VERSION ""

NS_ :

BS_:

BU_: GW MHU IPC CCU
VAL_TABLE_ MHU_BTPairing 3 "BT Phone and Media" 2 "BT Phone" 1 "Apple CarPlay" 0 "Not active No connetced" ;
VAL_TABLE_ MHU_MaintenanceEvent 0 "No Maintenance Event" 1 " Maintenance Reminder " 2 "Reserved" 3 "Invalid" ;
VAL_TABLE_ MHU_Arrow 1 "DEPART(Start driving Used before accurate location or orientation is known)" 2 "NAME_CHANGE(Indicate a street name change without turn)" 3 "KEEP LEFT( Keep Left. Usually for bifurcations or other smooth maneuvers(compare to Slight Left Turn)" 4 "KEEP RIGHT( Keep right. Usually for bifurcations or other smooth maneuvers(compare to Slight rightTurn))" 5 "SLIGHT TURN _RIGHT(Make a 10-45 degree RIGHT turn)" 6 "SLIGHT TURN _LEFT(Make a 10-45 degree LEFTturn)" 7 "TURN _RIGHT(Make a 45-135 degree RIGHT turn)" 8 "TURN _LEFT(Make a 45-135 degree LEFT turn)" 9 "TURN _RIGHT_END(At the end of the road，turn right)" 10 "TURN _LEFT_END(At the end of the road，turn left)" 11 "SHARP_TURN_RIGHT(Make a 135-175 degree RIGHT turn)" 12 "SHARP_TURN_LEFT(Make a 135-175 degree LEFT turn)" 13 "U TURN_RIGHT(Make a 180 dearee RIGHT tum onto the same road)" 14 "U TURN_LEFT(Make a 180 dearee LEFT tum onto the same road)" 15 "ON RAMP_RIGHT(Take an RIGHT on-ramp onto a major road)" 16 "ON RAMP_LEFT(Take an LEFT on-ramp onto a major road)" 17 "OFF RAMP_RIGHT(Take an RIGHT off-ramp onto a major road)" 18 "OFF RAMP_LEFT(Take an LEFT off-ramp onto a major road)" 19 "FORK_RIGHT(Take a RIGHT fork while on a ramp)" 20 "FORK__LEFT(Take a LEFT fork while on a ramp)" 21 "MERGE(Merge with another road)" 22 "STRAIGHT(Indicates a potentially confusing intersection, in which the user is to proceed straight)" 23 "CONTINUE(Continue tp follow the road the vehicle is currently on)" 24 "FERRY_BOAT(Board a boat ferry)" 25 "ENTER FERRY" 26 "EXIT FERRY" 27 "CHANGE FERRY(Board a boat ferry)" 28 "FERRY_TRAIN(Board a train ferry(Google Maps display no icon))" 29 "CHANGE HIGH WAY _1( Change Highway. Highway to highway change with plied or unknown side Of the road)" 30 "CHANGE HIGH WAY _2( Change Highway. Highway to highway change with plied or unknown side Of the road)" 31 "CHANGE HIGH WAY _3( Change Highway Right. Highway to highway change from the right side of the road)" ;
VAL_TABLE_ MHU_SET_Second 63 "Invalid" ;
VAL_TABLE_ MHU_SET_Min 63 "Invalid" ;
VAL_TABLE_ MHU_SET_Hour 31 "Invalid" ;
VAL_TABLE_ MHU_SET_Day 0 "Invalid" ;
VAL_TABLE_ MHU_SET_Month 15 "Invalid" ;
VAL_TABLE_ MHU_SET_Year 255 "Invalid" ;
VAL_TABLE_ MHU_St_DimmingIPC 15 "Invalid" 14 "Level 15" 13 "Level 14" 12 "Level 13" 11 "Level 12" 10 "Level 11" 9 "Level 10" 8 "Level 9" 7 "Level 8" 6 "Level 7" 5 "Level 6" 4 "Level 5" 3 "Level 4" 2 "Level 3" 1 "Level 2" 0 "Level 1" ;
VAL_TABLE_ MHU_FavoriteFlag 1 "Active" 0 "Not active" ;
VAL_TABLE_ MHU_AMRadioFrequanceValue 16383 "Invalid" ;
VAL_TABLE_ MHU_FMRadioFrequanceValue 1023 "Invalid" ;
VAL_TABLE_ MHU_SourceStationMode_Reserved 15 "Resevered" 14 "Resevered" 13 "Resevered" 12 "Resevered" 11 "Resevered" 10 "Resevered" 9 "Resevered" 8 "AndroidAuto" 7 "Carplay" 6 "USB Picture" 5 "USB Vedio" 4 "USB Music" 3 "BT Music" 2 "FM" 1 "AM" 0 "None" ;
VAL_TABLE_ MHU_Route_Reserved 1 "ON" 0 "OFF" ;
VAL_TABLE_ MHU_MediaType 15 "Invaild" 8 "FM" 7 "AM" 6 "MUSIC" 5 "VIDEO" 4 "IMAGE" 3 "BT" 2 "AndroidAuto" 1 "CarPlay" 0 "None" ;
VAL_TABLE_ MHU_MediaStatus_Reserved 3 "Invaild" 2 "pause" 1 "playing" 0 "unready" ;
VAL_TABLE_ MHU_PhoneStatus 15 "Invalid" 8 "Hold current call" 7 "Missed call from" 6 "MUTE" 5 "ACTIVE" 4 "INCOMING" 3 "ALERTING" 2 "DIALING" 1 "IDLE" 0 "DISCONNECTED" ;
VAL_TABLE_ MHU_NaviType 3 "Invalid" 2 "AndroidAuto" 1 "CarPlay" 0 "Local" ;
VAL_TABLE_ MHU_NaviStatus 1 "Navigating" 0 "not Navigating" ;
VAL_TABLE_ MHU_Destination_Reachsts 3 "DESTINATION_RIGHT(Indicated arrival at destination,Destination is on right)" 2 "DESTINATION__LEFT(Indicated arrival at destination,Destination is on rleft)" 1 "DESTINATION_not reached(Arrive End Of Navigation Navigation has completed, but the rest of the journey will need to use another)" 0 "Inactive" ;
VAL_TABLE_ MHU_Compass 8 "SW" 7 "SE" 6 "S" 5 "W" 4 "NW" 3 "N" 2 "NE" 1 "E" 0 "inaction" ;
VAL_TABLE_ MHU_Roundabout 0 "Inactive" 1 "ROUNDABOUT_ENTER_RIGHT(Enter a large roundabout_RIGHT)" 2 "ROUNDABOUT_ENTER__LEFT(Enter a large roundabout_LEFT)" 3 "ROUNDABOUT_EXIT_RIGHT(Exit a large roundabout_RIGHT)" 4 "ROUNDABOUT_EXIT__LEFT(Exit a large roundabout__LEFT)" 5 "ROUNDABOUT_RIGHT1(Turn Angle（In Degreen）:1-67)" 6 "ROUNDABOUT_RIGHT2(Turn Angle（In Degreen）:68-112)" 7 "ROUNDABOUT_RIGHT3(Turn Angle（In Degreen）:113-157)" 8 "ROUNDABOUT_RIGHT4(Turn Angle（In Degreen）:158-202)" 9 "ROUNDABOUT_RIGHT5(Turn Angle（In Degreen）:203-247)" 10 "ROUNDABOUT_RIGHT6(Turn Angle（In Degreen）:248-292)" 11 "ROUNDABOUT_RIGHT7(Turn Angle（In Degreen）:293-337)" 12 "ROUNDABOUT_RIGHT8(Turn Angle（In Degreen）:338-360)" 13 "ROUNDABOUT_RIGHT9" 14 "ROUNDABOUT_RIGHT10" 15 "ROUNDABOUT_RIGHT11" 16 "ROUNDABOUT_RIGHT12" 17 "ROUNDABOUT_RIGHT13" 18 "ROUNDABOUT_RIGHT14" 19 "ROUNDABOUT_RIGHT15" 20 "ROUNDABOUT_RIGHT16" 21 "ROUNDABOUT_RIGHT17" 22 "ROUNDABOUT_RIGHT18" 23 "ROUNDABOUT_RIGHT19" 24 "ROUNDABOUT_LEFT1(Turn Angle（In Degreen）:1-67)" 25 "ROUNDABOUT_LEFT2(Turn Angle（In Degreen）:68-112)" 26 "ROUNDABOUT_LEFT3(Turn Angle（In Degreen）:113-157)" 27 "ROUNDABOUT_LEFT4(Turn Angle（In Degreen）:158-202)" 28 "ROUNDABOUT_LEFT5(Turn Angle（In Degreen）:203-247)" 29 "ROUNDABOUT_LEFT6(Turn Angle（In Degreen）:248-292)" 30 "ROUNDABOUT_LEFT7(Turn Angle（In Degreen）:293-337)" 31 "ROUNDABOUT_LEFT8(Turn Angle（In Degreen）:338-360)" 32 "ROUNDABOUT_LEFT9" 33 "ROUNDABOUT_LEFT10" 34 "ROUNDABOUT_LEFT11" 35 "ROUNDABOUT_LEFT12" 36 "ROUNDABOUT_LEFT13" 37 "ROUNDABOUT_LEFT14" 38 "ROUNDABOUT_LEFT15" 39 "ROUNDABOUT_LEFT16" 40 "ROUNDABOUT_LEFT17" 41 "ROUNDABOUT_LEFT18" 42 "ROUNDABOUT_LEFT19" ;
VAL_TABLE_ MHU_USBConnect 1 "USB connect" 0 "No USB connect" ;
VAL_TABLE_ MHU_MEDIA_MUTE 1 "Active" 0 "Not active" ;
VAL_TABLE_ MHU_PollutionReq 1 "Active" 0 "Inactive" ;
VAL_TABLE_ MHU_BSD_On 3 "Signal invalid" 2 "inactive" 1 "ON" 0 "OFF" ;
VAL_TABLE_ MHU_BSD_sens_Reserved 7 "invalid" 6 "Reserved" 5 "Reserved" 4 "Reserved" 3 "Inactive" 2 "Late" 1 "Normal" 0 "Early" ;
VAL_TABLE_ MHU_BSD_AudWarning 3 "Signal invalid" 2 "inactive" 1 "ON" 0 "OFF" ;
VAL_TABLE_ MHU_RCTA_On 3 "Signal invalid" 2 "inactive" 1 "ON" 0 "OFF" ;
VAL_TABLE_ MHU_RCTA_sens_Reserved 7 "invalid" 6 "Reserved" 5 "Reserved" 4 "Reserved" 3 "Inactive" 2 "Late" 1 "Normal" 0 "Early" ;
VAL_TABLE_ MHU_PA_On 3 "Signal invalid" 2 "inactive" 1 "ON" 0 "OFF" ;
VAL_TABLE_ MHU_DOW_Mode 3 "Signal invalid" 2 "inactive" 1 "ON" 0 "OFF" ;
VAL_TABLE_ MHU_DOW_sens_Reserved 7 "invalid" 6 "Reserved" 5 "Reserved" 4 "Reserved" 3 "Inactive" 2 "Late" 1 "Normal" 0 "Early" ;
VAL_TABLE_ MHU_DOW_AudWarning 3 "Signal invalid" 2 "inactive" 1 "ON" 0 "OFF" ;
VAL_TABLE_ MHU_SET_DoorSpeedLock 15 "Invalid" 14 "Reserved" 13 "Reserved" 12 "Reserved" 11 "Reserved" 10 "Reserved" 9 "Reserved" 8 "Reserved" 7 "Reserved" 6 "Inactive" 5 "25KMH" 4 "20KMH" 3 "15KMH" 2 "10KMH" 1 "5KMH" 0 "OFF" ;
VAL_TABLE_ MHU_SET_RemoteDoorUnlock_reserve 3 "Signal invalid" 2 "Reserved" 1 "All doors" 0 "Driver door" ;
VAL_TABLE_ MHU_SET_RemoteLockFeedback 7 "Signal Invalid" 6 "Reserved" 5 "Reserved" 4 "inactive" 3 "Horn" 2 "Light" 1 "Light/Horn" 0 "OFF" ;
VAL_TABLE_ MHU_SET_AutoUnlockDoor 7 "Invalid" 6 "Reserved" 5 "Reserved" 4 "Reserved" 3 "Reserved" 2 "Inactive" 1 "ON" 0 "OFF" ;
VAL_TABLE_ MHU_SET_MirrorAuto_reserved 3 "Signal invalid" 2 "Reserved" 1 "ON" 0 "OFF" ;
VAL_TABLE_ MHU_Anti_theftAlarmSet 7 "Invalid" 6 "Reserved" 5 "Reserved" 4 "inactive" 3 "Light/Horn" 2 "Horn" 1 "Light" 0 "OFF" ;
VAL_TABLE_ MHU_TriggerReadKey 3 "Signal Invalid" 2 "Reserved" 1 "Request" 0 "No Request" ;
VAL_TABLE_ MHU_Heatrearglass_Set 0 "OFF" 1 "ON" 2 "No action" 3 "Invalid" ;
VAL_TABLE_ MHU_SET_DayTimeRunningLight_rese 3 "Signal invalid" 2 "Reserved" 1 "ON" 0 "OFF" ;
VAL_TABLE_ MHU_SET_FollowMeHomeTime 7 "Invalid" 6 "Inactive" 5 "Reserved" 4 "120s" 3 "90s" 2 "60s" 1 "30s" 0 "OFF" ;
VAL_TABLE_ Rolling_Counter_0x403 15 "Invalid" ;
VAL_TABLE_ MHU_SET_TCS_OnOff 0 "OFF (keep sending for 2 seconds)" 1 "ON (keep sending for 2 seconds)" 2 "No action" 3 "Invalid" ;
VAL_TABLE_ MHU_SET_DrivingModeSwitch 3 "sport mode (should be hold during 1 second)" 2 "normal mode (should be hold during 1 second)" 1 "eco mode (should be hold during 1 second)" 0 "no change request" ;
VAL_TABLE_ MHU_SET_RegenLevel 3 "No action" 2 "High" 1 "Low" 0 "none" ;
VAL_TABLE_ MHU_VCU_CreepDisable_stt 0 "No request" 1 "Creep Disable request" 2 "Reserved" 3 "Invalid" ;
VAL_TABLE_ MHU_HVACTurnON 0 "No request" 1 "ON" 2 "Reserved" 3 "Invalid" ;
VAL_TABLE_ MHU_ChargeScheduleSet 0 "Disabled" 1 "Enabled" 2 "No Action" 3 "Reserved" ;
VAL_TABLE_ MHU_ChargingRequest 0 "Reserved" 1 "Request scheduled start charging" 2 "Request stop" 3 "No effect" ;
VAL_TABLE_ MHU_ValetMode_Activation 0 "Inactive" 1 "Active" 254 "Reserved" 255 "Invalid" ;
VAL_TABLE_ MHU_CCU_AC_Button 3 "Invalid" 1 "Press" 0 "Release" ;
VAL_TABLE_ MHU_REC_Button 3 "Invalid" 1 "Press" 0 "Release" ;
VAL_TABLE_ MHU_SetBlowMode 7 "Invalid" 6 "Reserve" 5 "Reserve" 4 "Foot and window" 3 "Foot" 2 "foot and face" 1 "face" 0 "Inactive" ;
VAL_TABLE_ MHU_BlowerLevelSetting 9 "level 8" 8 "level 7" 7 "level 6" 6 "level 5" 5 "level 4" 4 "level 3" 3 "level 2" 2 "level 1" 1 "OFF" 0 "Inactive" ;
VAL_TABLE_ MHU_SetDriverTemp 63 "Invalid" 16 "level 8" 15 "level 7" 14 "level 6" 13 "level 5" 12 "level 4" 11 "level 3" 10 "level 2" 9 "level 1" 8 "level 8" 7 "level 7" 6 "level 6" 5 "level 5" 4 "level 4" 3 "level 3" 2 "level 2" 1 "level 1" 0 "Inactive" ;
VAL_TABLE_ MHU_ACM_Reserved 3 "Invalid" 1 "Active" 0 "Inactive" ;
VAL_TABLE_ MHU_FrontDefrostReq_Reserved 3 "Invalid" 1 "Active" 0 "Inactive" ;
VAL_TABLE_ Rolling_Counter_0x422 15 "Invalid" ;
VAL_TABLE_ MHU_STAT_DateTimeFormat 3 "Signal invalid" 2 "Reserved" 1 "12H" 0 "24H" ;
VAL_TABLE_ MHU_DISPLAY_STATUS 0 "OFF" 1 "ON" 2 "Reserved" 3 "Invalid" ;
VAL_TABLE_ MHU_STAT_Language 31 "Signal invalid" 30 "Reserved" 29 "Reserved" 28 "Reserved" 27 "Reserved" 26 "Reserved" 25 "Reserved" 24 "Reserved" 23 "Reserved" 22 "Reserved" 21 "Reserved" 20 "Reserved" 19 "Reserved" 18 "Reserved" 17 "Reserved" 16 "Reserved" 15 "Reserved" 14 "Reserved" 13 "Reserved" 12 "Reserved" 11 "Reserved" 10 "Reserved" 9 "Reserved" 8 "Reserved" 7 "Reserved" 6 "Cambodia" 5 "Laos" 4 "Indonesian" 3 "Thai" 2 "Malay" 1 "English" 0 "Vietnamese" ;
VAL_TABLE_ TBOX_STAT_TerminalReq 7 "Signal invalid" 6 "No action" 5 "Reserved" 4 "SW Update OTA" 3 "Engine start (eMotor running)" 2 "ON (Driver Present)" 1 "ACC (Park)" 0 "OFF(Comfort Enable)" ;
VAL_TABLE_ REQ_ConsumerControlAudioVolumeCo 7 "signal invalid" 6 "Reserved" 5 "Reserved" 4 "Reserved" 3 "Reserved" 2 "Level 2" 1 "Level 1" 0 "No Reduction" ;
VAL_TABLE_ MHU_BCM_reqTrunk 3 "Signal invalid" 2 "No action" 1 "Open" 0 "Close reserved" ;
VAL_TABLE_ MHU_BCM_RemoteDoorCtrl 3 "Signal invalid" 2 "No action" 1 "Unlock" 0 "Lock" ;
VAL_TABLE_ MHU_APM_ReqWindow 2 "Open(Bottom) " 1 "Closed(Top)" 0 "No action" ;
VAL_TABLE_ MHU_SetHighBeam 1 "Request flashing" 2 "No request" 3 "Invalid" ;
VAL_TABLE_ MHU_SetHornOnOff 0 "OFF" 1 "ON" 2 "No action" 3 "Invalid" ;
VAL_TABLE_ MHU_SetLowBeam 0 "OFF" 1 "ON" 2 "No action" 3 "Invalid" ;
VAL_TABLE_ Rolling_Counter_0x432 15 "Invalid" ;
VAL_TABLE_ MHU_FOTA_State 0 "INIT" 1 "NORMAL" 2 "FOTA FLASHING" 3 "FOTA-SUSPENDED" 4 "FAIL-SAFE-ERROR" 5 "SHUTDOWN" 6 "REMOTE DIAGNOSTICS" 7 "Invalid" ;
VAL_TABLE_ XGW_FOTA_StateConfirm 0 "INIT" 1 "NORMAL" 2 "FOTA FLASHING" 3 "FOTA-SUSPENDED" 4 "FAIL-SAFE-ERROR" 5 "SHUTDOWN" 6 "REMOTE DIAGNOSTICS" 7 "Invalid" ;
VAL_TABLE_ BMS_MHU_Auth_Sts 2 "failed " 1 "pass " 0 "init" ;
VAL_TABLE_ IPC_Sec 63 "Invalid" ;
VAL_TABLE_ IPC_Min 63 "Invalid" ;
VAL_TABLE_ IPC_Hour 31 "Invalid" ;
VAL_TABLE_ IPC_Day 31 "Invalid" ;
VAL_TABLE_ IPC_Month 15 "Invalid" ;
VAL_TABLE_ IPC_Year 255 "Invalid" ;
VAL_TABLE_ IPC_SelfCheckStatus 1 "self-check finish" 0 "self-checking" ;
VAL_TABLE_ Rolling_Counter_0x20C 15 "Invalid" ;
VAL_TABLE_ IPC_ODO 1048575 "Invalid" ;
VAL_TABLE_ IPC_TripA 65535 "Invalid" ;
VAL_TABLE_ IPC_AverageSpeedTripA 4095 "Invalid" ;
VAL_TABLE_ IPC_AverageConsumptionTripA 1023 "Invalid" ;
VAL_TABLE_ IPC_ParkBrakeSts 3 "Invalid" 2 "Reserved" 1 "Applied" 0 "Released" ;
VAL_TABLE_ IPC_VehSpd 32767 "Invalid" ;
VAL_TABLE_ IPC_TripB 65535 "Invalid" ;
VAL_TABLE_ IPC_AverageSpeedTripB 4095 "Invalid" ;
VAL_TABLE_ IPC_AverageConsumptionTripB 1023 "Invalid" ;
VAL_TABLE_ IPC_TripAuto 65535 "Invalid" ;
VAL_TABLE_ IPC_AverageSpeedTripAuto 4095 "Invalid" ;
VAL_TABLE_ IPC_AverageConsumptionTripAuto 1023 "Invalid" ;
VAL_TABLE_ IPC_TireLearningReq_reserved 3 "Reserved" 2 "Reserved" 1 "Requset" 0 "No requset" ;
VAL_TABLE_ IPC_TireResetReq 3 "Reserved" 2 "Reserved" 1 "Requset to reset" 0 "No requset" ;
VAL_TABLE_ IPC_DimmingIPCLevel 15 "Invalid" 14 "Level 15" 13 "Level 14" 12 "Level 13" 11 "Level 12" 10 "Level 11" 9 "Level 10" 8 "Level 9" 7 "Level 8" 6 "Level 7" 5 "Level 6" 4 "Level 5" 3 "Level 4" 2 "Level 3" 1 "Level 2" 0 "Level 1" ;
VAL_TABLE_ CCU_TemperatureGearSts 63 "Invalid" 16 "level 8" 15 "level 7" 14 "level 6" 13 "level 5" 12 "level 4" 11 "level 3" 10 "level 2" 9 "level 1" 8 "level 8" 7 "level 7" 6 "level 6" 5 "level 5" 4 "level 4" 3 "level 3" 2 "level 2" 1 "level 1" 0 "Inactive" ;
VAL_TABLE_ CCU_BlowMode_Sts 7 "Invalid" 6 "Reserve" 4 "Foot and window" 3 "Foot" 2 "Foot and Face" 1 "Face" 0 "OFF" ;
VAL_TABLE_ CCU_Circulation_Sts 1 "Internal circulation" 0 "Outer circulation" ;
VAL_TABLE_ CCU_AC_Req 3 "Invalid" 2 "Reserved" 1 "Requset" 0 "No requset" ;
VAL_TABLE_ CCU_AC_Sts 1 "ON" 0 "OFF" ;
VAL_TABLE_ CCU_BlowerLevelSts 8 "level 8" 7 "level 7" 6 "level 6" 5 "level 5" 4 "level 4" 3 "level 3" 2 "level 2" 1 "level 1" 0 "OFF" ;
VAL_TABLE_ CCU_FrontDefrostSts 1 "On" 0 "Off" ;
VAL_TABLE_ CCU_PTC_Req 3 "Invalid" 2 "Reserved" 1 "Requset" 0 "No requset" ;
VAL_TABLE_ CCU_PTC_Temperature 1023 "Invaild" ;
VAL_TABLE_ CCU_CompSpdMEAS_Comp 8191 "Invalid" ;
VAL_TABLE_ CCU_PollutionSts 1 "ON" 0 "OFF" ;
VAL_TABLE_ CCU_ExternalTemperature 255 "Invaild" ;
VAL_TABLE_ CCU_evaporator_Temperature 31 "Invalid" ;
VAL_TABLE_ CCU_ExternalTemperatureFailSts 1 "invalid" 0 "valid" ;
VAL_TABLE_ USS_WorkSts 0 "Rear PAS Off" 1 "Rear PAS On" ;
VAL_TABLE_ USS_FrnSysSts_reserved 0 "Disable" 1 "Enable" 2 "Active" 3 "Failed" ;
VAL_TABLE_ USS_RearSysSts_reserved 0 "OFF" 1 "Enable" 2 "Active" 3 "Temporary Fault" 4 "Permanent Fault" ;
VAL_TABLE_ USS_SndCadComm 0 "Tone 0 - No warning" 1 "Front Level 1" 2 "Front Level 2" 3 "Front Level 3" 4 "Front Level 4" 5 "Front Level 5" 6 "Rear Level 1" 7 "Rear Level 2" 8 "Rear Level 3" 9 "Rear Level 4" 10 "Rear Level 5" 11 "Rear Level 6" 12 "Tone 10 - PAS & APA Check Normal Warning" 13 "Tone 11 - PAS & APA Check Fault Warning" 14 "Tone 12 - APA Warning tone/ Tone 12 -RRS Warning tone" 15 "Front and Rear Alternate alarm" ;
VAL_TABLE_ USS_LFDistance_reserved 0 "No obstacle" 1 "Zone 1" 2 "Zone 2" 3 "Zone3" ;
VAL_TABLE_ USS_RFDistance_reserved 0 "No obstacle" 1 "Zone 1" 2 "Zone 2" 3 "Zone3" ;
VAL_TABLE_ USS_LRDistance 0 "No obstacle" 1 "Zone 1" 2 "Zone 2" 3 "Zone3" 15 "Invalid" ;
VAL_TABLE_ USS_LMRDistance 0 "No obstacle" 1 "Zone 1" 2 "Zone 2" 3 "Zone 3" 4 "Zone 4" 5 "Zone 5" 15 "Invalid" ;
VAL_TABLE_ USS_RMRDistance 0 "No obstacle" 1 "Zone 1" 2 "Zone 2" 3 "Zone 3" 4 "Zone 4" 5 "Zone 5" 15 "Invalid" ;
VAL_TABLE_ USS_RRDistance 0 "No obstacle" 1 "Zone 1" 2 "Zone 2" 3 "Zone3" 15 "Invalid" ;
VAL_TABLE_ USS_PrkAssSysSta 0 "True" 1 "Fault" ;
VAL_TABLE_ USS_FLSenSta_reserved 0 " Sensor Normal" 1 " Sensor Fault" ;
VAL_TABLE_ USS_FRSenSta_reserved 0 " Sensor Normal" 1 " Sensor Fault" ;
VAL_TABLE_ USS_RLSenSta 0 " Sensor Normal" 1 " Sensor Fault" ;
VAL_TABLE_ USS_RRSenSta 0 " Sensor Normal" 1 " Sensor Fault" ;
VAL_TABLE_ USS_RLMSenSta 0 " Sensor Normal" 1 " Sensor Fault" ;
VAL_TABLE_ USS_RRMSenSta 0 " Sensor Normal" 1 " Sensor Fault" ;
VAL_TABLE_ USS_SetSta 0 " Unavailable" 1 " Off " 2 " On " 3 " Unused and Reserved" ;
VAL_TABLE_ Rolling_Counter_0x128 15 "Invalid" ;
VAL_TABLE_ ADAS_RCTA_IndLeft 0 "Indicator output off" 1 "Indicator On(warning stage - 1)" 2 "Indicator flashing(warning stage - 2)" 3 "Reserved" ;
VAL_TABLE_ ADAS_RCTA_IndRight 0 "Indicator output off" 1 "Indicator On(warning stage - 1)" 2 "Indicator flashing(warning stage - 2)" 3 "Reserved" ;
VAL_TABLE_ ADAS_RCTA_SndWarn 0 "Sound Warning disable" 1 "Left Sound Warning enable" 2 "Right Sound Warning enable" 3 "Left and Right Sound Warning enable" ;
VAL_TABLE_ ADAS_RCTA_check 0 "Available" 1 "Temporarily not available" 2 "Permanently not available" 3 "signal invalid" ;
VAL_TABLE_ ADAS_RCTA_state 0 "OFF State" 1 "Stand by state" 2 "Armed state" 3 "Warning stage" ;
VAL_TABLE_ ADAS_RCTA_sens_Feed_Reserved 0 "Early" 1 "Normal" 2 "Late" 3 "signal invalid" ;
VAL_TABLE_ ADAS_RCTA_Mode_Feed 0 "Off" 1 "On" 2 "Reserved" 3 "signal invalid" ;
VAL_TABLE_ Rolling_Counter_0x133 15 "Invalid" ;
VAL_TABLE_ ADAS_BSD_check 0 "Available" 1 "Temporarily not available" 2 "Permanently not available" 3 "signal invalid" ;
VAL_TABLE_ ADAS_BSD_state 0 "OFF State" 1 "Stand by state" 2 "Armed state" 3 "Warning" ;
VAL_TABLE_ ADAS_BSD_AudChime_Feed 0 "Off" 1 "On" 2 "Reserved" 3 "signal invalid" ;
VAL_TABLE_ ADAS_BSD_IndLeft 0 "Indicator output off" 1 "Indicator On(warning stage - 1)" 2 "Indicator flashing(warning stage - 2)" 3 "Sensor Fault" ;
VAL_TABLE_ ADAS_BSD_IndRight 0 "Indicator output off" 1 "Indicator On(warning stage - 1)" 2 "Indicator flashing(warning stage - 2)" 3 "Sensor Fault" ;
VAL_TABLE_ ADAS_BSD_SndWarn 0 "Sound Warning disable" 1 "Sound Warning enable" ;
VAL_TABLE_ ADAS_BSD_Mode_Feed 0 "Off" 1 "On" 2 "Reserved" 3 "signal invalid" ;
VAL_TABLE_ ADAS_BSD_sens_Feed 0 "Early" 1 "Normal" 2 "Late" 3 "signal invalid" ;
VAL_TABLE_ Rolling_Counter_0x352 15 "Invalid" ;
VAL_TABLE_ ADAS_DOW_Warn 0 "No Info" 1 "Left Warning" 2 "Right Warning" 3 "Left & Right Warning" ;
VAL_TABLE_ ADAS_DOW_SndWarn 0 "Sound Warning disable" 1 "Left Sound Warning enable" 2 "Right Sound Warning enable" 3 "Left and Right Sound Warning enable" ;
VAL_TABLE_ ADAS_DOW_state 0 "OFF State" 1 "Stand by state" 2 "Armed state" 3 "Warning stage" ;
VAL_TABLE_ ADAS_DOW_IndLeft 0 "Indicator output off" 1 "Indicator On(warning stage - 1)" 2 "Indicator flashing(warning stage - 2)" 3 "Sensor Fault" ;
VAL_TABLE_ ADAS_DOW_IndRight 0 "Indicator output off" 1 "Indicator On(warning stage - 1)" 2 "Indicator flashing(warning stage - 2)" 3 "Sensor Fault" ;
VAL_TABLE_ ADAS_DOW_sens_Feed_Reserved 0 "Early" 1 "Normal" 2 "Late" 3 "signal invalid" ;
VAL_TABLE_ ADAS_DOW_Mode_Feed 3 "signal invalid" 2 "Reserved" 1 "ON" 0 "OFF" ;
VAL_TABLE_ ADAS_DOW_AudChime_Feed 0 "Off" 1 "On" 2 "Reserved" 3 "signal invalid" ;
VAL_TABLE_ ADAS_DOW_check 0 "Available" 1 "Temporarily not available" 2 "Permanently not available" 3 "signal invalid" ;
VAL_TABLE_ Rolling_Counter_0x4C0 15 "Invalid" ;
VAL_TABLE_ ADAS_Warning_Flag_1 0 "No Error" 1 "Error" ;
VAL_TABLE_ ADAS_Warning_Flag_2 0 "No Error" 1 "Error" ;
VAL_TABLE_ ADAS_Warning_Flag_3 0 "No Error" 1 "Error" ;
VAL_TABLE_ ADAS_Warning_Flag_4 0 "No Error" 1 "Error" ;
VAL_TABLE_ ADAS_Warning_Flag_5 0 "No Error" 1 "Error" ;
VAL_TABLE_ ADAS_Warning_Flag_6 0 "No Error" 1 "Error" ;
VAL_TABLE_ ADAS_Warning_Flag_7 0 "No Error" 1 "Error" ;
VAL_TABLE_ ADAS_Warning_Flag_8 0 "No Error" 1 "Error" ;
VAL_TABLE_ ADAS_Warning_Flag_9 0 "No Error" 1 "Error" ;
VAL_TABLE_ ADAS_Warning_Flag_10 0 "No Error" 1 "Error" ;
VAL_TABLE_ ADAS_Warning_Flag_11 0 "No Error" 1 "Error" ;
VAL_TABLE_ ADAS_Warning_Flag_12 0 "No Error" 1 "Error" ;
VAL_TABLE_ ADAS_Warning_Flag_13 0 "No Error" 1 "Error" ;
VAL_TABLE_ ADAS_Warning_Flag_14 0 "No Error" 1 "Error" ;
VAL_TABLE_ ADAS_Warning_Flag_15 0 "No Error" 1 "Error" ;
VAL_TABLE_ ADAS_Warning_Flag_16 0 "No Error" 1 "Error" ;
VAL_TABLE_ ADAS_Warning_Flag_17 0 "No Error" 1 "Error" ;
VAL_TABLE_ ADAS_Warning_Flag_18 0 "No Error" 1 "Error" ;
VAL_TABLE_ ADAS_Warning_Flag_19 0 "No Error" 1 "Error" ;
VAL_TABLE_ ADAS_Warning_Flag_20 0 "No Error" 1 "Error" ;
VAL_TABLE_ ADAS_Warning_Flag_21 0 "No Error" 1 "Error" ;
VAL_TABLE_ ADAS_Warning_Flag_22 0 "No Error" 1 "Error" ;
VAL_TABLE_ ADAS_Warning_Flag_23 0 "No Error" 1 "Error" ;
VAL_TABLE_ ADAS_Warning_Flag_24 0 "No Error" 1 "Error" ;
VAL_TABLE_ ADAS_Warning_Flag_25 0 "No Error" 1 "Error" ;
VAL_TABLE_ ADAS_Warning_Flag_26 0 "No Error" 1 "Error" ;
VAL_TABLE_ ADAS_Warning_Flag_27 0 "No Error" 1 "Error" ;
VAL_TABLE_ ADAS_Warning_Flag_28 0 "No Error" 1 "Error" ;
VAL_TABLE_ Rolling_Counter_0x353 15 "Invalid" ;
VAL_TABLE_ ADAS_RadarRight_Cal_Status 0 "No Calib" 1 "Calib OK" ;
VAL_TABLE_ ADAS_RadarLeft_Cal_Status 0 "No Calib" 1 "Calib OK" ;
VAL_TABLE_ ADAS_RadarRight_DynaCal_Status 0 "In Calibrating" 1 "The absolute value of calibration angle is greater than 6 degrees" ;
VAL_TABLE_ ADAS_RadarLeft_DynaCal_Status 0 "In Calibrating" 1 "The absolute value of calibration angle is greater than 6 degrees" ;
VAL_TABLE_ ADAS_MasterSRR_check 0 "Available" 1 "Temporarily not available" 2 "Permanently not available" ;
VAL_TABLE_ ADAS_SlaveSRR_check 0 "Available" 1 "Temporarily not available" 2 "Permanently not available" ;
VAL_TABLE_ ADAS_CalSensorMasterProgress 255 "Invaild" ;
VAL_TABLE_ ADAS_CalSensorSlaverProgress 255 "Invalid" ;
VAL_TABLE_ Rolling_Counter_0x85 15 "Invalid" ;
VAL_TABLE_ ACM_Crash_Sts 3 "Invalid Value" 2 "Invalid Value" 1 "Crash_Detected" 0 "No_Event" ;
VAL_TABLE_ ACM_Airbag_Deployment_Status 3 "Invalid Value" 2 "Invalid Value" 1 "Airbag_Deployment" 0 "No_Airbag_Deployment" ;
VAL_TABLE_ ACM_Crash_Intensity 7 "Invalid_Value" 6 "Invalid_Value" 5 "Invalid_Value" 4 "Invalid_Value" 3 "Crash_Intensity_3" 2 "Crash_Intensity_2" 1 "Crash_Intensity_1" 0 "No_Crash" ;
VAL_TABLE_ ACM_Front_Crash 3 "Invalid Value" 2 "Invalid Value" 1 "Front_Crash_Detected" 0 "No_Event" ;
VAL_TABLE_ ACM_DriverSide_Crash 3 "Invalid Value" 2 "Invalid Value" 1 "Driverside_Crash_Detected" 0 "No_Event" ;
VAL_TABLE_ ACM_PassSide_Crash 3 "Invalid Value" 2 "Invalid Value" 1 "PassSide_Crash_Detected" 0 "No_Event" ;
VAL_TABLE_ ACM_Rear_Crash 3 "Invalid Value" 2 "Invalid Value" 1 "Rear_Crash_Detected" 0 "No_Event" ;
VAL_TABLE_ ACM_Rollover_Crash 3 "Invalid Value" 2 "Invalid Value" 1 "Rollover_Crash_Detected" 0 "No_Event" ;
VAL_TABLE_ Rolling_Counter_0x381 15 "Invalid" ;
VAL_TABLE_ ACM_Seat_Occupancy_Passenger 3 "Failure" 2 "Not_Available" 1 "Seat Occupied" 0 "Seat_Not_Occupied" ;
VAL_TABLE_ ACM_Seat_Occupancy_2nd_Row_Dri_r 3 "Failure" 2 "Not_Available" 1 "Seat Occupied" 0 "Seat_Not_Occupied" ;
VAL_TABLE_ ACM_Seat_Occupancy_2nd_Row_Pas_r 3 "Failure" 2 "Not_Available" 1 "Seat Occupied" 0 "Seat_Not_Occupied" ;
VAL_TABLE_ ACM_Seat_Occupancy_2nd_Row_Mid_r 3 "Failure" 2 "Not_Available" 1 "Seat Occupied" 0 "Seat_Not_Occupied" ;
VAL_TABLE_ ACM_Seat_Belt_Status_Passenger 3 "Failure" 2 "Not_Available" 1 "Buckled" 0 "Not_buckled" ;
VAL_TABLE_ ACM_Seat_Belt_Status_Driver 3 "Failure" 2 "Not_Available" 1 "Buckled" 0 "Not_buckled" ;
VAL_TABLE_ ACM_Seat_Belt_Status_2nd_Row_Dri 3 "Failure" 2 "Not_Available" 1 "Buckled" 0 "Not_buckled" ;
VAL_TABLE_ ACM_Seat_Belt_Status_2nd_Row_Mid 3 "Failure" 2 "Not_Available" 1 "Buckled" 0 "Not_buckled" ;
VAL_TABLE_ ACM_Seat_Belt_Status_2nd_Row_Pas 3 "Failure" 2 "Not_Available" 1 "Buckled" 0 "Not_buckled" ;
VAL_TABLE_ ACM_Seat_Belt_Status_3rd_Row_Dri 3 "Failure" 2 "Not_Available" 1 "Buckled" 0 "Not_buckled" ;
VAL_TABLE_ ACM_Seat_Belt_Status_3rd_Row_Pas 3 "Failure" 2 "Not_Available" 1 "Buckled" 0 "Not_buckled" ;
VAL_TABLE_ Rolling_Counter_0x488 15 "Invalid" ;
VAL_TABLE_ ACM_Malfunction 0 "ACM_Failure" 1 "ACM_Normal_Operation" ;
VAL_TABLE_ ACM_Pre_Drive_Check 0 "ACM_Pre_Drive_Check" 1 "ACM_Normal_Operation" ;
VAL_TABLE_ ACM_in_Plant_Mode 0 "ACM_in_Plant_Mode" 1 "ACM_in_Normal_Mode" ;
VAL_TABLE_ ACM_PAB_Suppression 0 "Not_Suppressed" 1 "Suppressed" 2 "Function Failure" 3 "Invalid_Value" ;
VAL_TABLE_ ACM_Airbag_Disabled 0 "ACM_AirBag_Disabled" 1 "ACM_Normal_Operation" ;
VAL_TABLE_ ACM_Development_Calibration 0 "ACM_Dev_Calibrated" 1 "ACM_Normal_Operation" ;
VAL_TABLE_ ACM_In_Disposal_Mode 0 "ACM_In_Disposal_Mode" 1 "ACM_Normal_Operation" ;
VAL_TABLE_ ACM_Seatbelt_Reminder_Request 0 "Seatbelt reminder NOT activated" 1 "Seatbelt reminder activated" ;
VAL_TABLE_ ACM_SBR_Chime_Req 0 "No Active Chime" 1 "Active Chime" ;
VAL_TABLE_ ACM_SBR_Blinking_Req 0 "No Blinking" 1 "Blinking 1Hz" ;
VAL_TABLE_ Rolling_Counter_0x105 15 "Invalid" ;
VAL_TABLE_ BCM_STAT_TrunkAjar 3 "Signal invalid" 2 "Reserved" 1 "Opened" 0 "Closed" ;
VAL_TABLE_ BCM_STAT_DoorAjarDriver 3 "Signal invalid" 2 "Reserved" 1 "Opened" 0 "Closed" ;
VAL_TABLE_ BCM_STAT_DoorAjarPassenger 3 "Signal invalid" 2 "Reserved" 1 "Opened" 0 "Closed" ;
VAL_TABLE_ BCM_STAT_DoorAjarRL 3 "Signal invalid" 2 "Reserved" 1 "Opened" 0 "Closed" ;
VAL_TABLE_ BCM_STAT_DoorAjarRR 3 "Signal invalid" 2 "Reserved" 1 "Opened" 0 "Closed" ;
VAL_TABLE_ BCM_STAT_BonnetAjar_reserved 3 "Signal invalid" 2 "Reserved" 1 "Opened" 0 "Closed" ;
VAL_TABLE_ Rolling_Counter_0x106 15 "Invalid" ;
VAL_TABLE_ BCM_HighBeamSts 0 "OFF" 1 "ON" 2 "Fault (Reserved)" 3 "Signal Invalid" ;
VAL_TABLE_ BCM_LowBeamSts 0 "OFF" 1 "ON" 2 "Fault (Reserved)" 3 "Signal Invalid" ;
VAL_TABLE_ BCM_PosLmpSts 0 "OFF" 1 "ON" 2 "Fault (Reserved)" 3 "Signal Invalid" ;
VAL_TABLE_ BCM_TurnIndicatorSts 0 "OFF" 1 "Left On" 2 "Right On" 3 "Left and Right On" ;
VAL_TABLE_ BCM_DayRunningLampSts_reserved 0 "OFF" 1 "ON" 2 "Fault (Reserved)" 3 "Signal Invalid" ;
VAL_TABLE_ BCM_ReverseLightSts 0 "OFF" 1 "ON" 2 "Fault (Reserved)" 3 "Signal Invalid" ;
VAL_TABLE_ BCM_StopLightSts 0 "OFF" 1 "ON" 2 "Fault (Reserved)" 3 "Signal Invalid" ;
VAL_TABLE_ BCM_Fr_Dimming_dome_lampSts 0 "OFF" 1 "ON" 2 "Fault (Reserved)" 3 "Signal Invalid" ;
VAL_TABLE_ BCM_Heated_rearglass 0 "OFF" 1 "ON" 2 "Fault (Reserved)" 3 "Signal Invalid" ;
VAL_TABLE_ BCM_BsdLightSts 0 "OFF" 1 "Left On" 2 "Right On" 3 "Left and Right On" ;
VAL_TABLE_ BCM_STAT_LightActivation 7 "Signal invalid" 6 "Reserved" 5 "Reserved" 4 "Reserved" 3 "AutoLight" 2 "LowBeam" 1 "PositionLight" 0 "OFF" ;
VAL_TABLE_ BCM_STAT_InteriorLight 3 "Signal invalid" 2 "Reserved" 1 "ON" 0 "OFF" ;
VAL_TABLE_ Rolling_Counter_0x10a 15 "Invalid" ;
VAL_TABLE_ BCM_LVTop_up 1 "start Top up" 0 "stop Top up" ;
VAL_TABLE_ Rolling_Counter_0x112 15 "Invalid" ;
VAL_TABLE_ STAT_Terminal 7 "Signal invalid" 6 "Reserved" 5 "Reserved" 4 "SW update OTA (Not used in VFe34)" 3 "Engine start (eMotor running)" 2 "ON (Driver Present)" 1 "ACC (Park)" 0 "OFF(Comfort Enable)" ;
VAL_TABLE_ STAT_CL30s_L_Reserved 3 "Signal invalid" 2 "Failure" 1 "ON" 0 "OFF" ;
VAL_TABLE_ Rolling_Counter_0x12f 15 "Invalid" ;
VAL_TABLE_ ST_KL_KEY_VLD 15 "Signal invalid" 14 "Error" 13 "Reserved" 12 "Reserved" 11 "Reserved" 10 "Reserved" 9 "Reserved" 8 "Reserved" 7 "Reserved" 6 "Reserved" 5 "Key 10sec delay" 4 "Key valid IR" 3 "Key valid AR" 2 "Key search activ" 1 "Key invalid" 0 "Init" ;
VAL_TABLE_ ST_SSP 3 "Signal invalid" 2 "Reserve" 1 "SSB pressed" 0 "SSB not pressed" ;
VAL_TABLE_ BCM_IMMO_Sts 2 "failed " 1 "pass " 0 "init" ;
VAL_TABLE_ BCM_ACCRelayOutputSts 0 "Inactive" 1 "Active" 2 "Reserved" 3 "Signal Invalid" ;
VAL_TABLE_ BCM_IGN1RelayOutputSts 0 "Inactive" 1 "Active" 2 "Reserved" 3 "Signal Invalid" ;
VAL_TABLE_ BCM_ACCRelayFalutSts 0 "No Fault" 1 "Fault" 2 "Reserved" 3 "Signal Invalid" ;
VAL_TABLE_ BCM_IGN1RelayFalutSts 0 "No Fault" 1 "Fault" 2 "Reserved" 3 "Signal Invalid" ;
VAL_TABLE_ BCM_KEY_MatchSts 0 "No Match" 1 "Match Success" 2 "Match Failed" 3 "Matching" ;
VAL_TABLE_ PEPS_Lock_IGNNotOff_Alert 1 "Active" 0 "Inactive" ;
VAL_TABLE_ PEPS_CID_NotInside_Alert 1 "Active" 0 "Inactive" ;
VAL_TABLE_ PEPS_CID_Left_Alert 1 "Active" 0 "Inactive" ;
VAL_TABLE_ PEPS_RMKey_BatteryLow_Alert 1 "Active" 0 "Inactive" ;
VAL_TABLE_ PEPS_PressBrakePedal_Alert 1 "Active" 0 "Inactive" ;
VAL_TABLE_ PEPS_Shift_Position_Alert 1 "Active" 0 "Inactive" ;
VAL_TABLE_ PEPS_Lock_KeyInside_Alert 1 "Active" 0 "Inactive" ;
VAL_TABLE_ PEPS_EmergencyStop_Reserved 3 "Invalid" 2 "Reserved" 1 "EmergencyStopMode" 0 "Normal" ;
VAL_TABLE_ PEPS_CID_NotIndenfied_Alert 1 "Active" 0 "InActive" ;
VAL_TABLE_ BCM_Positionlight_reminder 0 "Inactive" 1 "Active" 2 "Reserved" 3 "Signal Invalid" ;
VAL_TABLE_ RemoteAccessKey 15 "Invalid" 8 "Panic alarm press" 7 "Panic alarm long press" 6 "Long press unlock" 5 "Long press lock" 4 "Tailgate unlock" 3 "Tailgate unlock long press" 2 "Unlock" 1 "Lock" 0 "No command" ;
VAL_TABLE_ PassiveAccessTrunk 3 "Signal invalid" 2 "Reserved" 1 "Pressed" 0 "Not pressed" ;
VAL_TABLE_ BCM_CurrentValid_FOB 0 "No Valid FOB" 1 "FOB_1" 2 "FOB_2" 3 "FOB_3" 4 "FOB_4" 5 "Reserved" 6 "Reserved" 7 "Reserved" ;
VAL_TABLE_ BCM_STAT_RemoteLockFeedback 7 "Signal invalid" 6 "Reserved" 5 "Reserved" 4 "Inactive" 3 "Horn Only" 2 "Lights Only" 1 "Lights and Horn" 0 "OFF" ;
VAL_TABLE_ BCM_STAT_RemoteDoorUnlock_reserv 3 "Signal invalid" 2 "All doors" 1 "Driver door" 0 "Reserved" ;
VAL_TABLE_ BCM_STAT_AutoDoorUnlock 3 "Signal invalid" 2 "Reserved" 1 "ON" 0 "OFF" ;
VAL_TABLE_ BCM_STAT_DoorSpeedLock 7 "Signal invalid" 5 "25KMH" 4 "20KMH" 3 "15KMH" 2 "10KMH" 1 "5KMH" 0 "OFF" ;
VAL_TABLE_ BCM_STAT_DayTimeRunningLight_res 3 "Signal invalid" 2 "Reserved" 1 "ON" 0 "OFF" ;
VAL_TABLE_ BCM_STAT_AntiTheftMode 7 "Signal invalid" 3 "Light and Horn" 2 "Horn Only" 1 "Light Only" 0 "OFF" ;
VAL_TABLE_ BCM_FOBID_userprofile_link 5 "Searching" 4 "No key found" 3 "key illegal" 2 "Fob2" 1 "Fob1" 0 "No trigger from MHU" ;
VAL_TABLE_ BCM_feedback_FollowMeHomeTime 4 "120s" 3 "90s" 2 "60s" 1 "30s" 0 "OFF" ;
VAL_TABLE_ Rolling_Counter_0x107 15 "Invalid" ;
VAL_TABLE_ STAT_ATWS 7 "Signal invalid" 6 "Reserved" 5 "Reserved" 4 "Security Failure" 3 "Partly secured" 2 "Alarm" 1 "Unsecured" 0 "Secured" ;
VAL_TABLE_ STAT_DoorLockDriver 3 "Signal invalid" 2 "Reserved" 1 "Locked" 0 "Unlocked" ;
VAL_TABLE_ Rolling_Counter_0x10C 15 "Invalid" ;
VAL_TABLE_ BCM_TboxAuthStatus 0 "Have not learn. Not allow action" 1 "PASSED" 2 "FALIED: Authentication fail" 3 "Invalid" ;
VAL_TABLE_ Rolling_Counter_0x110 15 "Invalid" ;
VAL_TABLE_ BCM_APM_FLWIN_Postion 7 "Reserved" 6 "closing" 5 "opening" 4 "Open-80%（Bottom to 80%）" 3 "80%-Close(80% to Top) " 2 "Open(Bottom) " 1 "Closed(Top)" 0 "NotActive" ;
VAL_TABLE_ BCM_APM_FRWIN_Postion 7 "Reserved" 6 "closing " 5 "opening" 4 "Open-80%（Bottom to 80%）" 3 "80%-Close(80% to Top) " 2 "Open(Bottom) " 1 "Closed(Top)" 0 "NotActive" ;
VAL_TABLE_ BCM_APM_RLWIN_Postion 7 "Reserved" 6 "closing " 5 "opening" 4 "Open-80%（Bottom to 80%）" 3 "80%-Close(80% to Top) " 2 "Open(Bottom) " 1 "Closed(Top)" 0 "NotActive" ;
VAL_TABLE_ BCM_APM_RRWIN_Postion 7 "Reserved" 6 "closing " 5 "opening" 4 "Open-80%（Bottom to 80%）" 3 "80%-Close(80% to Top) " 2 "Open(Bottom) " 1 "Closed(Top)" 0 "NotActive" ;
VAL_TABLE_ APM_Status 1 "Error" 0 "No Error" ;
VAL_TABLE_ ChildProtectionStatus 3 "Invaild" 2 "Reserved" 1 "ON" 0 "OFF" ;
VAL_TABLE_ APM_Window_DriveSW_FL_Status 5 "Reserved" 4 "Auto up" 3 "Manual up " 2 "OFF " 1 "Manual down" 0 "Auto down" ;
VAL_TABLE_ APM_Window_DriveSW_FR_Status 7 "Reserved" 6 "Reserved" 5 "Reserved" 4 "Manual up (Reserved Auto up)" 3 "Manual up " 2 "OFF " 1 "Manual down" 0 "Auto down" ;
VAL_TABLE_ APM_Window_DriveSW_RL_Status 7 "Reserved" 6 "Reserved" 5 "Reserved" 4 "Manual up (Reserved Auto up)" 3 "Manual up " 2 "OFF " 1 "Manual down" 0 "Auto down" ;
VAL_TABLE_ APM_Window_DriveSW_RR_Status 7 "Reserved" 6 "Reserved" 5 "Reserved" 4 "Manual up (Reserved Auto up)" 3 "Manual up " 2 "OFF " 1 "Manual down" 0 "Auto down" ;
VAL_TABLE_ APM_Window_PassengerSW_Status 7 "Reserved" 6 "Reserved" 5 "Reserved" 4 "Manual up (Reserved Auto up)" 3 "Manual up " 2 "OFF " 1 "Manual down" 0 "Auto down" ;
VAL_TABLE_ APM_Window_PassengerSW_RL_Status 7 "Reserved" 6 "Reserved" 5 "Reserved" 4 "Manual up (Reserved Auto up)" 3 "Manual up " 2 "OFF " 1 "Manual down" 0 "Auto down" ;
VAL_TABLE_ APM_Window_PassengerSW_RR_Status 7 "Reserved" 6 "Reserved" 5 "Reserved" 4 "Manual up (Reserved Auto up)" 3 "Manual up " 2 "OFF " 1 "Manual down" 0 "Auto down" ;
VAL_TABLE_ Rolling_Counter_0x20D 15 "Invalid" ;
VAL_TABLE_ BCM_ODO 1048575 "Invalid" ;
VAL_TABLE_ Rolling_Counter_0x342 15 "Invalid" ;
VAL_TABLE_ ABS_LRWhlSpdRaw 32767 "Invalid" ;
VAL_TABLE_ ABS_LRWhlSpdRawValid 1 "Valid" 0 "Invalid" ;
VAL_TABLE_ ABS_RRWhlSpdRaw 32767 "Invalid" ;
VAL_TABLE_ ABS_RRWhlSpdRawValid 1 "Valid" 0 "Invalid" ;
VAL_TABLE_ ABS_VehSpd 32767 "Invalid" ;
VAL_TABLE_ ABS_VehSpdValid 1 "Valid" 0 "Invalid" ;
VAL_TABLE_ RollingCounter_0x132 15 "Invalid" ;
VAL_TABLE_ ESC_HSA_Control_Status 1 "active" 0 "inactive" ;
VAL_TABLE_ ESC_HSA_Status_Fault 1 " HSA Defective" 0 "HSA Normale" ;
VAL_TABLE_ ESC_TcsDisableSts 3 "signal invalid" 2 "reservred" 1 "disabled" 0 "enabled" ;
VAL_TABLE_ ESC_TcsCtrlActv 1 "active" 0 "inactive" ;
VAL_TABLE_ ESC_TcsFlgFlt 1 "failure" 0 "no failure" ;
VAL_TABLE_ ESC_EscDisableSts 1 "disabled" 0 "enabled" ;
VAL_TABLE_ ESC_EscCtrlActv 1 "active" 0 "inactive" ;
VAL_TABLE_ ESC_EscFlgFlt 1 "failure" 0 "no failure" ;
VAL_TABLE_ ESC_HBAFlgFlt 1 "failure" 0 "no failure" ;
VAL_TABLE_ ESC_HbaCtrlActv 1 "active" 0 "inactive" ;
VAL_TABLE_ ESC_SlopeGradeAngle 255 "Invalid" ;
VAL_TABLE_ ESC_MasterCylinderPressure 4095 "Invalid" ;
VAL_TABLE_ RollingCounter_0x142 15 "Invalid" ;
VAL_TABLE_ AbsDiagSessionLampReq_Reserved 1 "lamp on" 0 "lamp off" ;
VAL_TABLE_ ABS_AbsCtrlActv 1 "active" 0 "inactive" ;
VAL_TABLE_ ABS_EbdFlgFlt 1 "failure" 0 "no failure" ;
VAL_TABLE_ ABS_AbsFlgFlt 1 "failure" 0 "no failure" ;
VAL_TABLE_ ABS_ESS_Active 1 "active" 0 "inactive" ;
VAL_TABLE_ ABS_LowBrakeFluid 1 "failure" 0 "no failure" ;
VAL_TABLE_ RollingCounter_0x3E2 15 "Invalid" ;
VAL_TABLE_ ESC_LateralACC 255 "Invalid" ;
VAL_TABLE_ ESC_LateralACC_Valid 1 "Valid" 0 "Invalid" ;
VAL_TABLE_ ESC_LongitudeACC 1023 "Invalid" ;
VAL_TABLE_ ESC_LongitudeACC_Valid 1 "Valid" 0 "Invalid" ;
VAL_TABLE_ ESC_VehDynYawRate 16383 "Invalid" ;
VAL_TABLE_ ESC_VehDynYawRate_Valid 1 "Valid" 0 "Invalid" ;
VAL_TABLE_ ESC_FLTirePressAlarm 1 "Pressure warning" 0 "No warning" ;
VAL_TABLE_ ESC_FRTirePressAlarm 1 "Pressure warning" 0 "No warning" ;
VAL_TABLE_ ESC_RLTirePressAlarm 1 "Pressure warning" 0 "No warning" ;
VAL_TABLE_ ESC_RRTirePressAlarm 1 "Pressure warning" 0 "No warning" ;
VAL_TABLE_ ESC_iTPMS_Err 1 "Error" 0 "No error" ;
VAL_TABLE_ ESC_iTPMS_WarnLampAct 1 "Active" 0 "Inactive" ;
VAL_TABLE_ ESC_iTPMSResetProhibit 3 "prohibit 3 (System error)" 2 "prohibit 2 (Vehicle speed >0 km/h)" 1 "prohibit 1 (Tire statue is changing)" 0 "Not prohibit" ;
VAL_TABLE_ ESC_iTPMSResetSts 4 "Reset fail" 3 "Reset finish" 2 "Reset ongoing" 1 "Reset start" 0 "Idle" ;
VAL_TABLE_ SAS_SteerWheelAngle 65535 "Invalid" ;
VAL_TABLE_ SAS_SteeringAngleValid 1 "Valid" 0 "Invalid" ;
VAL_TABLE_ SAS_SASStsSnsr 1 "sensor value valid" 0 "sensor value Invalid" ;
VAL_TABLE_ SAS_SteerWhlRotSpd 16383 "Invalid" ;
VAL_TABLE_ SAS_SteerWhlRotSpdStatus 1 "Valid" 0 "Invalid" ;
VAL_TABLE_ SAS_SASFailure 1 "No Failure" 0 "Failure" ;
VAL_TABLE_ EPS_EpsFailed 1 "failed" 0 "not failed" ;
VAL_TABLE_ Rolling_Counter_0x2A1 15 "Invalid" ;
VAL_TABLE_ ODS_Status 3 "Reserved" 2 "ODS disconnected" 1 "Seat Occupied" 0 "Seat Not Occupied" ;
VAL_TABLE_ EVCC_MHU_CharSchSetFeedBack 3 "invalid " 2 "No Schedule" 1 "Schedule Success" 0 "No action" ;
VAL_TABLE_ EVCC_ChargeGunSts 1 "Plug In" 0 "no Plug in" ;
VAL_TABLE_ EVCC_ChargeMode 2 "DC Mode " 1 "AC Mode " 0 "Default" ;
VAL_TABLE_ EVCC_CP_Sts 12 "F~" 11 "E~" 10 "D~" 9 "C~" 8 "B~" 7 "A~" 6 "F" 5 "E" 4 "D" 3 "C" 2 "B" 1 "A" 0 "No CP" ;
VAL_TABLE_ EVCC_PP_Value 7 "CC GND" 6 "1500" 5 "680" 4 "220" 3 "100" 2 "Connection" 1 "Half Connection " 0 "No Connection" ;
VAL_TABLE_ EVCC_Lock_Sts 4 "Error" 3 "Unlocking" 2 "Locked" 1 "Locking " 0 "Unlock" ;
VAL_TABLE_ EAC_CompElecCurrV 0 "Valid" 1 "Invalid" ;
VAL_TABLE_ EAC_CompStat 0 "Normal Operation" 1 "Degraded Operation" 2 "Inoperative" 15 "Invalid" ;
VAL_TABLE_ EAC_CompElecPwrV 0 "Valid" 1 "Invalid" ;
VAL_TABLE_ EAC_CompSpdIncrReq 0 "False" 1 "True" ;
VAL_TABLE_ EAC_CompSpdV 0 "Valid" 1 "Invalid" ;
VAL_TABLE_ EAC_CompElecPwr 255 "Invaild" ;
VAL_TABLE_ EAC_CompSpd 16383 "Invaild" ;
VAL_TABLE_ EAC_CompElecCurr 255 "Invaild" ;
VAL_TABLE_ EAC_CompFltStat 0 "No Fault" 1 "Under Voltage" 2 "Over Voltage" 3 "Over Temperature" 4 "Input Control" 5 "Current Fault" 6 "Internal Fault" 8 "Motor slip protection" 9 "HVDC input voltage drop protection" 10 "Inside the controller 15V control power supply output undervoltage protection" 11 "Overcurrent frequency limitation and frequency reduction" 15 "Invalid" ;
VAL_TABLE_ VCU_PTC_RelaySts 1 "close" 0 "open" ;
VAL_TABLE_ VCU_EACEnbReq 1 "Enable" 0 "Disable" ;
VAL_TABLE_ VCU_EACAllowedPower 1023 "Invalid" ;
VAL_TABLE_ VCU_EAC_CompSpdReq 16383 "Invaild" ;
VAL_TABLE_ VCU_DriveCoolWaterPumpSts 5 "Reserved" 4 "Other error" 3 "Overtemperature" 2 "Locked-rotor" 1 "Idle" 0 "Normal" ;
VAL_TABLE_ VCU_DriveCoolWaterDuty 127 "Invalid" ;
VAL_TABLE_ VCU_BatteryWaterPumpSts_reserved 5 "Reserved" 4 "Other error" 3 "Overtemperature" 2 "Locked-rotor" 1 "Idle" 0 "Normal" ;
VAL_TABLE_ VCU_BatteryWaterPumpDuty_reserve 127 "Invalid" ;
VAL_TABLE_ VCU_DriveMode 7 "Invalid" 6 "Reserved" 5 "Reserved" 4 "Reserved" 3 "Reserved" 2 "Sport mode" 1 "ECO mode" 0 "Normal mode" ;
VAL_TABLE_ VCU_ActualGear 7 "Fault" 6 "Reserved" 5 "Reserved" 4 "Reserved" 3 "D" 2 "N" 1 "R" 0 "P reserved" ;
VAL_TABLE_ VCU_ACTGearValid 1 "nvalid" 0 "Valid" ;
VAL_TABLE_ VCU_AccPedal1OutRange 1 "Error" 0 "Normal" ;
VAL_TABLE_ VCU_AccPedal2OutRange 1 "Error" 0 "Normal" ;
VAL_TABLE_ VCU_BrkPedal1OutRange 1 "Error" 0 "Normal" ;
VAL_TABLE_ VCU_BrkPedal2OutRange 1 "Error" 0 "Normal" ;
VAL_TABLE_ VCU_BrkPedalPct 255 "Invalid" ;
VAL_TABLE_ VCU_AccPedalPosition 255 "Invalid" ;
VAL_TABLE_ VCU_AccPedalPositionValid 1 "Invalid" 0 "Valid" ;
VAL_TABLE_ VCU_SocDisplay_EST 127 "Invalid" ;
VAL_TABLE_ VCU_PowerLimit 1 "Limit" 0 "No Limit" ;
VAL_TABLE_ VCU_CruiseCtrlSts 3 "takeover mode" 2 "Pre cruise(lamp flash)" 1 "Cruise on(lamp on)" 0 "Cruise off(lamp off)" ;
VAL_TABLE_ VCU_LowSOC_ERR 1 "Error" 0 "No Error" ;
VAL_TABLE_ VCU_RegenLevel_Feed 3 "invalid" 2 "High" 1 "Low" 0 "none" ;
VAL_TABLE_ VCU_RBCSts 1 "active" 0 "incative" ;
VAL_TABLE_ VCU_RDCSts 1 "active" 0 "incative" ;
VAL_TABLE_ VCU_Veh_ERR 1 "Error" 0 "Normal" ;
VAL_TABLE_ VCU_DrvSys_ERR 1 "Error" 0 "Normal" ;
VAL_TABLE_ VCU_PackSys_ERR 1 "Error" 0 "Normal" ;
VAL_TABLE_ VCU_TBOX_Veh_STS_Reserved 3 "Other" 2 "Off" 1 "Start" 0 "Invalid" ;
VAL_TABLE_ VCU_VehChg_STS 3 "Charge fault" 2 "Charging complete" 1 "Charging in progress" 0 "Charging not in progress" ;
VAL_TABLE_ VCU_BatterVoltage_Reserved 255 "Invalid" ;
VAL_TABLE_ VCU_BatteryVoltErr_Reserved 1 "warning" 0 "no warning" ;
VAL_TABLE_ VCU_MotorCoolingCircuitErr_Reser 1 "Error" 0 "Normal" ;
VAL_TABLE_ VCU_PackCoolingCircuitErr_Reserv 1 "Error" 0 "Normal" ;
VAL_TABLE_ VCU_VehicleHVStatus 3 "Reserved" 2 "ReadyToDrive" 1 "HV On" 0 "Not ready" ;
VAL_TABLE_ VCU_InstantPowerConsump 1023 "Invalid" ;
VAL_TABLE_ VCU_AveragePowerConsump 1023 "Invalid" ;
VAL_TABLE_ VCU_BrakePedalSts 3 "Invalid" 2 "Reserved" 1 "pressed" 0 "Not pressed" ;
VAL_TABLE_ VCU_IMMO_Sts 2 "failed " 1 "pass " 0 "init" ;
VAL_TABLE_ VCU_DCDCAllowedPower 511 "Invalid" ;
VAL_TABLE_ VCU_Shift_ERR 1 "Error" 0 "Normal" ;
VAL_TABLE_ VCU_VehicleDischargePower 127 "Invalid" ;
VAL_TABLE_ VCU_VehicleChargePower 127 "Invalid" ;
VAL_TABLE_ Rolling_Counter_0x3E0 15 "Invalid" ;
VAL_TABLE_ VCU_MHU_Ack_ChgSche_stt 0 "Disabled" 1 "Enabled" 2 "Reserved" 3 "Invalid" ;
VAL_TABLE_ VCU_MHU_GuestMode_sts 0 "OFF" 1 "ON" 2 "Reserved" 3 "Reserved" ;
VAL_TABLE_ VCU_ValetMode_sts 0 "Inactive" 1 "Active" 255 "Invalid" ;
VAL_TABLE_ VCU_CreepDisable_stt 0 "Enable" 1 "Disable" ;
VAL_TABLE_ Rolling_Counter_0x2E9 15 "Invalid" ;
VAL_TABLE_ VCU_SetCruiseSpd 255 "Invalid" ;
VAL_TABLE_ Rolling_Counter_0x216 15 "Invalid" ;
VAL_TABLE_ BMS_RemainChargeTime 16383 "Invalid" ;
VAL_TABLE_ BMS_ChgVoltage_REQ 16383 "Invalid" ;
VAL_TABLE_ BMS_ChgCurrent_REQ 65535 "Invalid" ;
VAL_TABLE_ Rolling_Counter_0x215 15 "Invalid" ;
VAL_TABLE_ BMS_SOE 255 "Invalid" ;
VAL_TABLE_ BMS_HWCrash_Sts 1 "Crash " 0 "No Crash" ;
VAL_TABLE_ BMS_HVIL_STS 2 "short to ground" 1 "Open & short to battery" 0 "Closed" ;
VAL_TABLE_ BMS_IGN_Sts 1 "ON " 0 "OFF" ;
VAL_TABLE_ BMS_Sys_STS 8 "Invalid" 7 "Failure, unable to operate" 6 "BCU Sleep mode" 5 "Successful Power Down" 4 "Power Down process" 3 "Successful Power Down of HV" 2 "Successful High Voltage Power Up" 1 "Self-check passes, can be high-voltage" 0 "Initialization of power on, self-checking" ;
VAL_TABLE_ BMS_HVOnOff_STS 3 "Fail to HV on " 2 "HV On " 1 "Precharge " 0 "HV Off" ;
VAL_TABLE_ BMS_Balance_STS 1 "active " 0 "Inactive" ;
VAL_TABLE_ BMS_SocActual_EST 1023 "Invalid" ;
VAL_TABLE_ BMS_BatBalance_ERR 1 "normal " 0 "Error" ;
VAL_TABLE_ BMS_ISU_Status 3 "Level3(<100 Ohms/V)" 2 "Level2(<200 Ohms/V)" 1 "Level1 <500 Ohms/V ~ >200 Ohms/V" 0 "Normal (> 500 Ohms/V)" ;
VAL_TABLE_ BMS_ERR_LEV 7 "Battery locked -Reserved" 6 "Fault, needs Shutdown and Wakeup" 5 "Emergency off condition" 4 "Delayed power down with FTTI" 3 "Power down without FTTI" 2 "Limp Home" 1 " Warning (any warning in system)" 0 "No error" ;
VAL_TABLE_ BMS_SOH 255 "Invalid" ;
VAL_TABLE_ BMS_HV_Sts 4 "AC Charge" 3 "Super Fast Charge" 2 "HV ON" 1 "Precharge" 0 "HV Off" ;
VAL_TABLE_ BMS_DischargeCurrent_Limited 1 "Limited" 0 "Not Limited " ;
VAL_TABLE_ BMS_Warning_Flag_Reserved_07 1 "Warning" 0 "No warning" ;
VAL_TABLE_ BMS_Warning_Flag_Reserved_11 1 "Warning" 0 "No warning" ;
VAL_TABLE_ BMS_Warning_Flag_Reserved_10 1 "Warning" 0 "No warning" ;
VAL_TABLE_ BMS_Warning_Flag_Reserved_09 1 "Warning" 0 "No warning" ;
VAL_TABLE_ BMS_Warning_Flag_Reserved_13 1 "Warning" 0 "No warning" ;
VAL_TABLE_ BMS_Warning_Flag_Reserved_12 1 "Warning" 0 "No warning" ;
VAL_TABLE_ BMS_Warning_Flag_Reserved_06 1 "Warning" 0 "No warning" ;
VAL_TABLE_ BMS_Warning_Flag_Reserved_05 1 "Warning" 0 "No warning" ;
VAL_TABLE_ BMS_Warning_Flag_Reserved_04 1 "Warning" 0 "No warning" ;
VAL_TABLE_ BMS_MalfunctionSts 1 "Malfunction indicator lamp ON" 0 "Malfunction indicator lamp OFF" ;
VAL_TABLE_ BMS_LowBattery 2 "Extremely low level" 1 "Low level" 0 "No warning" ;
VAL_TABLE_ BMS_BatteryReplacement 1 "Warning" 0 "No warning" ;
VAL_TABLE_ BMS_PackTempSts 2 "Under Temperature Warning" 1 "Over Temperature Warning" 0 "No warning" ;
VAL_TABLE_ BMS_ThermalRunaway 1 "Warning" 0 "No warning" ;
VAL_TABLE_ Rolling_Counter_0x493 15 "Invalid" ;
VAL_TABLE_ Rolling_Counter_0x174 15 "Invalid" ;
VAL_TABLE_ BMS_PackCur_MEAS 65535 "Invalid" ;
VAL_TABLE_ Rolling_Counter_0x176 15 "Invalid" ;
VAL_TABLE_ BMS_HVLinkVol_MEAS 65535 "Invalid" ;
VAL_TABLE_ BMS_HVPackVol_MEAS 65535 "Invalid" ;
VAL_TABLE_ Rolling_Counter_0x20B 15 "Invalid" ;
VAL_TABLE_ DCDC_Sys_STS 6 "(Off)" 5 "(Fault,Cannot work)" 3 "(Successful High Voltage Power Up)" 1 "(Self-Check passes, can be high-voltage)" 0 "(Initialization of power on, self-checking)" ;
VAL_TABLE_ DCDC_Voltage_Input 1023 "Invalid" ;
VAL_TABLE_ DCDC_Current_Input 255 "Invalid" ;
VAL_TABLE_ DCDC_Voltage_Output 1023 "Invalid" ;
VAL_TABLE_ DCDC_Current_Output 255 "Invalid" ;
VAL_TABLE_ DCDC_Output_STS 2 "fault" 1 "normal" 0 "stop" ;
VAL_TABLE_ DCDC_Temp 255 "Invalid" ;
VAL_TABLE_ Rolling_Counter_0x1F8 15 "Invalid" ;
VAL_TABLE_ EDS_output_trq_FR 65535 "Invalid" ;
VAL_TABLE_ EDS_output_trqValid_FR 1 "valid" 0 "invalid" ;
VAL_TABLE_ EDS_Spd_FR 65535 "Invalid" ;
VAL_TABLE_ EDS_SpdValid_FR 1 "valid" 0 "invalid" ;
VAL_TABLE_ EDS_MotorDriveSts_FR 3 "Invaild" 2 "regen control" 1 "Drive control" 0 "Zero control" ;
VAL_TABLE_ EDS_Work_STS_FR 15 "invaild" 14 "power off" 13 "Failure" 12 "after run" 11 "shut down" 5 "HVReady" 4 "normal" 3 "precharge" 2 "standby" 1 "init" 0 "default" ;
VAL_TABLE_ EDS_powoff_req_FR 1 "(Request high voltage power down)" 0 "(No request)" ;
VAL_TABLE_ MFS_OK_Control 0 "Button not Pressed" 1 "Short Press" 2 "Long Press" 3 "Signal invalid" ;
VAL_TABLE_ MFS_SourseControl 0 "Button not Pressed" 1 "Short Press" 2 "Long Press" 3 "Signal invalid" ;
VAL_TABLE_ MFS_VoiceRecognitionOn_Off 0 "Button not Pressed" 1 "Short Press" 2 "Long Press" 3 "Signal invalid" ;
VAL_TABLE_ MFS_TelephoneCall_EndCall 0 "Button not Pressed" 1 "Short Press" 2 "Long Press" 3 "Signal invalid" ;
VAL_TABLE_ MFS_DownControl 0 "Button not Pressed" 1 "Short Press" 2 "Long Press" 3 "Signal invalid" ;
VAL_TABLE_ MFS_UpControl 0 "Button not Pressed" 1 "Short Press" 2 "Long Press" 3 "Signal invalid" ;
VAL_TABLE_ MFS_RightControl 0 "Button not Pressed" 1 "Short Press" 2 "Long Press" 3 "Signal invalid" ;
VAL_TABLE_ MFS_LeftControl 0 "Button not Pressed" 1 "Short Press" 2 "Long Press" 3 "Signal invalid" ;
VAL_TABLE_ MFS_CruiseOn_Off 0 "Button not Pressed" 1 "Short Press" 2 "Long Press" 3 "Signal invalid" ;
VAL_TABLE_ MFS_Failure 0 "No Error" 1 "Error" ;
VAL_TABLE_ MFS_ISAControl 0 "Button not Pressed" 1 "Button Pressed" ;
VAL_TABLE_ MFS_LKAControl 0 "Button not Pressed" 1 "Button Pressed" ;
VAL_TABLE_ MFS_CruiseGapDecrease 0 "Button not Pressed" 1 "Short Press" 2 "Long Press" 3 "Signal invalid" ;
VAL_TABLE_ MFS_CruiseSpeedDecrease 0 "Button not Pressed" 1 "Short Press" 2 "Long Press" 3 "Signal invalid" ;
VAL_TABLE_ MFS_CruiseSpeedIncrease 0 "Button not Pressed" 1 "Short Press" 2 "Long Press" 3 "Signal invalid" ;
VAL_TABLE_ MFS_CruiseCancel 0 " Button not Pressed " 1 "No Action" 2 "Cruise Cancel " 3 "Reserved" ;
VAL_TABLE_ MFS_CruiseGapIncrease 0 "Button not Pressed" 1 "Short Press" 2 "Long Press" 3 "Signal invalid" ;
VAL_TABLE_ MFS_Mode_Control 3 "Signal invalid" 2 "Long Press" 1 "Short Press" 0 "Unpress" ;
VAL_TABLE_ MFS_MUTE_SPEAKER 3 "Signal invalid" 2 "Long Press" 1 "Short Press" 0 "Unpress" ;
VAL_TABLE_ MFS_SONG_U 3 "Signal invalid" 2 "Long Press" 1 "Short Press" 0 "Unpress" ;
VAL_TABLE_ MFS_SONG_D 3 "Signal invalid" 2 "Long Press" 1 "Short Press" 0 "Unpress" ;
VAL_TABLE_ MFS_VOL_U 3 "Signal invalid" 2 "Long Press" 1 "Short Press" 0 "Unpress" ;
VAL_TABLE_ MFS_VOL_D 3 "Signal invalid" 2 "Long Press" 1 "Short Press" 0 "Unpress" ;

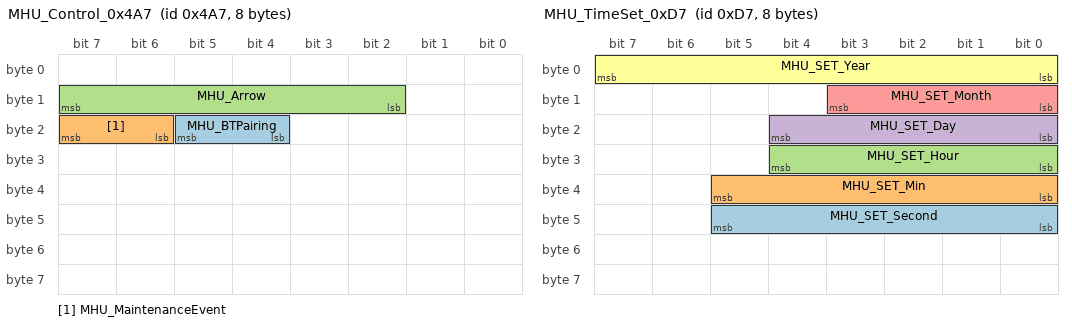
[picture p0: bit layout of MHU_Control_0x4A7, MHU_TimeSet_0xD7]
BO_ 1191 MHU_Control_0x4A7: 8 MHU
 SG_ MHU_BTPairing : 21|2@0+ (1,0) [0|3] ""  IPC
 SG_ MHU_MaintenanceEvent : 23|2@0+ (1,0) [0|3] ""  IPC
 SG_ MHU_Arrow : 15|6@0+ (1,0) [0|31] ""  IPC

BO_ 215 MHU_TimeSet_0xD7: 8 MHU
 SG_ MHU_SET_Second : 45|6@0+ (1,0) [0|59] "second"  IPC
 SG_ MHU_SET_Min : 37|6@0+ (1,0) [0|59] "min"  IPC
 SG_ MHU_SET_Hour : 28|5@0+ (1,0) [0|23] "hour"  IPC
 SG_ MHU_SET_Day : 20|5@0+ (1,0) [1|31] ""  IPC
 SG_ MHU_SET_Month : 11|4@0+ (1,0) [1|12] ""  IPC
 SG_ MHU_SET_Year : 7|8@0+ (1,2000) [2000|2255] ""  IPC

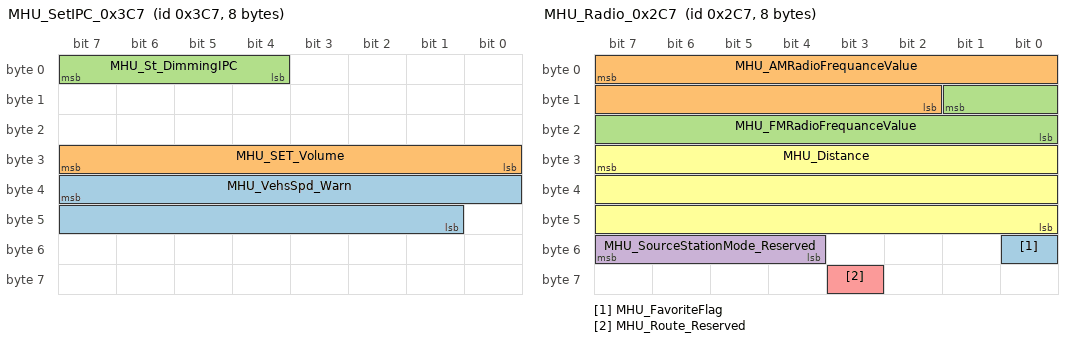
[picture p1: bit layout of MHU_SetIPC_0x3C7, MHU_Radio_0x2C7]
BO_ 967 MHU_SetIPC_0x3C7: 8 MHU
 SG_ MHU_VehsSpd_Warn : 39|15@0+ (0.01,0) [0|120] ""  GW,IPC
 SG_ MHU_SET_Volume : 31|8@0+ (1,0) [0|32] ""  GW,IPC
 SG_ MHU_St_DimmingIPC : 7|4@0+ (1,0) [0|15] ""  GW,IPC

BO_ 711 MHU_Radio_0x2C7: 8 MHU
 SG_ MHU_FavoriteFlag : 48|1@0+ (1,0) [0|1] ""  IPC
 SG_ MHU_AMRadioFrequanceValue : 7|14@0+ (0.1,520) [520|1620] "KHz"  IPC
 SG_ MHU_FMRadioFrequanceValue : 9|10@0+ (0.1,87.5) [87.5|108] "MHz"  IPC
 SG_ MHU_SourceStationMode_Reserved : 55|4@0+ (1,0) [0|7] "" Vector__XXX
 SG_ MHU_Route_Reserved : 59|1@0+ (1,0) [0|1] "" Vector__XXX
 SG_ MHU_Distance : 31|24@0+ (0.001,0) [0|10000] "km"  IPC

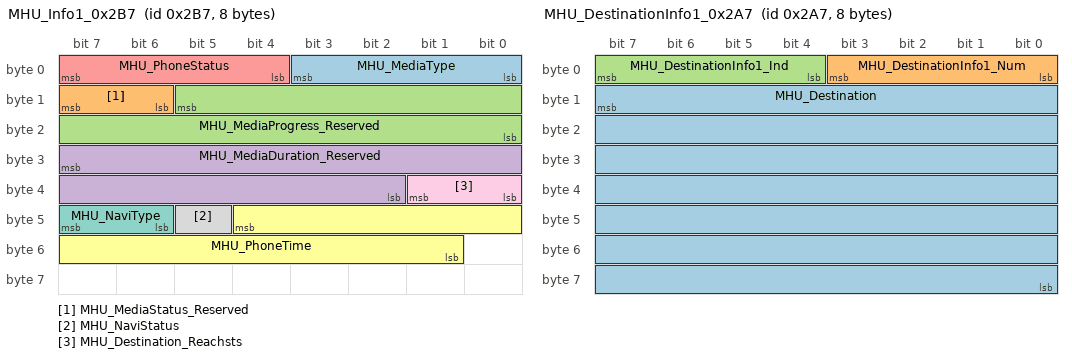
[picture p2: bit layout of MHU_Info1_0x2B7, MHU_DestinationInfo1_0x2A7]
BO_ 695 MHU_Info1_0x2B7: 8 MHU
 SG_ MHU_MediaType : 3|4@0+ (1,0) [0|15] ""  IPC
 SG_ MHU_MediaStatus_Reserved : 15|2@0+ (1,0) [0|3] "" Vector__XXX
 SG_ MHU_MediaProgress_Reserved : 13|14@0+ (1,0) [0|16383] "s" Vector__XXX
 SG_ MHU_MediaDuration_Reserved : 31|14@0+ (1,0) [0|16383] "s" Vector__XXX
 SG_ MHU_PhoneStatus : 7|4@0+ (1,0) [0|15] ""  IPC
 SG_ MHU_PhoneTime : 44|12@0+ (1,0) [0|4095] "s"  IPC
 SG_ MHU_NaviType : 47|2@0+ (1,0) [0|3] "" Vector__XXX
 SG_ MHU_NaviStatus : 45|1@0+ (1,0) [0|1] ""  IPC
 SG_ MHU_Destination_Reachsts : 33|2@0+ (1,0) [0|3] ""  IPC

BO_ 679 MHU_DestinationInfo1_0x2A7: 8 MHU
 SG_ MHU_Destination : 15|56@0+ (1,0) [0|7.20576E+016] ""  IPC
 SG_ MHU_DestinationInfo1_Num : 3|4@0+ (1,0) [0|15] ""  IPC
 SG_ MHU_DestinationInfo1_Ind : 7|4@0+ (1,0) [0|15] ""  IPC

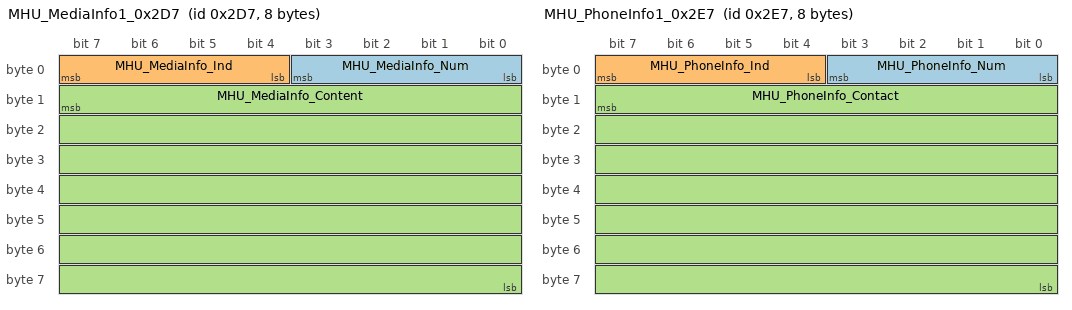
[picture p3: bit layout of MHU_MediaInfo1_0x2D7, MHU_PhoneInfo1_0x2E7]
BO_ 727 MHU_MediaInfo1_0x2D7: 8 MHU
 SG_ MHU_MediaInfo_Num : 3|4@0+ (1,0) [0|15] ""  IPC
 SG_ MHU_MediaInfo_Ind : 7|4@0+ (1,0) [0|15] ""  IPC
 SG_ MHU_MediaInfo_Content : 15|56@0+ (1,0) [0|7.20576E+016] ""  IPC

BO_ 743 MHU_PhoneInfo1_0x2E7: 8 MHU
 SG_ MHU_PhoneInfo_Num : 3|4@0+ (1,0) [0|15] ""  IPC
 SG_ MHU_PhoneInfo_Ind : 7|4@0+ (1,0) [0|15] ""  IPC
 SG_ MHU_PhoneInfo_Contact : 15|56@0+ (1,0) [0|7.20575940379279E+016] ""  IPC

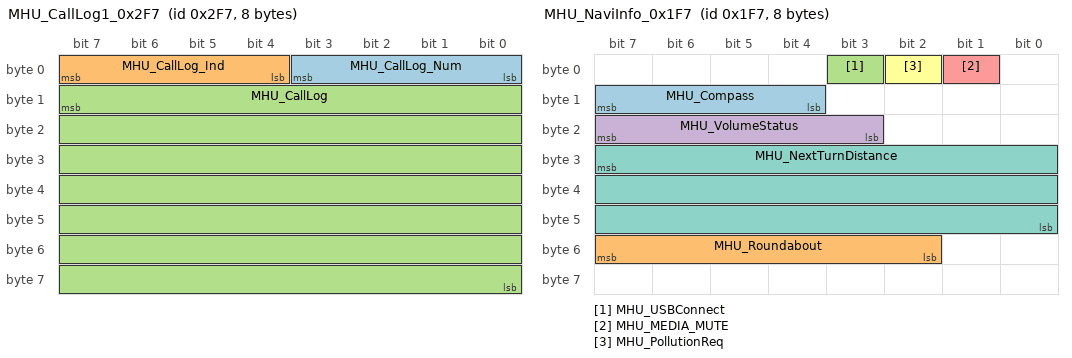
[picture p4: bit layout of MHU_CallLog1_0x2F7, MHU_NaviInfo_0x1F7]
BO_ 759 MHU_CallLog1_0x2F7: 8 MHU
 SG_ MHU_CallLog_Num : 3|4@0+ (1,0) [0|15] ""  IPC
 SG_ MHU_CallLog_Ind : 7|4@0+ (1,0) [0|15] ""  IPC
 SG_ MHU_CallLog : 15|56@0+ (1,0) [0|7.20575940379279E+016] ""  IPC

BO_ 999 MHU_PhoneType_0x3E7: 8 MHU
 SG_ MHU_PhoneType : 15|56@0+ (1,0) [0|7.20575940379279E+016] ""  IPC

BO_ 983 MHU_PhoneName_0x3D7: 8 MHU
 SG_ MHU_PhoneName : 15|56@0+ (1,0) [0|7.20575940379279E+016] ""  IPC

BO_ 503 MHU_NaviInfo_0x1F7: 8 MHU
 SG_ MHU_Compass : 15|4@0+ (1,0) [0|15] ""  IPC
 SG_ MHU_Roundabout : 55|6@0+ (1,0) [0|63] ""  IPC
 SG_ MHU_USBConnect : 3|1@0+ (1,0) [0|1] ""  IPC
 SG_ MHU_VolumeStatus : 23|5@0+ (1,0) [0|30] ""  IPC
 SG_ MHU_MEDIA_MUTE : 1|1@0+ (1,0) [0|1] ""  IPC
 SG_ MHU_PollutionReq : 2|1@0+ (1,0) [0|1] "" Vector__XXX
 SG_ MHU_NextTurnDistance : 31|24@0+ (0.001,0) [0|10000] "km"  IPC

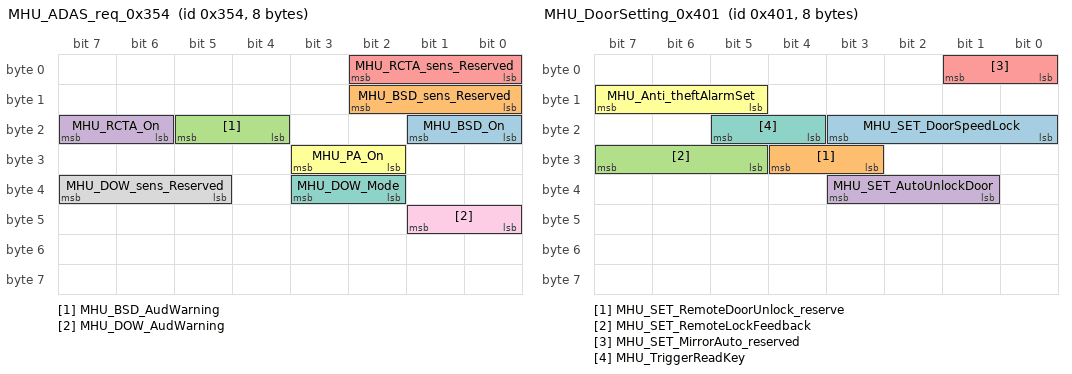
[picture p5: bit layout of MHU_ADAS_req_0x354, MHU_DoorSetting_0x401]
BO_ 852 MHU_ADAS_req_0x354: 8 MHU
 SG_ MHU_BSD_On : 17|2@0+ (1,0) [0|3] ""  GW
 SG_ MHU_BSD_sens_Reserved : 10|3@0+ (1,0) [0|3] ""  GW
 SG_ MHU_BSD_AudWarning : 21|2@0+ (1,0) [0|3] ""  GW
 SG_ MHU_RCTA_On : 23|2@0+ (1,0) [0|3] ""  GW
 SG_ MHU_RCTA_sens_Reserved : 2|3@0+ (1,0) [0|3] ""  GW
 SG_ MHU_PA_On : 27|2@0+ (1,0) [0|3] ""  GW
 SG_ MHU_DOW_Mode : 35|2@0+ (1,0) [0|3] ""  GW
 SG_ MHU_DOW_sens_Reserved : 39|3@0+ (1,0) [0|3] ""  GW
 SG_ MHU_DOW_AudWarning : 41|2@0+ (1,0) [0|3] ""  GW

BO_ 1025 MHU_DoorSetting_0x401: 8 MHU
 SG_ MHU_SET_DoorSpeedLock : 19|4@0+ (1,0) [0|15] ""  GW
 SG_ MHU_SET_RemoteDoorUnlock_reserve : 28|2@0+ (1,0) [0|3] ""  GW
 SG_ MHU_SET_RemoteLockFeedback : 31|3@0+ (1,0) [0|7] ""  GW
 SG_ MHU_SET_AutoUnlockDoor : 35|3@0+ (1,0) [0|7] ""  GW
 SG_ MHU_SET_MirrorAuto_reserved : 1|2@0+ (1,0) [0|3] ""  GW
 SG_ MHU_Anti_theftAlarmSet : 15|3@0+ (1,0) [0|7] ""  GW
 SG_ MHU_TriggerReadKey : 21|2@0+ (1,0) [0|3] ""  GW

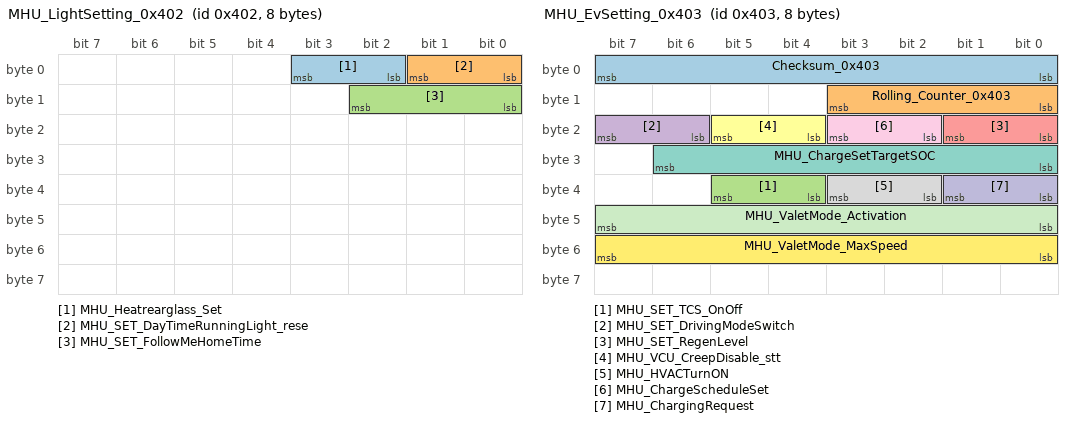
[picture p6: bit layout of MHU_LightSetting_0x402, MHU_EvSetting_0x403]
BO_ 1026 MHU_LightSetting_0x402: 8 MHU
 SG_ MHU_Heatrearglass_Set : 3|2@0+ (1,0) [0|3] ""  GW
 SG_ MHU_SET_DayTimeRunningLight_rese : 1|2@0+ (1,0) [0|3] ""  GW
 SG_ MHU_SET_FollowMeHomeTime : 10|3@0+ (1,0) [0|7] ""  GW

BO_ 1027 MHU_EvSetting_0x403: 8 MHU
 SG_ Checksum_0x403 : 7|8@0+ (1,0) [0|255] ""  GW
 SG_ Rolling_Counter_0x403 : 11|4@0+ (1,0) [0|15] ""  GW
 SG_ MHU_SET_TCS_OnOff : 37|2@0+ (1,0) [0|3] ""  GW
 SG_ MHU_SET_DrivingModeSwitch : 23|2@0+ (1,0) [0|3] ""  GW
 SG_ MHU_SET_RegenLevel : 17|2@0+ (1,0) [0|3] ""  GW
 SG_ MHU_VCU_CreepDisable_stt : 21|2@0+ (1,0) [0|3] ""  GW
 SG_ MHU_ChargeSetTargetSOC : 30|7@0+ (1,0) [10|100] "Percentage"  GW
 SG_ MHU_HVACTurnON : 35|2@0+ (1,0) [0|3] ""  GW,CCU
 SG_ MHU_ChargeScheduleSet : 19|2@0+ (1,0) [0|3] ""  GW
 SG_ MHU_ChargingRequest : 33|2@0+ (1,0) [0|3] ""  GW
 SG_ MHU_ValetMode_Activation : 47|8@0+ (1,0) [0|254] ""  GW
 SG_ MHU_ValetMode_MaxSpeed : 55|8@0+ (1,0) [0|254] "kph"  GW

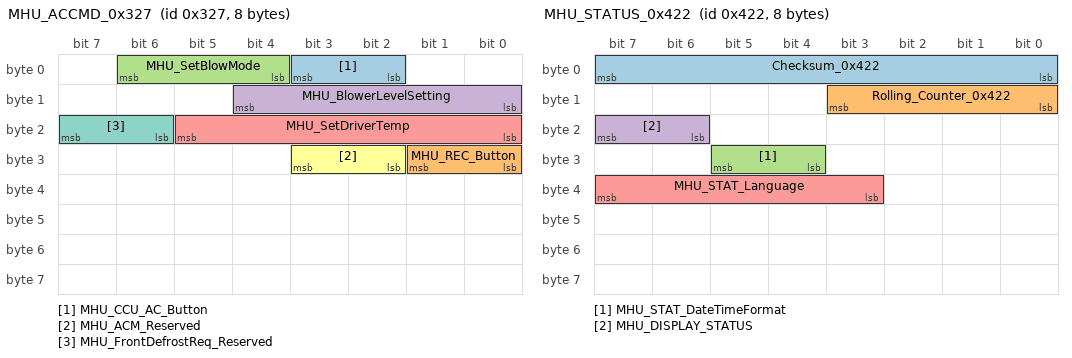
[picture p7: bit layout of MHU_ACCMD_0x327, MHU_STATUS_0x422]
BO_ 807 MHU_ACCMD_0x327: 8 MHU
 SG_ MHU_CCU_AC_Button : 3|2@0+ (1,0) [0|3] ""  CCU
 SG_ MHU_REC_Button : 25|2@0+ (1,0) [0|3] ""  CCU
 SG_ MHU_SetBlowMode : 6|3@0+ (1,0) [0|7] ""  CCU
 SG_ MHU_BlowerLevelSetting : 12|5@0+ (1,0) [0|9] ""  CCU
 SG_ MHU_SetDriverTemp : 21|6@0+ (1,0) [0|63] ""  CCU
 SG_ MHU_ACM_Reserved : 27|2@0+ (1,0) [0|3] ""  CCU
 SG_ MHU_FrontDefrostReq_Reserved : 23|2@0+ (1,0) [0|3] ""  CCU

BO_ 1058 MHU_STATUS_0x422: 8 MHU
 SG_ Checksum_0x422 : 7|8@0+ (1,0) [0|255] ""  IPC
 SG_ Rolling_Counter_0x422 : 11|4@0+ (1,0) [0|15] ""  IPC
 SG_ MHU_STAT_DateTimeFormat : 29|2@0+ (1,0) [0|3] ""  IPC
 SG_ MHU_DISPLAY_STATUS : 23|2@0+ (1,0) [0|3] ""  IPC,CCU
 SG_ MHU_STAT_Language : 39|5@0+ (1,0) [0|31] ""  IPC

BO_ 267 MHU_BCM_RemoteClampCtrl_0x10B: 8 MHU
 SG_ TBOX_STAT_TerminalReq : 2|3@0+ (1,0) [0|7] "Bit"  GW
 SG_ TBOX_AuthCode_0x10B : 55|16@0+ (1,0) [0|65535] ""  GW

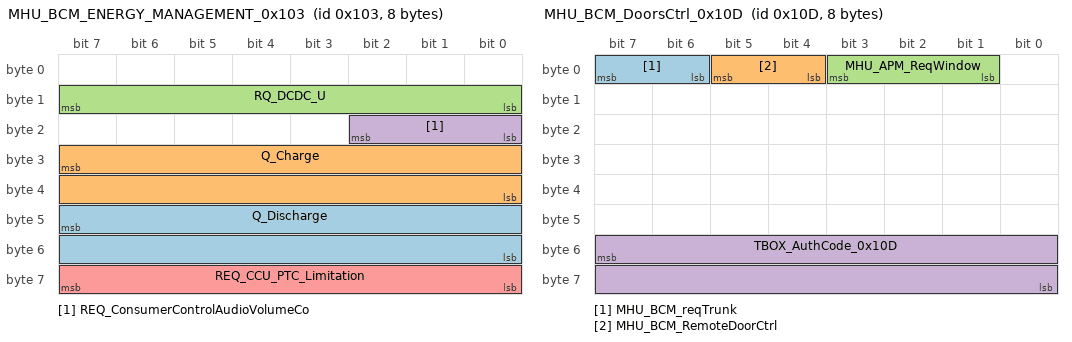
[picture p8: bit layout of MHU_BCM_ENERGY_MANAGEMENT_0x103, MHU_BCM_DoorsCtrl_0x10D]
BO_ 259 MHU_BCM_ENERGY_MANAGEMENT_0x103: 8 GW
 SG_ Q_Discharge : 47|16@0+ (0.125,0) [0|8191.75] "Ah"  MHU,CCU
 SG_ Q_Charge : 31|16@0+ (0.125,0) [0|8191.75] "Ah"  MHU,CCU
 SG_ RQ_DCDC_U : 15|8@0+ (0.1,0) [0|25.2] "Vol"  MHU,CCU
 SG_ REQ_ConsumerControlAudioVolumeCo : 18|3@0+ (1,0) [0|7] ""  MHU,CCU
 SG_ REQ_CCU_PTC_Limitation : 63|8@0+ (1,0) [0|100] "percent"  MHU,CCU

BO_ 269 MHU_BCM_DoorsCtrl_0x10D: 8 MHU
 SG_ MHU_BCM_reqTrunk : 7|2@0+ (1,0) [0|3] "Bit"  GW
 SG_ MHU_BCM_RemoteDoorCtrl : 5|2@0+ (1,0) [0|3] "Bit"  GW
 SG_ MHU_APM_ReqWindow : 3|3@0+ (1,0) [0|6] ""  GW
 SG_ TBOX_AuthCode_0x10D : 55|16@0+ (1,0) [0|65535] ""  GW

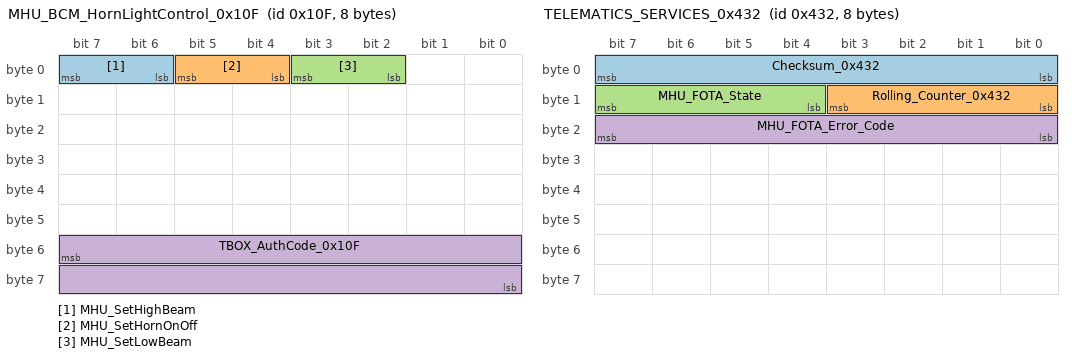
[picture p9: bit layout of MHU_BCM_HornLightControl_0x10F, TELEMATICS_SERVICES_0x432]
BO_ 271 MHU_BCM_HornLightControl_0x10F: 8 MHU
 SG_ MHU_SetHighBeam : 7|2@0+ (1,0) [0|2] ""  GW
 SG_ MHU_SetHornOnOff : 5|2@0+ (1,0) [0|2] ""  GW
 SG_ MHU_SetLowBeam : 3|2@0+ (1,0) [0|2] ""  GW
 SG_ TBOX_AuthCode_0x10F : 55|16@0+ (1,0) [0|65535] ""  GW

BO_ 1074 TELEMATICS_SERVICES_0x432: 8 MHU
 SG_ Checksum_0x432 : 7|8@0+ (1,0) [0|255] ""  GW,IPC,CCU
 SG_ Rolling_Counter_0x432 : 11|4@0+ (1,0) [0|14] ""  GW,IPC,CCU
 SG_ MHU_FOTA_State : 15|4@0+ (1,0) [0|14] ""  GW,IPC,CCU
 SG_ MHU_FOTA_Error_Code : 23|8@0+ (1,0) [0|255] ""  GW,IPC,CCU

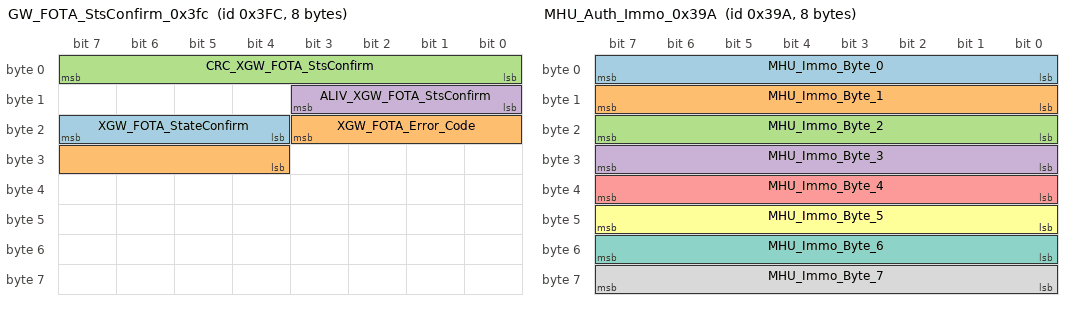
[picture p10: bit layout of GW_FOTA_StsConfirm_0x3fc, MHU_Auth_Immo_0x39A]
BO_ 1020 GW_FOTA_StsConfirm_0x3fc: 8 GW
 SG_ XGW_FOTA_StateConfirm : 23|4@0+ (1,0) [0|14] ""  MHU,IPC,CCU
 SG_ XGW_FOTA_Error_Code : 19|8@0+ (1,0) [0|255] ""  MHU
 SG_ CRC_XGW_FOTA_StsConfirm : 7|8@0+ (1,0) [0|255] ""  MHU
 SG_ ALIV_XGW_FOTA_StsConfirm : 11|4@0+ (1,0) [0|14] ""  MHU

BO_ 922 MHU_Auth_Immo_0x39A: 8 MHU
 SG_ MHU_Immo_Byte_0 : 7|8@0+ (1,0) [0|255] ""  GW
 SG_ MHU_Immo_Byte_1 : 15|8@0+ (1,0) [0|255] ""  GW
 SG_ MHU_Immo_Byte_2 : 23|8@0+ (1,0) [0|255] ""  GW
 SG_ MHU_Immo_Byte_3 : 31|8@0+ (1,0) [0|255] ""  GW
 SG_ MHU_Immo_Byte_4 : 39|8@0+ (1,0) [0|255] ""  GW
 SG_ MHU_Immo_Byte_5 : 47|8@0+ (1,0) [0|255] ""  GW
 SG_ MHU_Immo_Byte_6 : 55|8@0+ (1,0) [0|255] ""  GW
 SG_ MHU_Immo_Byte_7 : 63|8@0+ (1,0) [0|255] ""  GW

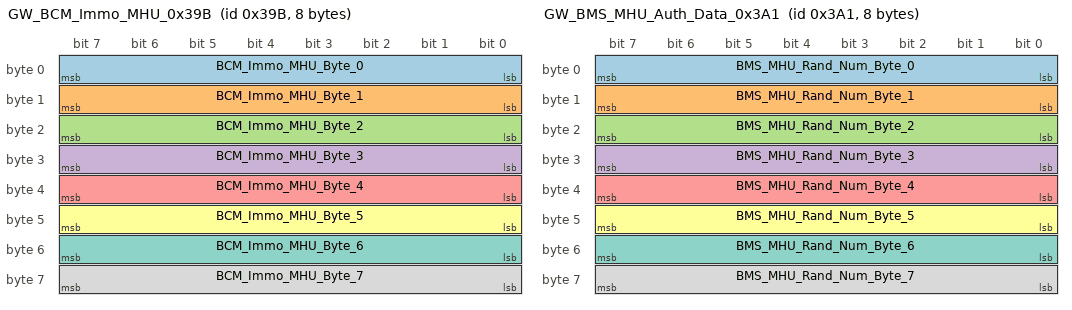
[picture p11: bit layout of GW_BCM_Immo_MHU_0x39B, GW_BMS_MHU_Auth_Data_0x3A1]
BO_ 923 GW_BCM_Immo_MHU_0x39B: 8 GW
 SG_ BCM_Immo_MHU_Byte_0 : 7|8@0+ (1,0) [0|255] ""  MHU
 SG_ BCM_Immo_MHU_Byte_1 : 15|8@0+ (1,0) [0|255] ""  MHU
 SG_ BCM_Immo_MHU_Byte_2 : 23|8@0+ (1,0) [0|255] ""  MHU
 SG_ BCM_Immo_MHU_Byte_3 : 31|8@0+ (1,0) [0|255] ""  MHU
 SG_ BCM_Immo_MHU_Byte_4 : 39|8@0+ (1,0) [0|255] ""  MHU
 SG_ BCM_Immo_MHU_Byte_5 : 47|8@0+ (1,0) [0|255] ""  MHU
 SG_ BCM_Immo_MHU_Byte_6 : 55|8@0+ (1,0) [0|255] ""  MHU
 SG_ BCM_Immo_MHU_Byte_7 : 63|8@0+ (1,0) [0|255] ""  MHU

BO_ 929 GW_BMS_MHU_Auth_Data_0x3A1: 8 GW
 SG_ BMS_MHU_Rand_Num_Byte_0 : 7|8@0+ (1,0) [0|255] ""  MHU
 SG_ BMS_MHU_Rand_Num_Byte_1 : 15|8@0+ (1,0) [0|255] ""  MHU
 SG_ BMS_MHU_Rand_Num_Byte_2 : 23|8@0+ (1,0) [0|255] ""  MHU
 SG_ BMS_MHU_Rand_Num_Byte_3 : 31|8@0+ (1,0) [0|255] ""  MHU
 SG_ BMS_MHU_Rand_Num_Byte_4 : 39|8@0+ (1,0) [0|255] ""  MHU
 SG_ BMS_MHU_Rand_Num_Byte_5 : 47|8@0+ (1,0) [0|255] ""  MHU
 SG_ BMS_MHU_Rand_Num_Byte_6 : 55|8@0+ (1,0) [0|255] ""  MHU
 SG_ BMS_MHU_Rand_Num_Byte_7 : 63|8@0+ (1,0) [0|255] ""  MHU

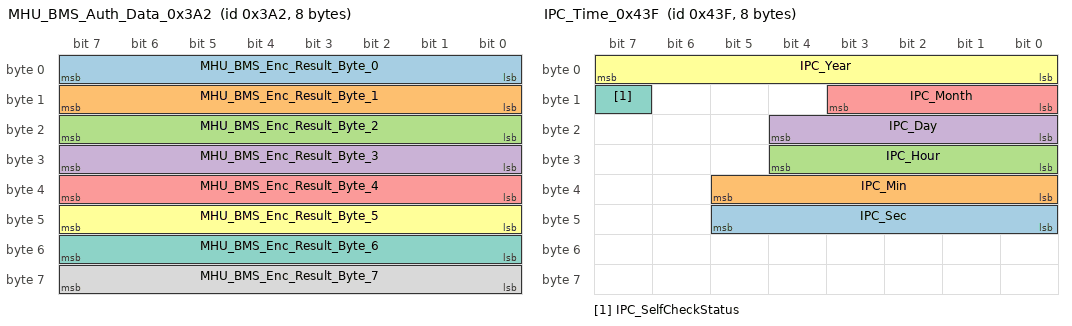
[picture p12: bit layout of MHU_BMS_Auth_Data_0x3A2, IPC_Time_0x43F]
BO_ 930 MHU_BMS_Auth_Data_0x3A2: 8 MHU
 SG_ MHU_BMS_Enc_Result_Byte_0 : 7|8@0+ (1,0) [0|255] ""  GW
 SG_ MHU_BMS_Enc_Result_Byte_1 : 15|8@0+ (1,0) [0|255] ""  GW
 SG_ MHU_BMS_Enc_Result_Byte_2 : 23|8@0+ (1,0) [0|255] ""  GW
 SG_ MHU_BMS_Enc_Result_Byte_3 : 31|8@0+ (1,0) [0|255] ""  GW
 SG_ MHU_BMS_Enc_Result_Byte_4 : 39|8@0+ (1,0) [0|255] ""  GW
 SG_ MHU_BMS_Enc_Result_Byte_5 : 47|8@0+ (1,0) [0|255] ""  GW
 SG_ MHU_BMS_Enc_Result_Byte_6 : 55|8@0+ (1,0) [0|255] ""  GW
 SG_ MHU_BMS_Enc_Result_Byte_7 : 63|8@0+ (1,0) [0|255] ""  GW

BO_ 931 GW_BMS_Sts2_0x3A3: 8 GW
 SG_ BMS_MHU_Auth_Sts : 7|2@0+ (1,0) [0|3] ""  MHU

BO_ 1087 IPC_Time_0x43F: 8 IPC
 SG_ IPC_Sec : 45|6@0+ (1,0) [0|59] "second"  GW,MHU,CCU
 SG_ IPC_Min : 37|6@0+ (1,0) [0|59] "min"  GW,MHU,CCU
 SG_ IPC_Hour : 28|5@0+ (1,0) [0|23] "hour"  GW,MHU,CCU
 SG_ IPC_Day : 20|5@0+ (1,0) [1|31] ""  GW,MHU,CCU
 SG_ IPC_Month : 11|4@0+ (1,0) [1|12] ""  GW,MHU,CCU
 SG_ IPC_Year : 7|8@0+ (1,2000) [2000|2255] ""  GW,MHU,CCU
 SG_ IPC_SelfCheckStatus : 15|1@0+ (1,0) [0|1] ""  GW,MHU,CCU

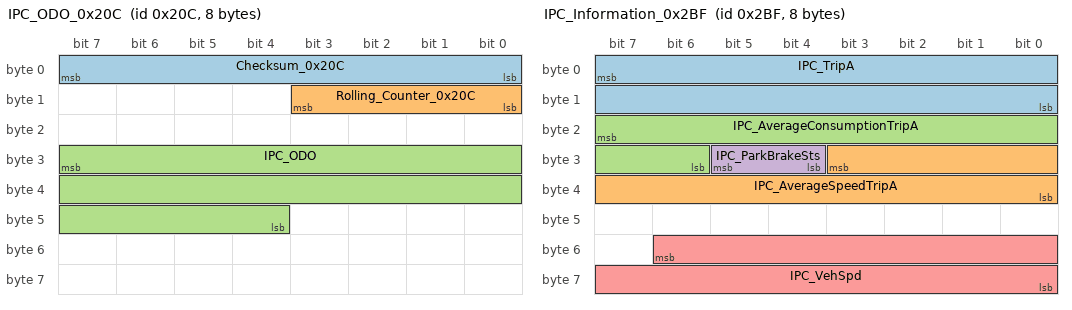
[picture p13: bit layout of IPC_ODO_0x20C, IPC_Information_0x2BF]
BO_ 524 IPC_ODO_0x20C: 8 IPC
 SG_ Checksum_0x20C : 7|8@0+ (1,0) [0|255] ""  GW,MHU
 SG_ Rolling_Counter_0x20C : 11|4@0+ (1,0) [0|15] ""  GW,MHU
 SG_ IPC_ODO : 31|20@0+ (1,0) [0|999999] "km"  GW,MHU,CCU

BO_ 703 IPC_Information_0x2BF: 8 IPC
 SG_ IPC_TripA : 7|16@0+ (0.1,0) [0|999.9] "km"  GW,MHU
 SG_ IPC_AverageSpeedTripA : 27|12@0+ (0.0625,0) [0|250] "km/h"  GW,MHU
 SG_ IPC_AverageConsumptionTripA : 23|10@0+ (0.1,0) [0|100] "kwh/100km"  GW,MHU
 SG_ IPC_ParkBrakeSts : 29|2@0+ (1,0) [0|3] ""  GW,MHU
 SG_ IPC_VehSpd : 54|15@0+ (0.01,0) [0|327.66] "kph"  GW,MHU,CCU

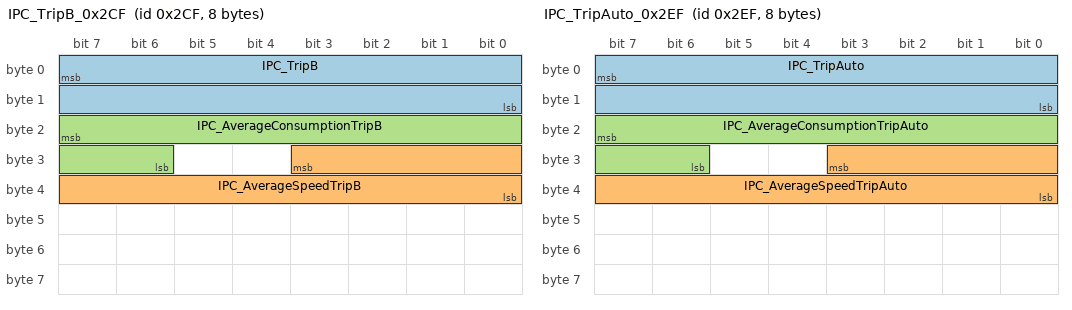
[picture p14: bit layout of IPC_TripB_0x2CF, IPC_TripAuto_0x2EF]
BO_ 719 IPC_TripB_0x2CF: 8 IPC
 SG_ IPC_TripB : 7|16@0+ (0.1,0) [0|999.9] "km"  MHU
 SG_ IPC_AverageSpeedTripB : 27|12@0+ (0.0625,0) [0|250] "km/h"  MHU
 SG_ IPC_AverageConsumptionTripB : 23|10@0+ (0.1,0) [0|100] "kwh/100km"  MHU

BO_ 751 IPC_TripAuto_0x2EF: 8 IPC
 SG_ IPC_TripAuto : 7|16@0+ (0.1,0) [0|999.9] "km"  MHU
 SG_ IPC_AverageSpeedTripAuto : 27|12@0+ (0.0625,0) [0|250] "km/h"  MHU
 SG_ IPC_AverageConsumptionTripAuto : 23|10@0+ (0.1,0) [0|100] "kwh/100km"  MHU

BO_ 735 IPC_TPMSReq_0x2DF: 8 IPC
 SG_ IPC_TireLearningReq_reserved : 1|2@0+ (1,0) [0|3] ""  GW
 SG_ IPC_TireResetReq : 7|2@0+ (1,0) [0|3] ""  GW

BO_ 975 IPC_Set_0x3CF: 8 IPC
 SG_ IPC_DimmingIPCLevel : 7|4@0+ (1,0) [0|15] ""  MHU

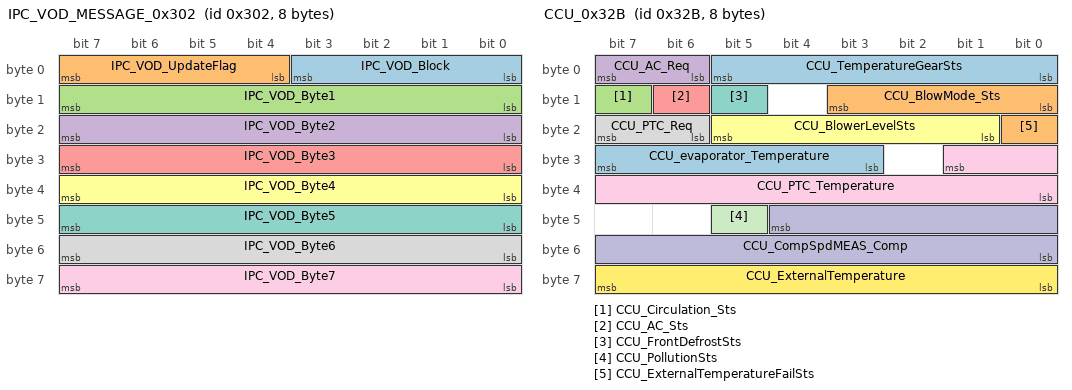
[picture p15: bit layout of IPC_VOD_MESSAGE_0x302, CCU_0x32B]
BO_ 770 IPC_VOD_MESSAGE_0x302: 8 IPC
 SG_ IPC_VOD_Block : 3|4@0+ (1,0) [0|7] ""  GW
 SG_ IPC_VOD_UpdateFlag : 7|4@0+ (1,0) [0|7] ""  GW
 SG_ IPC_VOD_Byte1 : 15|8@0+ (1,0) [0|255] ""  GW
 SG_ IPC_VOD_Byte2 : 23|8@0+ (1,0) [0|255] ""  GW
 SG_ IPC_VOD_Byte3 : 31|8@0+ (1,0) [0|255] ""  GW
 SG_ IPC_VOD_Byte4 : 39|8@0+ (1,0) [0|255] ""  GW
 SG_ IPC_VOD_Byte5 : 47|8@0+ (1,0) [0|255] ""  GW
 SG_ IPC_VOD_Byte6 : 55|8@0+ (1,0) [0|255] ""  GW
 SG_ IPC_VOD_Byte7 : 63|8@0+ (1,0) [0|255] ""  GW

BO_ 811 CCU_0x32B: 8 CCU
 SG_ CCU_TemperatureGearSts : 5|6@0+ (1,0) [0|63] ""  GW,MHU
 SG_ CCU_BlowMode_Sts : 11|4@0+ (1,0) [0|15] ""  GW,MHU
 SG_ CCU_Circulation_Sts : 15|1@0+ (1,0) [0|1] ""  GW,MHU
 SG_ CCU_AC_Req : 7|2@0+ (1,0) [0|3] ""  GW
 SG_ CCU_AC_Sts : 14|1@0+ (1,0) [0|1] ""  GW,MHU
 SG_ CCU_BlowerLevelSts : 21|5@0+ (1,0) [0|9] ""  GW,MHU
 SG_ CCU_FrontDefrostSts : 13|1@0+ (1,0) [0|1] ""  GW,MHU
 SG_ CCU_PTC_Req : 23|2@0+ (1,0) [0|3] ""  GW,MHU
 SG_ CCU_PTC_Temperature : 25|10@0+ (0.1,0) [0|100] "°C"  GW
 SG_ CCU_CompSpdMEAS_Comp : 44|13@0+ (1,0) [0|8191] "rpm"  GW
 SG_ CCU_PollutionSts : 45|1@0+ (1,0) [0|1] ""  MHU
 SG_ CCU_ExternalTemperature : 63|8@0+ (0.5,-40) [-40|87] "°C"  GW,MHU,IPC
 SG_ CCU_evaporator_Temperature : 31|5@0+ (1,-10) [-10|20] "°C"  GW
 SG_ CCU_ExternalTemperatureFailSts : 16|1@0+ (1,0) [0|1] ""  GW,MHU,IPC

BO_ 1037 GW_USS_Msg_0x40D: 8 GW
 SG_ USS_WorkSts : 23|1@0+ (1,0) [0|1] ""  MHU,IPC
 SG_ USS_FrnSysSts_reserved : 19|2@0+ (1,0) [0|3] ""  MHU,IPC
 SG_ USS_RearSysSts_reserved : 31|3@0+ (1,0) [0|7] ""  MHU,IPC
 SG_ USS_SndCadComm : 27|4@0+ (1,0) [0|15] ""  MHU,IPC
 SG_ USS_LFDistance_reserved : 39|4@0+ (1,0) [0|15] ""  MHU,IPC
 SG_ USS_RFDistance_reserved : 35|4@0+ (1,0) [0|15] ""  MHU,IPC
 SG_ USS_LRDistance : 47|4@0+ (1,0) [0|15] ""  MHU,IPC
 SG_ USS_LMRDistance : 43|4@0+ (1,0) [0|15] ""  MHU,IPC
 SG_ USS_RMRDistance : 55|4@0+ (1,0) [0|15] ""  MHU,IPC
 SG_ USS_RRDistance : 51|4@0+ (1,0) [0|15] ""  MHU,IPC
 SG_ USS_PrkAssSysSta : 56|1@0+ (1,0) [0|1] ""  MHU,IPC
 SG_ USS_FLSenSta_reserved : 57|1@0+ (1,0) [0|1] ""  MHU,IPC
 SG_ USS_FRSenSta_reserved : 58|1@0+ (1,0) [0|1] ""  MHU,IPC
 SG_ USS_RLSenSta : 59|1@0+ (1,0) [0|1] ""  MHU,IPC
 SG_ USS_RRSenSta : 60|1@0+ (1,0) [0|1] ""  MHU,IPC
 SG_ USS_RLMSenSta : 61|1@0+ (1,0) [0|1] ""  MHU,IPC
 SG_ USS_RRMSenSta : 62|1@0+ (1,0) [0|1] ""  MHU,IPC
 SG_ USS_SetSta : 21|2@0+ (1,0) [0|3] ""  MHU,IPC

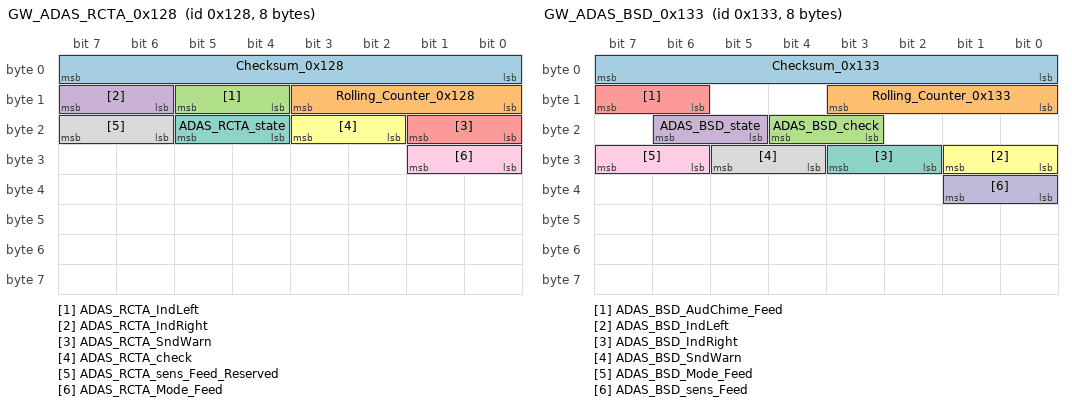
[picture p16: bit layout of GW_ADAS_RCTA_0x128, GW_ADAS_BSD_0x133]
BO_ 296 GW_ADAS_RCTA_0x128: 8 GW
 SG_ Checksum_0x128 : 7|8@0+ (1,0) [0|255] ""  MHU,IPC
 SG_ Rolling_Counter_0x128 : 11|4@0+ (1,0) [0|15] ""  MHU,IPC
 SG_ ADAS_RCTA_IndLeft : 13|2@0+ (1,0) [0|3] ""  MHU
 SG_ ADAS_RCTA_IndRight : 15|2@0+ (1,0) [0|3] ""  MHU
 SG_ ADAS_RCTA_SndWarn : 17|2@0+ (1,0) [0|3] ""  MHU
 SG_ ADAS_RCTA_check : 19|2@0+ (1,0) [0|3] ""  MHU,IPC
 SG_ ADAS_RCTA_state : 21|2@0+ (1,0) [0|3] ""  MHU
 SG_ ADAS_RCTA_sens_Feed_Reserved : 23|2@0+ (1,0) [0|3] ""  MHU
 SG_ ADAS_RCTA_Mode_Feed : 25|2@0+ (1,0) [0|3] ""  MHU

BO_ 307 GW_ADAS_BSD_0x133: 8 GW
 SG_ Checksum_0x133 : 7|8@0+ (1,0) [0|255] ""  MHU,IPC
 SG_ Rolling_Counter_0x133 : 11|4@0+ (1,0) [0|15] ""  MHU,IPC
 SG_ ADAS_BSD_check : 20|2@0+ (1,0) [0|3] ""  MHU,IPC
 SG_ ADAS_BSD_state : 22|2@0+ (1,0) [0|3] ""  MHU
 SG_ ADAS_BSD_AudChime_Feed : 15|2@0+ (1,0) [0|3] ""  MHU
 SG_ ADAS_BSD_IndLeft : 25|2@0+ (1,0) [0|3] ""  MHU
 SG_ ADAS_BSD_IndRight : 27|2@0+ (1,0) [0|3] ""  MHU
 SG_ ADAS_BSD_SndWarn : 29|2@0+ (1,0) [0|3] ""  MHU
 SG_ ADAS_BSD_Mode_Feed : 31|2@0+ (1,0) [0|3] ""  MHU
 SG_ ADAS_BSD_sens_Feed : 33|2@0+ (1,0) [0|3] ""  MHU

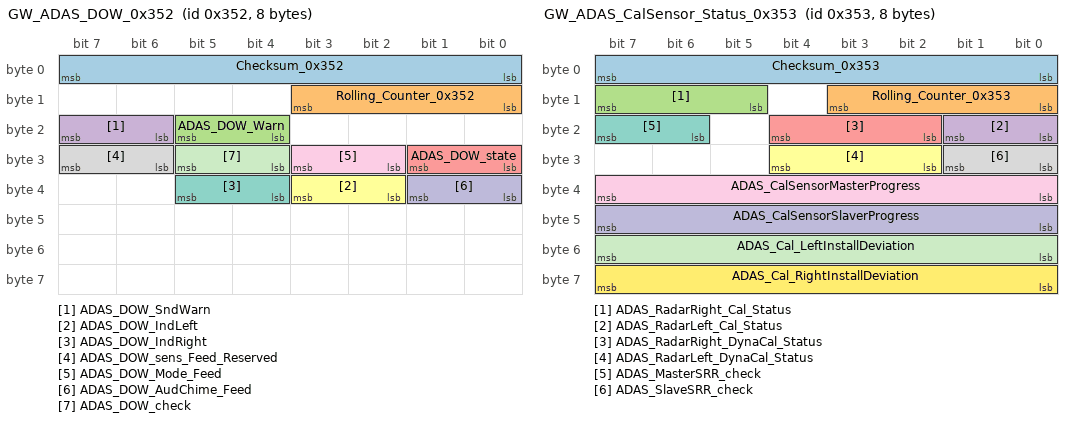
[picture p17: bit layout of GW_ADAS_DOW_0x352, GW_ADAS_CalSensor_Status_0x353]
BO_ 850 GW_ADAS_DOW_0x352: 8 GW
 SG_ Checksum_0x352 : 7|8@0+ (1,0) [0|255] ""  MHU,IPC
 SG_ Rolling_Counter_0x352 : 11|4@0+ (1,0) [0|15] ""  MHU,IPC
 SG_ ADAS_DOW_Warn : 21|2@0+ (1,0) [0|3] ""  MHU
 SG_ ADAS_DOW_SndWarn : 23|2@0+ (1,0) [0|3] ""  MHU
 SG_ ADAS_DOW_state : 25|2@0+ (1,0) [0|3] ""  MHU
 SG_ ADAS_DOW_IndLeft : 35|2@0+ (1,0) [0|3] ""  MHU
 SG_ ADAS_DOW_IndRight : 37|2@0+ (1,0) [0|3] ""  MHU
 SG_ ADAS_DOW_sens_Feed_Reserved : 31|2@0+ (1,0) [0|3] ""  MHU
 SG_ ADAS_DOW_Mode_Feed : 27|2@0+ (1,0) [0|3] ""  MHU
 SG_ ADAS_DOW_AudChime_Feed : 33|2@0+ (1,0) [0|3] ""  MHU
 SG_ ADAS_DOW_check : 29|2@0+ (1,0) [0|3] ""  MHU,IPC

BO_ 1216 GW_ADAS_WarnMsg_0x4C0: 8 GW
 SG_ Checksum_0x4C0 : 7|8@0+ (1,0) [0|255] ""  MHU,IPC
 SG_ Rolling_Counter_0x4C0 : 11|4@0+ (1,0) [0|15] ""  MHU,IPC
 SG_ ADAS_Warning_Flag_1 : 12|1@0+ (1,0) [0|1] ""  MHU,IPC
 SG_ ADAS_Warning_Flag_2 : 13|1@0+ (1,0) [0|1] ""  MHU,IPC
 SG_ ADAS_Warning_Flag_3 : 14|1@0+ (1,0) [0|1] ""  MHU,IPC
 SG_ ADAS_Warning_Flag_4 : 15|1@0+ (1,0) [0|1] ""  MHU,IPC
 SG_ ADAS_Warning_Flag_5 : 16|1@0+ (1,0) [0|1] ""  MHU,IPC
 SG_ ADAS_Warning_Flag_6 : 17|1@0+ (1,0) [0|1] ""  MHU,IPC
 SG_ ADAS_Warning_Flag_7 : 18|1@0+ (1,0) [0|1] ""  MHU,IPC
 SG_ ADAS_Warning_Flag_8 : 19|1@0+ (1,0) [0|1] ""  MHU,IPC
 SG_ ADAS_Warning_Flag_9 : 20|1@0+ (1,0) [0|1] ""  MHU,IPC
 SG_ ADAS_Warning_Flag_10 : 21|1@0+ (1,0) [0|1] ""  MHU,IPC
 SG_ ADAS_Warning_Flag_11 : 22|1@0+ (1,0) [0|1] ""  MHU,IPC
 SG_ ADAS_Warning_Flag_12 : 23|1@0+ (1,0) [0|1] ""  MHU,IPC
 SG_ ADAS_Warning_Flag_13 : 24|1@0+ (1,0) [0|1] ""  MHU,IPC
 SG_ ADAS_Warning_Flag_14 : 25|1@0+ (1,0) [0|1] ""  MHU,IPC
 SG_ ADAS_Warning_Flag_15 : 26|1@0+ (1,0) [0|1] ""  MHU,IPC
 SG_ ADAS_Warning_Flag_16 : 27|1@0+ (1,0) [0|1] ""  MHU,IPC
 SG_ ADAS_Warning_Flag_17 : 28|1@0+ (1,0) [0|1] ""  MHU,IPC
 SG_ ADAS_Warning_Flag_18 : 29|1@0+ (1,0) [0|1] ""  MHU,IPC
 SG_ ADAS_Warning_Flag_19 : 30|1@0+ (1,0) [0|1] ""  MHU,IPC
 SG_ ADAS_Warning_Flag_20 : 31|1@0+ (1,0) [0|1] ""  MHU,IPC
 SG_ ADAS_Warning_Flag_21 : 32|1@0+ (1,0) [0|1] ""  MHU,IPC
 SG_ ADAS_Warning_Flag_22 : 33|1@0+ (1,0) [0|1] ""  MHU,IPC
 SG_ ADAS_Warning_Flag_23 : 34|1@0+ (1,0) [0|1] ""  MHU,IPC
 SG_ ADAS_Warning_Flag_24 : 35|1@0+ (1,0) [0|1] ""  MHU,IPC
 SG_ ADAS_Warning_Flag_25 : 36|1@0+ (1,0) [0|1] ""  MHU,IPC
 SG_ ADAS_Warning_Flag_26 : 37|1@0+ (1,0) [0|1] ""  MHU,IPC
 SG_ ADAS_Warning_Flag_27 : 38|1@0+ (1,0) [0|1] ""  MHU,IPC
 SG_ ADAS_Warning_Flag_28 : 39|1@0+ (1,0) [0|1] ""  MHU,IPC
 SG_ ADAS_Reserved_signal3 : 47|8@0+ (1,0) [0|255] ""  MHU,IPC
 SG_ ADAS_Reserved_signal4 : 55|8@0+ (1,0) [0|255] ""  MHU,IPC
 SG_ ADAS_Reserved_signal5 : 63|8@0+ (1,0) [0|255] ""  MHU,IPC

BO_ 851 GW_ADAS_CalSensor_Status_0x353: 8 GW
 SG_ Checksum_0x353 : 7|8@0+ (1,0) [0|255] ""  MHU,IPC
 SG_ Rolling_Counter_0x353 : 11|4@0+ (1,0) [0|15] ""  MHU,IPC
 SG_ ADAS_RadarRight_Cal_Status : 15|3@0+ (1,0) [0|7] ""  MHU,IPC
 SG_ ADAS_RadarLeft_Cal_Status : 17|2@0+ (1,0) [0|3] ""  MHU,IPC
 SG_ ADAS_RadarRight_DynaCal_Status : 20|3@0+ (1,0) [0|7] ""  MHU,IPC
 SG_ ADAS_RadarLeft_DynaCal_Status : 28|3@0+ (1,0) [0|7] ""  MHU,IPC
 SG_ ADAS_MasterSRR_check : 23|2@0+ (1,0) [0|3] ""  MHU,IPC
 SG_ ADAS_SlaveSRR_check : 25|2@0+ (1,0) [0|3] ""  MHU,IPC
 SG_ ADAS_CalSensorMasterProgress : 39|8@0+ (0.4,0) [0|100] "%"  MHU
 SG_ ADAS_CalSensorSlaverProgress : 47|8@0+ (0.4,0) [0|100] "%"  MHU
 SG_ ADAS_Cal_LeftInstallDeviation : 55|8@0- (0.1,0) [-12.8|12.7] "deg"  MHU
 SG_ ADAS_Cal_RightInstallDeviation : 63|8@0- (0.1,0) [-12.8|12.7] "deg"  MHU

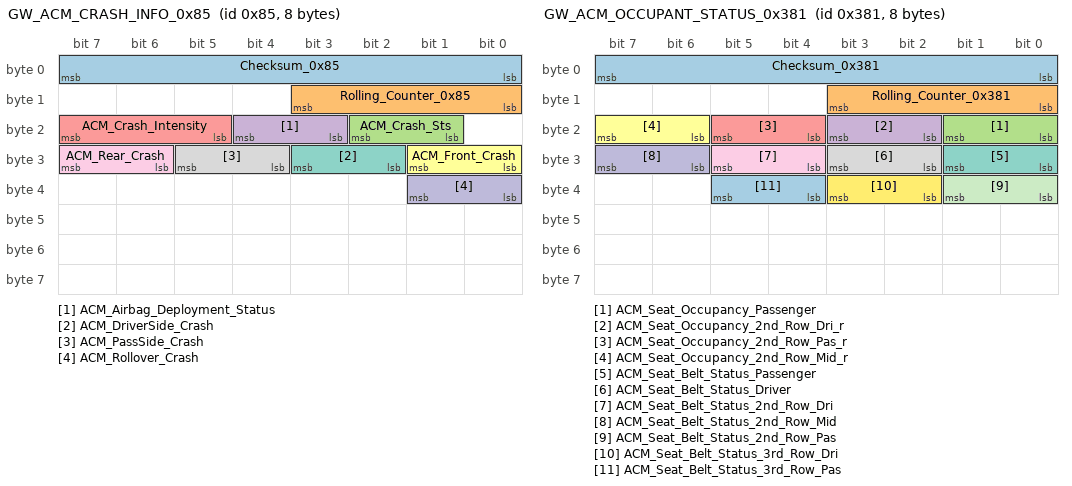
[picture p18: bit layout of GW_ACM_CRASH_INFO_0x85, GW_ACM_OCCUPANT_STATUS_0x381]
BO_ 133 GW_ACM_CRASH_INFO_0x85: 8 GW
 SG_ Checksum_0x85 : 7|8@0+ (1,0) [0|255] ""  MHU,IPC,CCU
 SG_ Rolling_Counter_0x85 : 11|4@0+ (1,0) [0|15] ""  MHU,IPC,CCU
 SG_ ACM_Crash_Sts : 18|2@0+ (1,0) [0|3] ""  MHU,IPC,CCU
 SG_ ACM_Airbag_Deployment_Status : 20|2@0+ (1,0) [0|3] ""  MHU,IPC
 SG_ ACM_Crash_Intensity : 23|3@0+ (1,0) [0|7] ""  MHU,IPC
 SG_ ACM_Front_Crash : 25|2@0+ (1,0) [0|3] ""  MHU,IPC
 SG_ ACM_DriverSide_Crash : 27|2@0+ (1,0) [0|3] ""  MHU,IPC
 SG_ ACM_PassSide_Crash : 29|2@0+ (1,0) [0|3] ""  MHU,IPC
 SG_ ACM_Rear_Crash : 31|2@0+ (1,0) [0|3] ""  MHU,IPC
 SG_ ACM_Rollover_Crash : 33|2@0+ (1,0) [0|3] ""  MHU,IPC

BO_ 897 GW_ACM_OCCUPANT_STATUS_0x381: 8 GW
 SG_ Checksum_0x381 : 7|8@0+ (1,0) [0|255] ""  MHU,IPC
 SG_ Rolling_Counter_0x381 : 11|4@0+ (1,0) [0|15] ""  MHU,IPC
 SG_ ACM_Seat_Occupancy_Passenger : 17|2@0+ (1,0) [0|3] ""  MHU,IPC
 SG_ ACM_Seat_Occupancy_2nd_Row_Dri_r : 19|2@0+ (1,0) [0|3] ""  MHU,IPC
 SG_ ACM_Seat_Occupancy_2nd_Row_Pas_r : 21|2@0+ (1,0) [0|3] ""  MHU,IPC
 SG_ ACM_Seat_Occupancy_2nd_Row_Mid_r : 23|2@0+ (1,0) [0|3] ""  MHU,IPC
 SG_ ACM_Seat_Belt_Status_Passenger : 25|2@0+ (1,0) [0|3] ""  MHU,IPC
 SG_ ACM_Seat_Belt_Status_Driver : 27|2@0+ (1,0) [0|3] ""  MHU,IPC
 SG_ ACM_Seat_Belt_Status_2nd_Row_Dri : 29|2@0+ (1,0) [0|3] ""  MHU,IPC
 SG_ ACM_Seat_Belt_Status_2nd_Row_Mid : 31|2@0+ (1,0) [0|3] ""  MHU,IPC
 SG_ ACM_Seat_Belt_Status_2nd_Row_Pas : 33|2@0+ (1,0) [0|3] ""  MHU,IPC
 SG_ ACM_Seat_Belt_Status_3rd_Row_Dri : 35|2@0+ (1,0) [0|3] ""  MHU,IPC
 SG_ ACM_Seat_Belt_Status_3rd_Row_Pas : 37|2@0+ (1,0) [0|3] ""  MHU,IPC

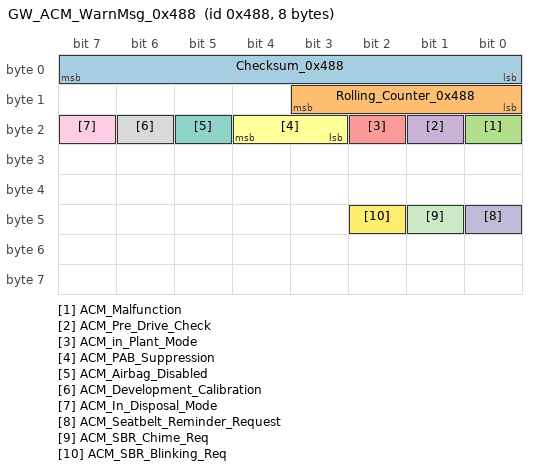
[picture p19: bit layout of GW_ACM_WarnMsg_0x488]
BO_ 1160 GW_ACM_WarnMsg_0x488: 8 GW
 SG_ Checksum_0x488 : 7|8@0+ (1,0) [0|255] ""  MHU,IPC
 SG_ Rolling_Counter_0x488 : 11|4@0+ (1,0) [0|15] ""  MHU,IPC
 SG_ ACM_Malfunction : 16|1@0+ (1,0) [0|1] ""  MHU,IPC
 SG_ ACM_Pre_Drive_Check : 17|1@0+ (1,0) [0|1] "Bit"  MHU,IPC
 SG_ ACM_in_Plant_Mode : 18|1@0+ (1,0) [0|1] "Bit"  MHU,IPC
 SG_ ACM_PAB_Suppression : 20|2@0+ (1,0) [0|3] "Bit"  MHU,IPC
 SG_ ACM_Airbag_Disabled : 21|1@0+ (1,0) [0|1] ""  MHU,IPC
 SG_ ACM_Development_Calibration : 22|1@0+ (1,0) [0|1] ""  MHU,IPC
 SG_ ACM_In_Disposal_Mode : 23|1@0+ (1,0) [0|1] ""  MHU,IPC
 SG_ ACM_Seatbelt_Reminder_Request : 40|1@0+ (1,0) [0|1] ""  MHU,IPC
 SG_ ACM_SBR_Chime_Req : 41|1@0+ (1,0) [0|1] ""  MHU,IPC
 SG_ ACM_SBR_Blinking_Req : 42|1@0+ (1,0) [0|1] ""  MHU,IPC

CM_ SG_ 1191 MHU_BTPairing "BT Pairing status";
CM_ SG_ 1191 MHU_MaintenanceEvent "Dynamic Maintainace Event Status";
CM_ SG_ 1191 MHU_Arrow "Arrow direction";
CM_ SG_ 215 MHU_SET_Second "MHU SET time :Second to IPC";
CM_ SG_ 215 MHU_SET_Min "MHU SET time:Minute to IPC";
CM_ SG_ 215 MHU_SET_Hour "MHU SET time :Hour to IPC";
CM_ SG_ 215 MHU_SET_Day "MHU SET time :Day to IPC";
CM_ SG_ 215 MHU_SET_Month "MHU SET time :Month to IPC";
CM_ SG_ 215 MHU_SET_Year "MHU SET time :Year to IPC";
CM_ SG_ 967 MHU_VehsSpd_Warn "MHU  To Configure  OverSpeed Threshold";
CM_ SG_ 967 MHU_SET_Volume "MHU SET IPC volume";
CM_ SG_ 967 MHU_St_DimmingIPC "MHU  Background lump level setting to IPC";
CM_ SG_ 711 MHU_FavoriteFlag "Favorite Flag information";
CM_ SG_ 711 MHU_AMRadioFrequanceValue "AM Radio Frequance Value";
CM_ SG_ 711 MHU_FMRadioFrequanceValue "FM Radio Frequance Value";
CM_ SG_ 711 MHU_SourceStationMode_Reserved "MHU Source Station Mode";
CM_ SG_ 711 MHU_Route_Reserved "navigation route statue";
CM_ SG_ 711 MHU_Distance "Navigation residual distance";
CM_ SG_ 695 MHU_MediaType "Media Type";
CM_ SG_ 695 MHU_MediaStatus_Reserved "Media Status";
CM_ SG_ 695 MHU_MediaProgress_Reserved "Media Progress";
CM_ SG_ 695 MHU_MediaDuration_Reserved "Media Duration";
CM_ SG_ 695 MHU_PhoneStatus "Phone Status";
CM_ SG_ 695 MHU_PhoneTime "Phone Time";
CM_ SG_ 695 MHU_NaviType "Navi Type";
CM_ SG_ 695 MHU_NaviStatus "Navi Status";
CM_ SG_ 695 MHU_Destination_Reachsts "Destination reached state";
CM_ SG_ 679 MHU_Destination "Destination nameDestinationNameLength(low 5 bits)+(high 3 bits resevered)+DestinationName(utf8)";
CM_ SG_ 679 MHU_DestinationInfo1_Num "msg total num";
CM_ SG_ 679 MHU_DestinationInfo1_Ind "msg index";
CM_ SG_ 727 MHU_MediaInfo_Num "msg total num";
CM_ SG_ 727 MHU_MediaInfo_Ind "msg index";
CM_ SG_ 727 MHU_MediaInfo_Content "Media InformationMedia Name Length(low 5bits)+(high 3 bits resevered)+Media Name(utf8)+Album Name Length(low 5 bits)+(high 3 bits resevered)+Album Name(utf8)+SingerNameLength(loe 5 bits)+(high 5 bits resevered)+SingerName(utf8)";
CM_ SG_ 743 MHU_PhoneInfo_Num "msg total num";
CM_ SG_ 743 MHU_PhoneInfo_Ind "msg index";
CM_ SG_ 743 MHU_PhoneInfo_Contact "Contact InformationContactNameLength(low 5 bits)+(high 3 bits resevered)+ConnectorName(utf8)";
CM_ SG_ 759 MHU_CallLog_Num "msg total num";
CM_ SG_ 759 MHU_CallLog_Ind "msg index";
CM_ SG_ 759 MHU_CallLog "Call Log InformationCall Log ID(4bits)+Call Log type(2bits)+(2bits resevered)+Call Log Length(5bits)+(3 bits resevered)+Call Log Content(utf8)01 20 06 61 62 63 64 65 11 66 xx xx xx xx xx xx00 11 03 41 42 43 xx xx";
CM_ SG_ 999 MHU_PhoneType "Phone typephone type Length(5bits)+(3 bits resevered)+phone type Content(utf8)";
CM_ SG_ 983 MHU_PhoneName "phone namephone name Length(5bits)+(3 bits resevered)+phone name Content(utf8)";
CM_ SG_ 503 MHU_Compass "compass information";
CM_ SG_ 503 MHU_Roundabout "Roundabout information";
CM_ SG_ 503 MHU_USBConnect "USB statusUSB";
CM_ SG_ 503 MHU_VolumeStatus "MHU volume status 0~30";
CM_ SG_ 503 MHU_MEDIA_MUTE "MHU speaker status";
CM_ SG_ 503 MHU_PollutionReq "Pollution mode request signal";
CM_ SG_ 503 MHU_NextTurnDistance "next cross distance";
CM_ SG_ 852 MHU_BSD_On "BSD On off";
CM_ SG_ 852 MHU_BSD_sens_Reserved "BSD Sensitivity (Early   Normal   Late)";
CM_ SG_ 852 MHU_BSD_AudWarning "Setting Audible warning for BSD On off";
CM_ SG_ 852 MHU_RCTA_On "RCTA On off";
CM_ SG_ 852 MHU_RCTA_sens_Reserved "RCTA Sensitivity (Early   Normal   Late)";
CM_ SG_ 852 MHU_PA_On "PA On off";
CM_ SG_ 852 MHU_DOW_Mode "Door Open Warning Mode select";
CM_ SG_ 852 MHU_DOW_sens_Reserved "DOW Sensitivity (Early   Normal   Late)";
CM_ SG_ 852 MHU_DOW_AudWarning "DOW audit chime On off";
CM_ SG_ 1025 MHU_SET_DoorSpeedLock "Setting Door speed lock mode";
CM_ SG_ 1025 MHU_SET_RemoteDoorUnlock_reserve "Setting which door will be unlocked when car unlock";
CM_ SG_ 1025 MHU_SET_RemoteLockFeedback "Setting remote car lock or unlock feedback mechanism";
CM_ SG_ 1025 MHU_SET_AutoUnlockDoor "Setting auto unlock door mode Park Engine off Manual";
CM_ SG_ 1025 MHU_SET_MirrorAuto_reserved "Change mirror auto mode";
CM_ SG_ 1025 MHU_Anti_theftAlarmSet "Anti theft Alarm Set";
CM_ SG_ 1025 MHU_TriggerReadKey "Trigger BCM to read KeyFOB ID";
CM_ SG_ 1026 MHU_Heatrearglass_Set "Heating command";
CM_ SG_ 1026 MHU_SET_DayTimeRunningLight_rese "On Off Day Time Running Light";
CM_ SG_ 1026 MHU_SET_FollowMeHomeTime "Set the time of Follow Me Home light";
CM_ SG_ 1027 Checksum_0x403 "Checksum";
CM_ SG_ 1027 Rolling_Counter_0x403 "Rolling_Counter";
CM_ SG_ 1027 MHU_SET_TCS_OnOff "Change TCS mode ON/OFF";
CM_ SG_ 1027 MHU_SET_DrivingModeSwitch "Change vehicle driving mode";
CM_ SG_ 1027 MHU_SET_RegenLevel "Set power regenerative level";
CM_ SG_ 1027 MHU_VCU_CreepDisable_stt "Request for VCU to disable creep function";
CM_ SG_ 1027 MHU_ChargeSetTargetSOC "Request for VCU to set target HV SOC";
CM_ SG_ 1027 MHU_HVACTurnON "Turning ON HVAC remotely";
CM_ SG_ 1027 MHU_ChargeScheduleSet "Request for VCU to enable/disable Charging Scheduling";
CM_ SG_ 1027 MHU_ChargingRequest "Request for VCU to ON/OFF Charging when schedule is reached";
CM_ SG_ 1027 MHU_ValetMode_Activation "Activate Valet mode from MHU";
CM_ SG_ 1027 MHU_ValetMode_MaxSpeed "Setting of maximum allowable in valet mode";
CM_ SG_ 807 MHU_CCU_AC_Button "Compressor Request Button";
CM_ SG_ 807 MHU_REC_Button "Loop mode Button";
CM_ SG_ 807 MHU_SetBlowMode "Set AC Mode";
CM_ SG_ 807 MHU_BlowerLevelSetting "Blower Level Setting";
CM_ SG_ 807 MHU_SetDriverTemp "Set Driver AC Temp level";
CM_ SG_ 807 MHU_ACM_Reserved "Air Conditioning PTC Switches(for new energy models with PTC only)";
CM_ SG_ 807 MHU_FrontDefrostReq_Reserved "Front Defrost Req";
CM_ SG_ 1058 Checksum_0x422 "Checksum";
CM_ SG_ 1058 Rolling_Counter_0x422 "Rolling_Counter";
CM_ SG_ 1058 MHU_STAT_DateTimeFormat "Indicate current date time format (12H and 24H)";
CM_ SG_ 1058 MHU_DISPLAY_STATUS "MHU for screen status";
CM_ SG_ 1058 MHU_STAT_Language "Indicate current Language";
CM_ SG_ 267 TBOX_STAT_TerminalReq "CAR state switching request";
CM_ SG_ 267 TBOX_AuthCode_0x10B "TBOX Message Authentication Code of message 0x10B";
CM_ SG_ 259 Q_Discharge "Negative";
CM_ SG_ 259 Q_Charge "Positive";
CM_ SG_ 259 RQ_DCDC_U "Voltage request for DCDC using power management";
CM_ SG_ 259 REQ_ConsumerControlAudioVolumeCo "Consumer control audio volume for powermanagement";
CM_ SG_ 259 REQ_CCU_PTC_Limitation "Consumer control PTC for powermanagement";
CM_ SG_ 269 MHU_BCM_reqTrunk "MHU Set Trunk Ajar Door or Tailgate";
CM_ SG_ 269 MHU_BCM_RemoteDoorCtrl "MHU set door state remotely.";
CM_ SG_ 269 MHU_APM_ReqWindow "Request control Window from MHU";
CM_ SG_ 269 TBOX_AuthCode_0x10D "TBOX Message Authentication Code of message 0x10D";
CM_ SG_ 271 MHU_SetHighBeam "Set high beam light ON/FF";
CM_ SG_ 271 MHU_SetHornOnOff "Set horn ON/OFF";
CM_ SG_ 271 MHU_SetLowBeam "Set low beam light ON/FF";
CM_ SG_ 271 TBOX_AuthCode_0x10F "TBOX Message Authentication Code of message 0x10F";
CM_ SG_ 1074 Checksum_0x432 "Checksum";
CM_ SG_ 1074 Rolling_Counter_0x432 "Rolling_Counter";
CM_ SG_ 1074 MHU_FOTA_State "FOTA global status";
CM_ SG_ 1074 MHU_FOTA_Error_Code "FOTA Error Code";
CM_ SG_ 1020 XGW_FOTA_StateConfirm "XGW FOTA global status confirmation";
CM_ SG_ 1020 XGW_FOTA_Error_Code "The signal FOTA Error Code indicates the status of the fota conditions:Bit 0:FOTA_MODE_COND_1: Vehicle StandstillBit 1:FOTA_MODE_COND_2: Low-voltage System VoltageBit 2:FOTA_MODE_COND_3: Engine/Motor is not runningBit 3:FOTA_MODE_COND_4: Last valid value of the signal MHU_FOTA_State signal is FOTA FLASHING or REMOTE DIAGNOSTICSBit 4:FOTA_MODE_COND_5: OBD diagnostic task not active.Bit 5:FOTA_MODE_COND_6: Ignition in start positionBit 6: Reserved. Set to 0 by default.Bit 7: Reserved. Set to 0 by default.00-----0: FOTA_MODE_COND_1 passed.00----0-: FOTA_MODE_COND_2 passed.00---0--: FOTA_MODE_COND_3 passed.00--0---: FOTA_MODE_COND_4 passed.00-0----: FOTA_MODE_COND_5 passed.000-----: FOTA_MODE_COND_6 passed.00-----1: FOTA_MODE_COND_1 failed.00----1-: FOTA_MODE_COND_2 failed.00---1--: FOTA_MODE_COND_3 failed.00--1---: FOTA_MODE_COND_4 failed.00-1----: FOTA_MODE_COND_5 failed.001-----: FOTA_MODE_COND_6 failed";
CM_ SG_ 1020 CRC_XGW_FOTA_StsConfirm "FOTA global status message checksum";
CM_ SG_ 1020 ALIV_XGW_FOTA_StsConfirm "FOTA global status message alive counter";
CM_ SG_ 922 MHU_Immo_Byte_0 "MHU Authentication signal byte 0";
CM_ SG_ 922 MHU_Immo_Byte_1 "MHU Authentication signal byte 1";
CM_ SG_ 922 MHU_Immo_Byte_2 "MHU Authentication signal byte 2";
CM_ SG_ 922 MHU_Immo_Byte_3 "MHU Authentication signal byte 3";
CM_ SG_ 922 MHU_Immo_Byte_4 "MHU Authentication signal byte 4";
CM_ SG_ 922 MHU_Immo_Byte_5 "MHU Authentication signal byte 5";
CM_ SG_ 922 MHU_Immo_Byte_6 "MHU Authentication signal byte 6";
CM_ SG_ 922 MHU_Immo_Byte_7 "MHU Authentication signal byte 7";
CM_ SG_ 923 BCM_Immo_MHU_Byte_0 "BCM Authentication signal byte 0 with MHU";
CM_ SG_ 923 BCM_Immo_MHU_Byte_1 "BCM Authentication signal byte 1 with MHU";
CM_ SG_ 923 BCM_Immo_MHU_Byte_2 "BCM Authentication signal byte 2 with MHU";
CM_ SG_ 923 BCM_Immo_MHU_Byte_3 "BCM Authentication signal byte 3 with MHU";
CM_ SG_ 923 BCM_Immo_MHU_Byte_4 "BCM Authentication signal byte 4 with MHU";
CM_ SG_ 923 BCM_Immo_MHU_Byte_5 "BCM Authentication signal byte 5 with MHU";
CM_ SG_ 923 BCM_Immo_MHU_Byte_6 "BCM Authentication signal byte 6 with MHU";
CM_ SG_ 923 BCM_Immo_MHU_Byte_7 "BCM Authentication signal byte 7 with MHU";
CM_ SG_ 929 BMS_MHU_Rand_Num_Byte_0 "Random number sent by BMS";
CM_ SG_ 929 BMS_MHU_Rand_Num_Byte_1 "Random number sent by BMS";
CM_ SG_ 929 BMS_MHU_Rand_Num_Byte_2 "Random number sent by BMS";
CM_ SG_ 929 BMS_MHU_Rand_Num_Byte_3 "Random number sent by BMS";
CM_ SG_ 929 BMS_MHU_Rand_Num_Byte_4 "Random number sent by BMS";
CM_ SG_ 929 BMS_MHU_Rand_Num_Byte_5 "Random number sent by BMS";
CM_ SG_ 929 BMS_MHU_Rand_Num_Byte_6 "Random number sent by BMS";
CM_ SG_ 929 BMS_MHU_Rand_Num_Byte_7 "Random number sent by BMS";
CM_ SG_ 930 MHU_BMS_Enc_Result_Byte_0 "MHU Encryption result";
CM_ SG_ 930 MHU_BMS_Enc_Result_Byte_1 "MHU Encryption result";
CM_ SG_ 930 MHU_BMS_Enc_Result_Byte_2 "MHU Encryption result";
CM_ SG_ 930 MHU_BMS_Enc_Result_Byte_3 "MHU Encryption result";
CM_ SG_ 930 MHU_BMS_Enc_Result_Byte_4 "MHU Encryption result";
CM_ SG_ 930 MHU_BMS_Enc_Result_Byte_5 "MHU Encryption result";
CM_ SG_ 930 MHU_BMS_Enc_Result_Byte_6 "MHU Encryption result";
CM_ SG_ 930 MHU_BMS_Enc_Result_Byte_7 "MHU Encryption result";
CM_ SG_ 931 BMS_MHU_Auth_Sts "BMS and MHU Authentication status";
CM_ SG_ 1087 IPC_Sec "Represents the current second.60 - 63 = Invalid";
CM_ SG_ 1087 IPC_Min "Represents the current minute. 60 - 63 = Invalid";
CM_ SG_ 1087 IPC_Hour "Represents the current hour, 24 - 30 = not used";
CM_ SG_ 1087 IPC_Day "Represents the current dayInvalid value = 0";
CM_ SG_ 1087 IPC_Month "Represents the current month.0, 13 to 15 = Invalid";
CM_ SG_ 1087 IPC_Year "Represents the current year.";
CM_ SG_ 1087 IPC_SelfCheckStatus "Power on self check status";
CM_ SG_ 524 Checksum_0x20C "Checksum";
CM_ SG_ 524 Rolling_Counter_0x20C "Rolling_Counter";
CM_ SG_ 524 IPC_ODO "odograph";
CM_ SG_ 703 IPC_TripA "Set Trip A";
CM_ SG_ 703 IPC_AverageSpeedTripA "Average Speed of TripA";
CM_ SG_ 703 IPC_AverageConsumptionTripA "Average Consumption of TripA";
CM_ SG_ 703 IPC_ParkBrakeSts "Park Brake Status";
CM_ SG_ 703 IPC_VehSpd "Current Displayed Longitudinal Vehicle Speed";
CM_ SG_ 719 IPC_TripB "Set Trip B";
CM_ SG_ 719 IPC_AverageSpeedTripB "Average Speed of TripB";
CM_ SG_ 719 IPC_AverageConsumptionTripB "Average Consumption of TripB";
CM_ SG_ 751 IPC_TripAuto "Set Trip Auto";
CM_ SG_ 751 IPC_AverageSpeedTripAuto "Average Speed of TripAuto";
CM_ SG_ 751 IPC_AverageConsumptionTripAuto "Average Consumption of TripAuto";
CM_ SG_ 735 IPC_TireLearningReq_reserved "IPC request to ready to learning";
CM_ SG_ 735 IPC_TireResetReq "IPC request iTPMS reset";
CM_ SG_ 975 IPC_DimmingIPCLevel "Dimming Level of IPC";
CM_ SG_ 811 CCU_TemperatureGearSts "Temperature Gear Status";
CM_ SG_ 811 CCU_BlowMode_Sts "Blow Mode_Status";
CM_ SG_ 811 CCU_Circulation_Sts "CCU intake cycle state";
CM_ SG_ 811 CCU_AC_Req "Compressor request switch signal";
CM_ SG_ 811 CCU_AC_Sts "AC Status";
CM_ SG_ 811 CCU_BlowerLevelSts "Blower_Level";
CM_ SG_ 811 CCU_FrontDefrostSts "Defrost_Status";
CM_ SG_ 811 CCU_PTC_Req "CCU request VCU to enable or disable PTC";
CM_ SG_ 811 CCU_PTC_Temperature "PTC Temperature";
CM_ SG_ 811 CCU_CompSpdMEAS_Comp "Compressor speed signal";
CM_ SG_ 811 CCU_PollutionSts "Pollution mode state";
CM_ SG_ 811 CCU_ExternalTemperature "External Temperature";
CM_ SG_ 811 CCU_evaporator_Temperature "evaporator Temperature";
CM_ SG_ 811 CCU_ExternalTemperatureFailSts "External Temperature Fail Sts";
CM_ SG_ 1037 USS_WorkSts "RPAS Work Status";
CM_ SG_ 1037 USS_FrnSysSts_reserved "Park Assistant Front System Status";
CM_ SG_ 1037 USS_RearSysSts_reserved "Park Assistant Rear System Status";
CM_ SG_ 1037 USS_SndCadComm "Park Assistant Sound Cadence Command";
CM_ SG_ 1037 USS_LFDistance_reserved "Distance Rrom Front Left Sensor";
CM_ SG_ 1037 USS_RFDistance_reserved "Distance From Front Right Sensor";
CM_ SG_ 1037 USS_LRDistance "Distance From Rear Left Sensor";
CM_ SG_ 1037 USS_LMRDistance "Distance From Rear Left Middle Sensor";
CM_ SG_ 1037 USS_RMRDistance "Distance From Rear Right Middle Sensor";
CM_ SG_ 1037 USS_RRDistance "Distance From Rear Right Sensor";
CM_ SG_ 1037 USS_PrkAssSysSta "Park Assistant System Status （Don't Include Sensor Error）";
CM_ SG_ 1037 USS_FLSenSta_reserved "Front Left Sensor Status";
CM_ SG_ 1037 USS_FRSenSta_reserved "Front Right sensor Status";
CM_ SG_ 1037 USS_RLSenSta "Rear Left Sensor Status";
CM_ SG_ 1037 USS_RRSenSta "Rear Right Sensor Status";
CM_ SG_ 1037 USS_RLMSenSta "Rear Left Middle Sensor Status";
CM_ SG_ 1037 USS_RRMSenSta "Rear Right Middle Sensor Status";
CM_ SG_ 1037 USS_SetSta "Reversing Radar Sensor Set status";
CM_ SG_ 296 Checksum_0x128 "Checksum";
CM_ SG_ 296 Rolling_Counter_0x128 "Rolling_Counter";
CM_ SG_ 296 ADAS_RCTA_IndLeft "Left Rear Cross Traffic Alert (RCTA) System Warning";
CM_ SG_ 296 ADAS_RCTA_IndRight "Right Rear Cross Traffic Alert (RCTA) System Warning";
CM_ SG_ 296 ADAS_RCTA_SndWarn "Rear Cross Traffic Alert warning sound en disable";
CM_ SG_ 296 ADAS_RCTA_check "Rear Cross Traffic Alert Check";
CM_ SG_ 296 ADAS_RCTA_state "Rear Cross Traffic Alert  Warning State";
CM_ SG_ 296 ADAS_RCTA_sens_Feed_Reserved "Rear Cross Traffic Alert  Warning Sensitivity Feedback";
CM_ SG_ 296 ADAS_RCTA_Mode_Feed "Rear Cross Traffic Alert  Warning On Off Feedback";
CM_ SG_ 307 Checksum_0x133 "Checksum";
CM_ SG_ 307 Rolling_Counter_0x133 "Rolling_Counter";
CM_ SG_ 307 ADAS_BSD_check "Blind Sport Detection Check";
CM_ SG_ 307 ADAS_BSD_state "Blind Sport Detection State Feedback";
CM_ SG_ 307 ADAS_BSD_AudChime_Feed "Blind Sport Detection Audible Chime Feedback";
CM_ SG_ 307 ADAS_BSD_IndLeft "Left Blind Sport Detection Warning";
CM_ SG_ 307 ADAS_BSD_IndRight "Right Blind Sport Detection Warning";
CM_ SG_ 307 ADAS_BSD_SndWarn "Rear Blind Sport Detection warning sound en disable";
CM_ SG_ 307 ADAS_BSD_Mode_Feed "Blind Sport Detection On Off Feedback";
CM_ SG_ 307 ADAS_BSD_sens_Feed "Blind Sport Detection sensitivity Feedback";
CM_ SG_ 850 Checksum_0x352 "Checksum";
CM_ SG_ 850 Rolling_Counter_0x352 "Rolling_Counter";
CM_ SG_ 850 ADAS_DOW_Warn "Left Right Door Open Warning";
CM_ SG_ 850 ADAS_DOW_SndWarn "Door Open Sound Warning en disable";
CM_ SG_ 850 ADAS_DOW_state "Door Open Warning State";
CM_ SG_ 850 ADAS_DOW_IndLeft "Left   Door Open Warning";
CM_ SG_ 850 ADAS_DOW_IndRight "Right Door Open Warning";
CM_ SG_ 850 ADAS_DOW_sens_Feed_Reserved "Door Open Warning sensitivity Feedback";
CM_ SG_ 850 ADAS_DOW_Mode_Feed "Door Open Warning Mode select Feedback";
CM_ SG_ 850 ADAS_DOW_AudChime_Feed "DOW audit chime On off Feedback";
CM_ SG_ 850 ADAS_DOW_check "Door Opening Warning Check";
CM_ SG_ 1216 Checksum_0x4C0 "Checksum";
CM_ SG_ 1216 Rolling_Counter_0x4C0 "Rolling_Counter";
CM_ SG_ 1216 ADAS_Warning_Flag_1 "Warning Message Flag, Component owner, Supplier align and define for this signal";
CM_ SG_ 1216 ADAS_Warning_Flag_2 "Warning Message Flag, Component owner, Supplier align and define for this signal";
CM_ SG_ 1216 ADAS_Warning_Flag_3 "Warning Message Flag, Component owner, Supplier align and define for this signal";
CM_ SG_ 1216 ADAS_Warning_Flag_4 "Warning Message Flag, Component owner, Supplier align and define for this signal";
CM_ SG_ 1216 ADAS_Warning_Flag_5 "Warning Message Flag, Component owner, Supplier align and define for this signal";
CM_ SG_ 1216 ADAS_Warning_Flag_6 "Warning Message Flag, Component owner, Supplier align and define for this signal";
CM_ SG_ 1216 ADAS_Warning_Flag_7 "Corner Short Range Rear Left Radar temporary not available";
CM_ SG_ 1216 ADAS_Warning_Flag_8 "Corner Short Range Rear Left Radar permanently not available";
CM_ SG_ 1216 ADAS_Warning_Flag_9 "Corner Short Range Rear Right Radar temporary not available";
CM_ SG_ 1216 ADAS_Warning_Flag_10 "Corner Short Range Rear Right Radar permanently not available";
CM_ SG_ 1216 ADAS_Warning_Flag_11 "Warning Message Flag, Component owner, Supplier align and define for this signal";
CM_ SG_ 1216 ADAS_Warning_Flag_12 "Warning Message Flag, Component owner, Supplier align and define for this signal";
CM_ SG_ 1216 ADAS_Warning_Flag_13 "Warning Message Flag, Component owner, Supplier align and define for this signal";
CM_ SG_ 1216 ADAS_Warning_Flag_14 "I-ECU has BSD function fault : speed /gear loss";
CM_ SG_ 1216 ADAS_Warning_Flag_15 "I-ECU has RCTA function fault.speed /gear loss";
CM_ SG_ 1216 ADAS_Warning_Flag_16 "Warning Message Flag, Component owner, Supplier align and define for this signal";
CM_ SG_ 1216 ADAS_Warning_Flag_17 "I-ECU has DOW function fault: speed /gear loss";
CM_ SG_ 1216 ADAS_Warning_Flag_18 "Warning Message Flag, Component owner, Supplier align and define for this signal";
CM_ SG_ 1216 ADAS_Warning_Flag_19 "Warning Message Flag, Component owner, Supplier align and define for this signal";
CM_ SG_ 1216 ADAS_Warning_Flag_20 "Warning Message Flag, Component owner, Supplier align and define for this signal";
CM_ SG_ 1216 ADAS_Warning_Flag_21 "LeftCornerRadaar Install Faulty";
CM_ SG_ 1216 ADAS_Warning_Flag_22 "RightCornerRadaar Install Faulty";
CM_ SG_ 1216 ADAS_Warning_Flag_23 "LeftCornerRadaar Calib Faulty";
CM_ SG_ 1216 ADAS_Warning_Flag_24 "RightCornerRadaar Calib Faulty";
CM_ SG_ 1216 ADAS_Warning_Flag_25 "Warning Message Flag, Component owner, Supplier align and define for this signal";
CM_ SG_ 1216 ADAS_Warning_Flag_26 "Warning Message Flag, Component owner, Supplier align and define for this signal";
CM_ SG_ 1216 ADAS_Warning_Flag_27 "Warning Message Flag, Component owner, Supplier align and define for this signal";
CM_ SG_ 1216 ADAS_Warning_Flag_28 "Warning Message Flag, Component owner, Supplier align and define for this signal";
CM_ SG_ 1216 ADAS_Reserved_signal3 "Warning Message Flag, Component owner, Supplier align and define for this signal";
CM_ SG_ 1216 ADAS_Reserved_signal4 "Warning Message Flag, Component owner, Supplier align and define for this signal";
CM_ SG_ 1216 ADAS_Reserved_signal5 "Warning Message Flag, Component owner, Supplier align and define for this signal";
CM_ SG_ 851 Checksum_0x353 "Checksum";
CM_ SG_ 851 Rolling_Counter_0x353 "Rolling_Counter";
CM_ SG_ 851 ADAS_RadarRight_Cal_Status "BSD right calibration Status";
CM_ SG_ 851 ADAS_RadarLeft_Cal_Status "BSD left calibration Status";
CM_ SG_ 851 ADAS_RadarRight_DynaCal_Status "BSD right dynamic calibration status";
CM_ SG_ 851 ADAS_RadarLeft_DynaCal_Status "BSD left dynamic calibration status";
CM_ SG_ 851 ADAS_MasterSRR_check "Master Corner radar Check";
CM_ SG_ 851 ADAS_SlaveSRR_check "Slave Corner radar Check";
CM_ SG_ 851 ADAS_CalSensorMasterProgress "Master(Left) radar calibration progress when get in";
CM_ SG_ 851 ADAS_CalSensorSlaverProgress "Slaver(Right) radar calibration progress when get in";
CM_ SG_ 851 ADAS_Cal_LeftInstallDeviation "left radar install angle deviation  from auto calibration";
CM_ SG_ 851 ADAS_Cal_RightInstallDeviation "right radar install angle deviation  from auto calibration";
CM_ SG_ 133 Checksum_0x85 "Checksum";
CM_ SG_ 133 Rolling_Counter_0x85 "Rolling Counter";
CM_ SG_ 133 ACM_Crash_Sts "Crash status";
CM_ SG_ 133 ACM_Airbag_Deployment_Status "Signal to indicate if airbag/pretensioner/pyrofuse is deployed";
CM_ SG_ 133 ACM_Crash_Intensity "Indicate crash intensity level";
CM_ SG_ 133 ACM_Front_Crash "Output information for direction of crash";
CM_ SG_ 133 ACM_DriverSide_Crash "Output information for direction of crash";
CM_ SG_ 133 ACM_PassSide_Crash "Output information for direction of crash";
CM_ SG_ 133 ACM_Rear_Crash "Output information for direction of crash";
CM_ SG_ 133 ACM_Rollover_Crash "Output information for direction of crash";
CM_ SG_ 897 Checksum_0x381 "Checksum";
CM_ SG_ 897 Rolling_Counter_0x381 "Rolling Counter";
CM_ SG_ 897 ACM_Seat_Occupancy_Passenger "Signal to indicate status of occupancy";
CM_ SG_ 897 ACM_Seat_Occupancy_2nd_Row_Dri_r "Signal to indicate status of occupancy";
CM_ SG_ 897 ACM_Seat_Occupancy_2nd_Row_Pas_r "Signal to indicate status of occupancy";
CM_ SG_ 897 ACM_Seat_Occupancy_2nd_Row_Mid_r "Signal to indicate status of occupancy";
CM_ SG_ 897 ACM_Seat_Belt_Status_Passenger "Seatbelt status for seatbelt reminder function";
CM_ SG_ 897 ACM_Seat_Belt_Status_Driver "Seatbelt status for seatbelt reminder function";
CM_ SG_ 897 ACM_Seat_Belt_Status_2nd_Row_Dri "Seatbelt status for seatbelt reminder function";
CM_ SG_ 897 ACM_Seat_Belt_Status_2nd_Row_Mid "Seatbelt status for seatbelt reminder function";
CM_ SG_ 897 ACM_Seat_Belt_Status_2nd_Row_Pas "Seatbelt status for seatbelt reminder function";
CM_ SG_ 897 ACM_Seat_Belt_Status_3rd_Row_Dri "Seatbelt status for seatbelt reminder function";
CM_ SG_ 897 ACM_Seat_Belt_Status_3rd_Row_Pas "Seatbelt status for seatbelt reminder function";
CM_ SG_ 1160 Checksum_0x488 "Checksum";
CM_ SG_ 1160 Rolling_Counter_0x488 "Rolling Counter";
CM_ SG_ 1160 ACM_Malfunction "ACM Malfunction (trigger airbag warning lamp)";
CM_ SG_ 1160 ACM_Pre_Drive_Check "ACM status after pre-drive check (trigger airbag warning lamp if any failure)";
CM_ SG_ 1160 ACM_in_Plant_Mode "ACM plant mode status (trigger airbag warning lamp)";
CM_ SG_ 1160 ACM_PAB_Suppression "ACM suppress passenger airbag (front AB 1st stage, front AB 2nd stage, knee AB). This is used to trigger PAB indicator in MHU's display.";
CM_ SG_ 1160 ACM_Airbag_Disabled "ACM airbag disabled status due to Algo disabled or Firing disabled due to diagnostic or inert calibration file is flashed (trigger Airbag warning lamp when airbag is disabled)";
CM_ SG_ 1160 ACM_Development_Calibration "ACM calibration file status indicate whether ACM is flashed with calibration file for development purpose only (trigger Airbag warning lamp and chime when ACM is flashed with development calibration file)";
CM_ SG_ 1160 ACM_In_Disposal_Mode "ACM disposal mode status (trigger airbag warning lamp when ACM in disposal mode)";
CM_ SG_ 1160 ACM_Seatbelt_Reminder_Request "ACM request seatbelt reminder (1 signal for whole front and rear seats)";
CM_ SG_ 1160 ACM_SBR_Chime_Req "ACM request chime to MHU for seatbelt reminder front row";
CM_ SG_ 1160 ACM_SBR_Blinking_Req "ACM send blinking request to MHU (trigger blinking of seatbelt reminder lamp)";
BA_DEF_ BO_  "DiagRequest" ENUM  "No","Yes";
BA_DEF_ BO_  "DiagResponse" ENUM  "No","Yes";
BA_DEF_ BO_  "DiagState" ENUM  "No","Yes";
BA_DEF_ BO_  "GenMsgCycleTime" INT 0 65535;
BA_DEF_ BO_  "GenMsgCycleTimeFast" INT 0 65535;
BA_DEF_ BO_  "GenMsgDelayTime" INT 0 65535;
BA_DEF_ BO_  "GenMsgILSupport" ENUM  "No","Yes";
BA_DEF_ BO_  "GenMsgNrOfRepetition" INT 0 65535;
BA_DEF_ BO_  "GenMsgSendType" ENUM  "Cycle","Event","IfActive","CE","CA";
BA_DEF_ BO_  "NmAsrMessage" ENUM  "No","Yes";
BA_DEF_ BO_  "NmMessage" ENUM  "No","Yes";
BA_DEF_ SG_  "GenSigSendType" ENUM  "Cycle","OnWrite","OnWriteWithRepetition","OnChange","OnChangeWithRepetition","IfActive","IfActiveWithRepetition";
BA_DEF_ SG_  "GenSigStartValue" INT 0 2147483647;
BA_DEF_ SG_  "GenSigInvalidValue" INT 0 2147483647;
BA_DEF_ SG_  "GenSigInactiveValue" INT 0 2147483647;
BA_DEF_ BU_  "ILUsed" ENUM  "No","Yes";
BA_DEF_ BU_  "NmAsrCanMsgReducedTime" INT 320 640;
BA_DEF_ BU_  "NmAsrNode" ENUM  "No","Yes";
BA_DEF_  "Baudrate" INT 0 1000000;
BA_DEF_  "BusType" STRING ;
BA_DEF_  "Manufacturer" STRING ;
BA_DEF_  "NmAsrBaseAddress" HEX 0 2047;
BA_DEF_  "NmAsrCanMsgCycleTime" INT 0 65535;
BA_DEF_  "NmAsrMessageCount" INT 1 256;
BA_DEF_  "NmAsrRepeatMessageTime" INT 0 65535;
BA_DEF_  "NmAsrTimeoutTime" INT 0 65535;
BA_DEF_  "NmAsrWaitBusSleepTime" INT 0 65535;
BA_DEF_  "NmType" STRING ;
BA_DEF_ SG_  "SystemSignalLongSymbol" STRING ;
BA_DEF_DEF_  "DiagRequest" "No";
BA_DEF_DEF_  "DiagResponse" "No";
BA_DEF_DEF_  "DiagState" "No";
BA_DEF_DEF_  "GenMsgCycleTime" 0;
BA_DEF_DEF_  "GenMsgCycleTimeFast" 0;
BA_DEF_DEF_  "GenMsgDelayTime" 0;
BA_DEF_DEF_  "GenMsgILSupport" "Yes";
BA_DEF_DEF_  "GenMsgNrOfRepetition" 0;
BA_DEF_DEF_  "GenMsgSendType" "";
BA_DEF_DEF_  "NmAsrMessage" "No";
BA_DEF_DEF_  "NmMessage" "No";
BA_DEF_DEF_  "GenSigSendType" "";
BA_DEF_DEF_  "GenSigStartValue" 0;
BA_DEF_DEF_  "GenSigInvalidValue" 0;
BA_DEF_DEF_  "GenSigInactiveValue" 0;
BA_DEF_DEF_  "ILUsed" "Yes";
BA_DEF_DEF_  "NmAsrCanMsgReducedTime" 320;
BA_DEF_DEF_  "NmAsrNode" "No";
BA_DEF_DEF_  "Baudrate" 500000;
BA_DEF_DEF_  "BusType" "CAN";
BA_DEF_DEF_  "Manufacturer" "Launch";
BA_DEF_DEF_  "NmAsrBaseAddress" 1280;
BA_DEF_DEF_  "NmAsrCanMsgCycleTime" 640;
BA_DEF_DEF_  "NmAsrMessageCount" 128;
BA_DEF_DEF_  "NmAsrRepeatMessageTime" 3200;
BA_DEF_DEF_  "NmAsrTimeoutTime" 2000;
BA_DEF_DEF_  "NmAsrWaitBusSleepTime" 1500;
BA_DEF_DEF_  "NmType" "NmAsr";
BA_DEF_DEF_  "SystemSignalLongSymbol" "";
BA_ "NmAsrNode" BU_ GW 1;
BA_ "NmAsrNode" BU_ MHU 1;
BA_ "NmAsrNode" BU_ IPC 1;
BA_ "NmAsrNode" BU_ CCU 1;
BA_ "GenMsgCycleTime" BO_ 1191 100;
BA_ "GenMsgDelayTime" BO_ 1191 70;
BA_ "GenMsgSendType" BO_ 1191 0;
BA_ "GenMsgCycleTime" BO_ 215 1000;
BA_ "GenMsgSendType" BO_ 215 0;
BA_ "GenMsgCycleTime" BO_ 967 100;
BA_ "GenMsgCycleTimeFast" BO_ 967 50;
BA_ "GenMsgDelayTime" BO_ 967 30;
BA_ "GenMsgNrOfRepetition" BO_ 967 5;
BA_ "GenMsgSendType" BO_ 967 0;
BA_ "GenMsgCycleTime" BO_ 711 100;
BA_ "GenMsgDelayTime" BO_ 711 40;
BA_ "GenMsgSendType" BO_ 711 0;
BA_ "GenMsgCycleTimeFast" BO_ 695 50;
BA_ "GenMsgNrOfRepetition" BO_ 695 5;
BA_ "GenMsgSendType" BO_ 695 1;
BA_ "GenMsgCycleTimeFast" BO_ 679 50;
BA_ "GenMsgNrOfRepetition" BO_ 679 5;
BA_ "GenMsgSendType" BO_ 679 1;
BA_ "GenMsgCycleTimeFast" BO_ 727 20;
BA_ "GenMsgNrOfRepetition" BO_ 727 2;
BA_ "GenMsgSendType" BO_ 727 1;
BA_ "GenMsgCycleTimeFast" BO_ 743 20;
BA_ "GenMsgNrOfRepetition" BO_ 743 2;
BA_ "GenMsgSendType" BO_ 743 1;
BA_ "GenMsgCycleTimeFast" BO_ 759 50;
BA_ "GenMsgNrOfRepetition" BO_ 759 5;
BA_ "GenMsgSendType" BO_ 759 1;
BA_ "GenMsgCycleTimeFast" BO_ 999 50;
BA_ "GenMsgNrOfRepetition" BO_ 999 5;
BA_ "GenMsgSendType" BO_ 999 1;
BA_ "GenMsgCycleTimeFast" BO_ 983 50;
BA_ "GenMsgNrOfRepetition" BO_ 983 5;
BA_ "GenMsgSendType" BO_ 983 1;
BA_ "GenMsgCycleTime" BO_ 503 100;
BA_ "GenMsgDelayTime" BO_ 503 60;
BA_ "GenMsgSendType" BO_ 503 0;
BA_ "GenMsgSendType" BO_ 852 1;
BA_ "GenMsgCycleTimeFast" BO_ 1025 50;
BA_ "GenMsgNrOfRepetition" BO_ 1025 5;
BA_ "GenMsgSendType" BO_ 1025 1;
BA_ "GenMsgCycleTimeFast" BO_ 1026 50;
BA_ "GenMsgNrOfRepetition" BO_ 1026 5;
BA_ "GenMsgSendType" BO_ 1026 1;
BA_ "GenMsgCycleTime" BO_ 1027 100;
BA_ "GenMsgCycleTimeFast" BO_ 1027 20;
BA_ "GenMsgNrOfRepetition" BO_ 1027 5;
BA_ "GenMsgSendType" BO_ 1027 3;
BA_ "GenMsgCycleTime" BO_ 807 100;
BA_ "GenMsgCycleTimeFast" BO_ 807 10;
BA_ "GenMsgDelayTime" BO_ 807 10;
BA_ "GenMsgNrOfRepetition" BO_ 807 5;
BA_ "GenMsgSendType" BO_ 807 3;
BA_ "GenMsgCycleTime" BO_ 1058 100;
BA_ "GenMsgDelayTime" BO_ 1058 20;
BA_ "GenMsgSendType" BO_ 1058 0;
BA_ "GenMsgCycleTimeFast" BO_ 267 20;
BA_ "GenMsgNrOfRepetition" BO_ 267 5;
BA_ "GenMsgSendType" BO_ 267 1;
BA_ "GenMsgCycleTime" BO_ 259 200;
BA_ "GenMsgSendType" BO_ 259 0;
BA_ "GenMsgCycleTimeFast" BO_ 269 20;
BA_ "GenMsgNrOfRepetition" BO_ 269 5;
BA_ "GenMsgSendType" BO_ 269 1;
BA_ "GenMsgCycleTimeFast" BO_ 271 20;
BA_ "GenMsgNrOfRepetition" BO_ 271 5;
BA_ "GenMsgSendType" BO_ 271 1;
BA_ "GenMsgCycleTime" BO_ 1074 100;
BA_ "GenMsgDelayTime" BO_ 1074 50;
BA_ "GenMsgSendType" BO_ 1074 0;
BA_ "GenMsgCycleTime" BO_ 1020 500;
BA_ "GenMsgSendType" BO_ 1020 0;
BA_ "GenMsgCycleTimeFast" BO_ 922 50;
BA_ "GenMsgNrOfRepetition" BO_ 922 5;
BA_ "GenMsgSendType" BO_ 922 1;
BA_ "GenMsgCycleTimeFast" BO_ 923 50;
BA_ "GenMsgNrOfRepetition" BO_ 923 5;
BA_ "GenMsgSendType" BO_ 923 1;
BA_ "GenMsgDelayTime" BO_ 929 10;
BA_ "GenMsgSendType" BO_ 929 1;
BA_ "GenMsgDelayTime" BO_ 930 10;
BA_ "GenMsgSendType" BO_ 930 1;
BA_ "GenMsgDelayTime" BO_ 931 10;
BA_ "GenMsgNrOfRepetition" BO_ 931 3;
BA_ "GenMsgSendType" BO_ 931 1;
BA_ "GenMsgCycleTime" BO_ 1087 1000;
BA_ "GenMsgSendType" BO_ 1087 0;
BA_ "GenMsgCycleTime" BO_ 524 100;
BA_ "GenMsgSendType" BO_ 524 0;
BA_ "GenMsgCycleTime" BO_ 703 50;
BA_ "GenMsgSendType" BO_ 703 0;
BA_ "GenMsgCycleTime" BO_ 719 50;
BA_ "GenMsgSendType" BO_ 719 0;
BA_ "GenMsgCycleTime" BO_ 751 50;
BA_ "GenMsgSendType" BO_ 751 0;
BA_ "GenMsgCycleTimeFast" BO_ 735 50;
BA_ "GenMsgNrOfRepetition" BO_ 735 5;
BA_ "GenMsgSendType" BO_ 735 1;
BA_ "GenMsgCycleTime" BO_ 975 50;
BA_ "GenMsgSendType" BO_ 975 0;
BA_ "GenMsgCycleTime" BO_ 770 200;
BA_ "GenMsgSendType" BO_ 770 0;
BA_ "GenMsgCycleTime" BO_ 811 50;
BA_ "GenMsgSendType" BO_ 811 0;
BA_ "GenMsgCycleTime" BO_ 1037 50;
BA_ "GenMsgSendType" BO_ 1037 0;
BA_ "GenMsgCycleTime" BO_ 296 50;
BA_ "GenMsgSendType" BO_ 296 0;
BA_ "GenMsgCycleTime" BO_ 307 50;
BA_ "GenMsgSendType" BO_ 307 0;
BA_ "GenMsgCycleTime" BO_ 850 50;
BA_ "GenMsgSendType" BO_ 850 0;
BA_ "GenMsgCycleTime" BO_ 1216 1000;
BA_ "GenMsgSendType" BO_ 1216 0;
BA_ "GenMsgCycleTime" BO_ 851 50;
BA_ "GenMsgSendType" BO_ 851 0;
BA_ "GenMsgCycleTime" BO_ 133 20;
BA_ "GenMsgSendType" BO_ 133 0;
BA_ "GenMsgCycleTime" BO_ 897 200;
BA_ "GenMsgSendType" BO_ 897 0;
BA_ "GenMsgCycleTime" BO_ 1160 1000;
BA_ "GenMsgSendType" BO_ 1160 0;
BA_ "GenSigSendType" SG_ 1191 MHU_BTPairing 0;
BA_ "GenSigSendType" SG_ 1191 MHU_MaintenanceEvent 0;
BA_ "GenSigSendType" SG_ 1191 MHU_Arrow 0;
BA_ "GenSigInvalidValue" SG_ 215 MHU_SET_Second 63;
BA_ "GenSigSendType" SG_ 215 MHU_SET_Second 0;
BA_ "GenSigInvalidValue" SG_ 215 MHU_SET_Min 63;
BA_ "GenSigSendType" SG_ 215 MHU_SET_Min 0;
BA_ "GenSigInvalidValue" SG_ 215 MHU_SET_Hour 31;
BA_ "GenSigSendType" SG_ 215 MHU_SET_Hour 0;
BA_ "GenSigStartValue" SG_ 215 MHU_SET_Day 1;
BA_ "GenSigSendType" SG_ 215 MHU_SET_Day 0;
BA_ "GenSigStartValue" SG_ 215 MHU_SET_Month 1;
BA_ "GenSigInvalidValue" SG_ 215 MHU_SET_Month 15;
BA_ "GenSigSendType" SG_ 215 MHU_SET_Month 0;
BA_ "GenSigInvalidValue" SG_ 215 MHU_SET_Year 255;
BA_ "GenSigSendType" SG_ 215 MHU_SET_Year 0;
BA_ "GenSigStartValue" SG_ 967 MHU_VehsSpd_Warn 12000;
BA_ "GenSigInvalidValue" SG_ 967 MHU_VehsSpd_Warn 32767;
BA_ "GenSigSendType" SG_ 967 MHU_VehsSpd_Warn 2;
BA_ "GenSigInvalidValue" SG_ 967 MHU_SET_Volume 255;
BA_ "GenSigSendType" SG_ 967 MHU_SET_Volume 2;
BA_ "GenSigStartValue" SG_ 967 MHU_St_DimmingIPC 10;
BA_ "GenSigInvalidValue" SG_ 967 MHU_St_DimmingIPC 15;
BA_ "GenSigSendType" SG_ 967 MHU_St_DimmingIPC 2;
BA_ "GenSigSendType" SG_ 711 MHU_FavoriteFlag 0;
BA_ "GenSigInvalidValue" SG_ 711 MHU_AMRadioFrequanceValue 16383;
BA_ "GenSigSendType" SG_ 711 MHU_AMRadioFrequanceValue 0;
BA_ "GenSigInvalidValue" SG_ 711 MHU_FMRadioFrequanceValue 1023;
BA_ "GenSigSendType" SG_ 711 MHU_FMRadioFrequanceValue 0;
BA_ "GenSigSendType" SG_ 711 MHU_SourceStationMode_Reserved 0;
BA_ "GenSigSendType" SG_ 711 MHU_Route_Reserved 0;
BA_ "GenSigSendType" SG_ 711 MHU_Distance 0;
BA_ "GenSigInvalidValue" SG_ 695 MHU_MediaType 15;
BA_ "GenSigSendType" SG_ 695 MHU_MediaType 2;
BA_ "GenSigInvalidValue" SG_ 695 MHU_MediaStatus_Reserved 3;
BA_ "GenSigSendType" SG_ 695 MHU_MediaStatus_Reserved 2;
BA_ "GenSigSendType" SG_ 695 MHU_MediaProgress_Reserved 2;
BA_ "GenSigSendType" SG_ 695 MHU_MediaDuration_Reserved 2;
BA_ "GenSigStartValue" SG_ 695 MHU_PhoneStatus 1;
BA_ "GenSigInvalidValue" SG_ 695 MHU_PhoneStatus 15;
BA_ "GenSigSendType" SG_ 695 MHU_PhoneStatus 2;
BA_ "GenSigSendType" SG_ 695 MHU_PhoneTime 2;
BA_ "GenSigInvalidValue" SG_ 695 MHU_NaviType 3;
BA_ "GenSigSendType" SG_ 695 MHU_NaviType 2;
BA_ "GenSigSendType" SG_ 695 MHU_NaviStatus 2;
BA_ "GenSigSendType" SG_ 695 MHU_Destination_Reachsts 2;
BA_ "GenSigSendType" SG_ 679 MHU_Destination 2;
BA_ "GenSigSendType" SG_ 679 MHU_DestinationInfo1_Num 2;
BA_ "GenSigSendType" SG_ 679 MHU_DestinationInfo1_Ind 2;
BA_ "GenSigSendType" SG_ 727 MHU_MediaInfo_Num 2;
BA_ "GenSigSendType" SG_ 727 MHU_MediaInfo_Ind 2;
BA_ "GenSigSendType" SG_ 727 MHU_MediaInfo_Content 2;
BA_ "GenSigSendType" SG_ 743 MHU_PhoneInfo_Num 2;
BA_ "GenSigSendType" SG_ 743 MHU_PhoneInfo_Ind 2;
BA_ "GenSigSendType" SG_ 743 MHU_PhoneInfo_Contact 2;
BA_ "GenSigSendType" SG_ 759 MHU_CallLog_Num 2;
BA_ "GenSigSendType" SG_ 759 MHU_CallLog_Ind 2;
BA_ "GenSigSendType" SG_ 759 MHU_CallLog 2;
BA_ "GenSigSendType" SG_ 999 MHU_PhoneType 2;
BA_ "GenSigSendType" SG_ 983 MHU_PhoneName 2;
BA_ "GenSigSendType" SG_ 503 MHU_Compass 0;
BA_ "GenSigSendType" SG_ 503 MHU_Roundabout 0;
BA_ "GenSigSendType" SG_ 503 MHU_USBConnect 0;
BA_ "GenSigSendType" SG_ 503 MHU_VolumeStatus 0;
BA_ "GenSigSendType" SG_ 503 MHU_MEDIA_MUTE 0;
BA_ "GenSigSendType" SG_ 503 MHU_PollutionReq 0;
BA_ "GenSigSendType" SG_ 503 MHU_NextTurnDistance 0;
BA_ "GenSigStartValue" SG_ 852 MHU_BSD_On 2;
BA_ "GenSigInvalidValue" SG_ 852 MHU_BSD_On 3;
BA_ "GenSigSendType" SG_ 852 MHU_BSD_On 1;
BA_ "GenSigStartValue" SG_ 852 MHU_BSD_sens_Reserved 3;
BA_ "GenSigInvalidValue" SG_ 852 MHU_BSD_sens_Reserved 7;
BA_ "GenSigSendType" SG_ 852 MHU_BSD_sens_Reserved 1;
BA_ "GenSigStartValue" SG_ 852 MHU_BSD_AudWarning 2;
BA_ "GenSigInvalidValue" SG_ 852 MHU_BSD_AudWarning 3;
BA_ "GenSigSendType" SG_ 852 MHU_BSD_AudWarning 1;
BA_ "GenSigStartValue" SG_ 852 MHU_RCTA_On 2;
BA_ "GenSigInvalidValue" SG_ 852 MHU_RCTA_On 3;
BA_ "GenSigSendType" SG_ 852 MHU_RCTA_On 1;
BA_ "GenSigStartValue" SG_ 852 MHU_RCTA_sens_Reserved 3;
BA_ "GenSigInvalidValue" SG_ 852 MHU_RCTA_sens_Reserved 7;
BA_ "GenSigSendType" SG_ 852 MHU_RCTA_sens_Reserved 1;
BA_ "GenSigStartValue" SG_ 852 MHU_PA_On 2;
BA_ "GenSigInvalidValue" SG_ 852 MHU_PA_On 3;
BA_ "GenSigSendType" SG_ 852 MHU_PA_On 1;
BA_ "GenSigStartValue" SG_ 852 MHU_DOW_Mode 2;
BA_ "GenSigInvalidValue" SG_ 852 MHU_DOW_Mode 3;
BA_ "GenSigSendType" SG_ 852 MHU_DOW_Mode 1;
BA_ "GenSigStartValue" SG_ 852 MHU_DOW_sens_Reserved 3;
BA_ "GenSigInvalidValue" SG_ 852 MHU_DOW_sens_Reserved 7;
BA_ "GenSigSendType" SG_ 852 MHU_DOW_sens_Reserved 1;
BA_ "GenSigStartValue" SG_ 852 MHU_DOW_AudWarning 2;
BA_ "GenSigInvalidValue" SG_ 852 MHU_DOW_AudWarning 3;
BA_ "GenSigSendType" SG_ 852 MHU_DOW_AudWarning 1;
BA_ "GenSigStartValue" SG_ 1025 MHU_SET_DoorSpeedLock 6;
BA_ "GenSigSendType" SG_ 1025 MHU_SET_DoorSpeedLock 1;
BA_ "GenSigStartValue" SG_ 1025 MHU_SET_RemoteDoorUnlock_reserve 2;
BA_ "GenSigSendType" SG_ 1025 MHU_SET_RemoteDoorUnlock_reserve 1;
BA_ "SystemSignalLongSymbol" SG_ 1025 MHU_SET_RemoteDoorUnlock_reserve "MHU_SET_RemoteDoorUnlock_reserved";
BA_ "GenSigStartValue" SG_ 1025 MHU_SET_RemoteLockFeedback 4;
BA_ "GenSigSendType" SG_ 1025 MHU_SET_RemoteLockFeedback 1;
BA_ "GenSigStartValue" SG_ 1025 MHU_SET_AutoUnlockDoor 2;
BA_ "GenSigSendType" SG_ 1025 MHU_SET_AutoUnlockDoor 1;
BA_ "GenSigStartValue" SG_ 1025 MHU_SET_MirrorAuto_reserved 1;
BA_ "GenSigSendType" SG_ 1025 MHU_SET_MirrorAuto_reserved 1;
BA_ "GenSigStartValue" SG_ 1025 MHU_Anti_theftAlarmSet 4;
BA_ "GenSigSendType" SG_ 1025 MHU_Anti_theftAlarmSet 2;
BA_ "GenSigSendType" SG_ 1025 MHU_TriggerReadKey 2;
BA_ "GenSigStartValue" SG_ 1026 MHU_Heatrearglass_Set 2;
BA_ "GenSigInvalidValue" SG_ 1026 MHU_Heatrearglass_Set 3;
BA_ "GenSigSendType" SG_ 1026 MHU_Heatrearglass_Set 2;
BA_ "GenSigStartValue" SG_ 1026 MHU_SET_DayTimeRunningLight_rese 1;
BA_ "GenSigSendType" SG_ 1026 MHU_SET_DayTimeRunningLight_rese 2;
BA_ "SystemSignalLongSymbol" SG_ 1026 MHU_SET_DayTimeRunningLight_rese "MHU_SET_DayTimeRunningLight_reserved";
BA_ "GenSigSendType" SG_ 1026 MHU_SET_FollowMeHomeTime 2;
BA_ "GenSigSendType" SG_ 1027 Checksum_0x403 0;
BA_ "GenSigInvalidValue" SG_ 1027 Rolling_Counter_0x403 15;
BA_ "GenSigSendType" SG_ 1027 Rolling_Counter_0x403 0;
BA_ "GenSigStartValue" SG_ 1027 MHU_SET_TCS_OnOff 2;
BA_ "GenSigInvalidValue" SG_ 1027 MHU_SET_TCS_OnOff 3;
BA_ "GenSigSendType" SG_ 1027 MHU_SET_TCS_OnOff 2;
BA_ "GenSigSendType" SG_ 1027 MHU_SET_DrivingModeSwitch 2;
BA_ "GenSigStartValue" SG_ 1027 MHU_SET_RegenLevel 3;
BA_ "GenSigSendType" SG_ 1027 MHU_SET_RegenLevel 2;
BA_ "GenSigStartValue" SG_ 1027 MHU_VCU_CreepDisable_stt 2;
BA_ "GenSigInvalidValue" SG_ 1027 MHU_VCU_CreepDisable_stt 3;
BA_ "GenSigSendType" SG_ 1027 MHU_VCU_CreepDisable_stt 2;
BA_ "GenSigStartValue" SG_ 1027 MHU_ChargeSetTargetSOC 100;
BA_ "GenSigInvalidValue" SG_ 1027 MHU_ChargeSetTargetSOC 127;
BA_ "GenSigSendType" SG_ 1027 MHU_ChargeSetTargetSOC 2;
BA_ "GenSigInvalidValue" SG_ 1027 MHU_HVACTurnON 3;
BA_ "GenSigSendType" SG_ 1027 MHU_HVACTurnON 2;
BA_ "GenSigStartValue" SG_ 1027 MHU_ChargeScheduleSet 2;
BA_ "GenSigSendType" SG_ 1027 MHU_ChargeScheduleSet 2;
BA_ "GenSigStartValue" SG_ 1027 MHU_ChargingRequest 3;
BA_ "GenSigSendType" SG_ 1027 MHU_ChargingRequest 2;
BA_ "GenSigInactiveValue" SG_ 1027 MHU_ValetMode_Activation 255;
BA_ "GenSigInvalidValue" SG_ 1027 MHU_ValetMode_Activation 254;
BA_ "GenSigSendType" SG_ 1027 MHU_ValetMode_Activation 2;
BA_ "GenSigInactiveValue" SG_ 1027 MHU_ValetMode_MaxSpeed 255;
BA_ "GenSigInvalidValue" SG_ 1027 MHU_ValetMode_MaxSpeed 2;
BA_ "GenSigSendType" SG_ 1027 MHU_ValetMode_MaxSpeed 2;
BA_ "GenSigInvalidValue" SG_ 807 MHU_CCU_AC_Button 3;
BA_ "GenSigSendType" SG_ 807 MHU_CCU_AC_Button 2;
BA_ "GenSigInvalidValue" SG_ 807 MHU_REC_Button 3;
BA_ "GenSigSendType" SG_ 807 MHU_REC_Button 2;
BA_ "GenSigInvalidValue" SG_ 807 MHU_SetBlowMode 7;
BA_ "GenSigSendType" SG_ 807 MHU_SetBlowMode 2;
BA_ "GenSigInvalidValue" SG_ 807 MHU_BlowerLevelSetting 31;
BA_ "GenSigSendType" SG_ 807 MHU_BlowerLevelSetting 2;
BA_ "GenSigInvalidValue" SG_ 807 MHU_SetDriverTemp 63;
BA_ "GenSigSendType" SG_ 807 MHU_SetDriverTemp 2;
BA_ "GenSigInvalidValue" SG_ 807 MHU_ACM_Reserved 3;
BA_ "GenSigSendType" SG_ 807 MHU_ACM_Reserved 2;
BA_ "GenSigInvalidValue" SG_ 807 MHU_FrontDefrostReq_Reserved 3;
BA_ "GenSigSendType" SG_ 807 MHU_FrontDefrostReq_Reserved 2;
BA_ "GenSigSendType" SG_ 1058 Checksum_0x422 0;
BA_ "GenSigInvalidValue" SG_ 1058 Rolling_Counter_0x422 15;
BA_ "GenSigSendType" SG_ 1058 Rolling_Counter_0x422 0;
BA_ "GenSigInvalidValue" SG_ 1058 MHU_STAT_DateTimeFormat 3;
BA_ "GenSigSendType" SG_ 1058 MHU_STAT_DateTimeFormat 0;
BA_ "GenSigInvalidValue" SG_ 1058 MHU_DISPLAY_STATUS 3;
BA_ "GenSigSendType" SG_ 1058 MHU_DISPLAY_STATUS 0;
BA_ "GenSigStartValue" SG_ 1058 MHU_STAT_Language 31;
BA_ "GenSigInvalidValue" SG_ 1058 MHU_STAT_Language 31;
BA_ "GenSigSendType" SG_ 1058 MHU_STAT_Language 0;
BA_ "GenSigInvalidValue" SG_ 267 TBOX_STAT_TerminalReq 7;
BA_ "GenSigSendType" SG_ 267 TBOX_STAT_TerminalReq 2;
BA_ "GenSigSendType" SG_ 267 TBOX_AuthCode_0x10B 1;
BA_ "GenSigSendType" SG_ 259 Q_Discharge 0;
BA_ "GenSigSendType" SG_ 259 Q_Charge 0;
BA_ "GenSigSendType" SG_ 259 RQ_DCDC_U 0;
BA_ "GenSigSendType" SG_ 259 REQ_ConsumerControlAudioVolumeCo 0;
BA_ "GenSigSendType" SG_ 259 REQ_CCU_PTC_Limitation 0;
BA_ "GenSigStartValue" SG_ 269 MHU_BCM_reqTrunk 2;
BA_ "GenSigSendType" SG_ 269 MHU_BCM_reqTrunk 2;
BA_ "GenSigStartValue" SG_ 269 MHU_BCM_RemoteDoorCtrl 2;
BA_ "GenSigSendType" SG_ 269 MHU_BCM_RemoteDoorCtrl 2;
BA_ "GenSigInvalidValue" SG_ 269 MHU_APM_ReqWindow 7;
BA_ "GenSigSendType" SG_ 269 MHU_APM_ReqWindow 2;
BA_ "GenSigSendType" SG_ 269 TBOX_AuthCode_0x10D 1;
BA_ "GenSigStartValue" SG_ 271 MHU_SetHighBeam 2;
BA_ "GenSigInvalidValue" SG_ 271 MHU_SetHighBeam 3;
BA_ "GenSigSendType" SG_ 271 MHU_SetHighBeam 2;
BA_ "GenSigStartValue" SG_ 271 MHU_SetHornOnOff 2;
BA_ "GenSigInvalidValue" SG_ 271 MHU_SetHornOnOff 3;
BA_ "GenSigSendType" SG_ 271 MHU_SetHornOnOff 2;
BA_ "GenSigStartValue" SG_ 271 MHU_SetLowBeam 2;
BA_ "GenSigInvalidValue" SG_ 271 MHU_SetLowBeam 3;
BA_ "GenSigSendType" SG_ 271 MHU_SetLowBeam 2;
BA_ "GenSigSendType" SG_ 271 TBOX_AuthCode_0x10F 1;
BA_ "GenSigSendType" SG_ 1074 Checksum_0x432 0;
BA_ "GenSigInvalidValue" SG_ 1074 Rolling_Counter_0x432 15;
BA_ "GenSigSendType" SG_ 1074 Rolling_Counter_0x432 0;
BA_ "GenSigSendType" SG_ 1074 MHU_FOTA_State 0;
BA_ "GenSigSendType" SG_ 1074 MHU_FOTA_Error_Code 0;
BA_ "GenSigSendType" SG_ 1020 XGW_FOTA_StateConfirm 0;
BA_ "GenSigStartValue" SG_ 1020 XGW_FOTA_Error_Code 63;
BA_ "GenSigInvalidValue" SG_ 1020 XGW_FOTA_Error_Code 255;
BA_ "GenSigSendType" SG_ 1020 XGW_FOTA_Error_Code 0;
BA_ "GenSigSendType" SG_ 1020 CRC_XGW_FOTA_StsConfirm 0;
BA_ "GenSigSendType" SG_ 1020 ALIV_XGW_FOTA_StsConfirm 0;
BA_ "GenSigSendType" SG_ 922 MHU_Immo_Byte_0 1;
BA_ "GenSigSendType" SG_ 922 MHU_Immo_Byte_1 1;
BA_ "GenSigSendType" SG_ 922 MHU_Immo_Byte_2 1;
BA_ "GenSigSendType" SG_ 922 MHU_Immo_Byte_3 1;
BA_ "GenSigSendType" SG_ 922 MHU_Immo_Byte_4 1;
BA_ "GenSigSendType" SG_ 922 MHU_Immo_Byte_5 1;
BA_ "GenSigSendType" SG_ 922 MHU_Immo_Byte_6 1;
BA_ "GenSigSendType" SG_ 922 MHU_Immo_Byte_7 1;
BA_ "GenSigSendType" SG_ 923 BCM_Immo_MHU_Byte_0 1;
BA_ "GenSigSendType" SG_ 923 BCM_Immo_MHU_Byte_1 1;
BA_ "GenSigSendType" SG_ 923 BCM_Immo_MHU_Byte_2 1;
BA_ "GenSigSendType" SG_ 923 BCM_Immo_MHU_Byte_3 1;
BA_ "GenSigSendType" SG_ 923 BCM_Immo_MHU_Byte_4 1;
BA_ "GenSigSendType" SG_ 923 BCM_Immo_MHU_Byte_5 1;
BA_ "GenSigSendType" SG_ 923 BCM_Immo_MHU_Byte_6 1;
BA_ "GenSigSendType" SG_ 923 BCM_Immo_MHU_Byte_7 1;
BA_ "GenSigSendType" SG_ 929 BMS_MHU_Rand_Num_Byte_0 1;
BA_ "GenSigSendType" SG_ 929 BMS_MHU_Rand_Num_Byte_1 1;
BA_ "GenSigSendType" SG_ 929 BMS_MHU_Rand_Num_Byte_2 1;
BA_ "GenSigSendType" SG_ 929 BMS_MHU_Rand_Num_Byte_3 1;
BA_ "GenSigSendType" SG_ 929 BMS_MHU_Rand_Num_Byte_4 1;
BA_ "GenSigSendType" SG_ 929 BMS_MHU_Rand_Num_Byte_5 1;
BA_ "GenSigSendType" SG_ 929 BMS_MHU_Rand_Num_Byte_6 1;
BA_ "GenSigSendType" SG_ 929 BMS_MHU_Rand_Num_Byte_7 1;
BA_ "GenSigSendType" SG_ 930 MHU_BMS_Enc_Result_Byte_0 1;
BA_ "GenSigSendType" SG_ 930 MHU_BMS_Enc_Result_Byte_1 1;
BA_ "GenSigSendType" SG_ 930 MHU_BMS_Enc_Result_Byte_2 1;
BA_ "GenSigSendType" SG_ 930 MHU_BMS_Enc_Result_Byte_3 1;
BA_ "GenSigSendType" SG_ 930 MHU_BMS_Enc_Result_Byte_4 1;
BA_ "GenSigSendType" SG_ 930 MHU_BMS_Enc_Result_Byte_5 1;
BA_ "GenSigSendType" SG_ 930 MHU_BMS_Enc_Result_Byte_6 1;
BA_ "GenSigSendType" SG_ 930 MHU_BMS_Enc_Result_Byte_7 1;
BA_ "GenSigSendType" SG_ 931 BMS_MHU_Auth_Sts 1;
BA_ "GenSigInvalidValue" SG_ 1087 IPC_Sec 63;
BA_ "GenSigSendType" SG_ 1087 IPC_Sec 0;
BA_ "GenSigInvalidValue" SG_ 1087 IPC_Min 63;
BA_ "GenSigSendType" SG_ 1087 IPC_Min 0;
BA_ "GenSigInvalidValue" SG_ 1087 IPC_Hour 31;
BA_ "GenSigSendType" SG_ 1087 IPC_Hour 0;
BA_ "GenSigStartValue" SG_ 1087 IPC_Day 1;
BA_ "GenSigInvalidValue" SG_ 1087 IPC_Day 31;
BA_ "GenSigSendType" SG_ 1087 IPC_Day 0;
BA_ "GenSigStartValue" SG_ 1087 IPC_Month 1;
BA_ "GenSigInvalidValue" SG_ 1087 IPC_Month 15;
BA_ "GenSigSendType" SG_ 1087 IPC_Month 0;
BA_ "GenSigInvalidValue" SG_ 1087 IPC_Year 255;
BA_ "GenSigSendType" SG_ 1087 IPC_Year 0;
BA_ "GenSigSendType" SG_ 1087 IPC_SelfCheckStatus 0;
BA_ "GenSigSendType" SG_ 524 Checksum_0x20C 0;
BA_ "GenSigInvalidValue" SG_ 524 Rolling_Counter_0x20C 15;
BA_ "GenSigSendType" SG_ 524 Rolling_Counter_0x20C 0;
BA_ "GenSigInvalidValue" SG_ 524 IPC_ODO 1048575;
BA_ "GenSigSendType" SG_ 524 IPC_ODO 0;
BA_ "GenSigInvalidValue" SG_ 703 IPC_TripA 65535;
BA_ "GenSigSendType" SG_ 703 IPC_TripA 0;
BA_ "GenSigInvalidValue" SG_ 703 IPC_AverageSpeedTripA 4095;
BA_ "GenSigSendType" SG_ 703 IPC_AverageSpeedTripA 0;
BA_ "GenSigInvalidValue" SG_ 703 IPC_AverageConsumptionTripA 1023;
BA_ "GenSigSendType" SG_ 703 IPC_AverageConsumptionTripA 0;
BA_ "GenSigInvalidValue" SG_ 703 IPC_ParkBrakeSts 3;
BA_ "GenSigSendType" SG_ 703 IPC_ParkBrakeSts 0;
BA_ "GenSigInvalidValue" SG_ 703 IPC_VehSpd 32767;
BA_ "GenSigSendType" SG_ 703 IPC_VehSpd 0;
BA_ "GenSigInvalidValue" SG_ 719 IPC_TripB 65535;
BA_ "GenSigSendType" SG_ 719 IPC_TripB 0;
BA_ "GenSigInvalidValue" SG_ 719 IPC_AverageSpeedTripB 4095;
BA_ "GenSigSendType" SG_ 719 IPC_AverageSpeedTripB 0;
BA_ "GenSigInvalidValue" SG_ 719 IPC_AverageConsumptionTripB 1023;
BA_ "GenSigSendType" SG_ 719 IPC_AverageConsumptionTripB 0;
BA_ "GenSigInvalidValue" SG_ 751 IPC_TripAuto 65535;
BA_ "GenSigSendType" SG_ 751 IPC_TripAuto 0;
BA_ "GenSigInvalidValue" SG_ 751 IPC_AverageSpeedTripAuto 4095;
BA_ "GenSigSendType" SG_ 751 IPC_AverageSpeedTripAuto 0;
BA_ "GenSigInvalidValue" SG_ 751 IPC_AverageConsumptionTripAuto 1023;
BA_ "GenSigSendType" SG_ 751 IPC_AverageConsumptionTripAuto 0;
BA_ "GenSigSendType" SG_ 735 IPC_TireLearningReq_reserved 4;
BA_ "GenSigSendType" SG_ 735 IPC_TireResetReq 4;
BA_ "GenSigStartValue" SG_ 975 IPC_DimmingIPCLevel 10;
BA_ "GenSigInvalidValue" SG_ 975 IPC_DimmingIPCLevel 15;
BA_ "GenSigSendType" SG_ 975 IPC_DimmingIPCLevel 0;
BA_ "GenSigSendType" SG_ 770 IPC_VOD_Block 0;
BA_ "GenSigSendType" SG_ 770 IPC_VOD_UpdateFlag 0;
BA_ "GenSigStartValue" SG_ 770 IPC_VOD_Byte1 255;
BA_ "GenSigSendType" SG_ 770 IPC_VOD_Byte1 0;
BA_ "GenSigStartValue" SG_ 770 IPC_VOD_Byte2 255;
BA_ "GenSigSendType" SG_ 770 IPC_VOD_Byte2 0;
BA_ "GenSigStartValue" SG_ 770 IPC_VOD_Byte3 255;
BA_ "GenSigSendType" SG_ 770 IPC_VOD_Byte3 0;
BA_ "GenSigStartValue" SG_ 770 IPC_VOD_Byte4 255;
BA_ "GenSigSendType" SG_ 770 IPC_VOD_Byte4 0;
BA_ "GenSigStartValue" SG_ 770 IPC_VOD_Byte5 255;
BA_ "GenSigSendType" SG_ 770 IPC_VOD_Byte5 0;
BA_ "GenSigStartValue" SG_ 770 IPC_VOD_Byte6 255;
BA_ "GenSigSendType" SG_ 770 IPC_VOD_Byte6 0;
BA_ "GenSigStartValue" SG_ 770 IPC_VOD_Byte7 255;
BA_ "GenSigSendType" SG_ 770 IPC_VOD_Byte7 0;
BA_ "GenSigStartValue" SG_ 811 CCU_TemperatureGearSts 7;
BA_ "GenSigInvalidValue" SG_ 811 CCU_TemperatureGearSts 63;
BA_ "GenSigSendType" SG_ 811 CCU_TemperatureGearSts 0;
BA_ "GenSigStartValue" SG_ 811 CCU_BlowMode_Sts 2;
BA_ "GenSigInvalidValue" SG_ 811 CCU_BlowMode_Sts 7;
BA_ "GenSigSendType" SG_ 811 CCU_BlowMode_Sts 0;
BA_ "GenSigSendType" SG_ 811 CCU_Circulation_Sts 0;
BA_ "GenSigInvalidValue" SG_ 811 CCU_AC_Req 3;
BA_ "GenSigSendType" SG_ 811 CCU_AC_Req 0;
BA_ "GenSigSendType" SG_ 811 CCU_AC_Sts 0;
BA_ "GenSigStartValue" SG_ 811 CCU_BlowerLevelSts 1;
BA_ "GenSigSendType" SG_ 811 CCU_BlowerLevelSts 0;
BA_ "GenSigSendType" SG_ 811 CCU_FrontDefrostSts 0;
BA_ "GenSigInvalidValue" SG_ 811 CCU_PTC_Req 3;
BA_ "GenSigSendType" SG_ 811 CCU_PTC_Req 0;
BA_ "GenSigInvalidValue" SG_ 811 CCU_PTC_Temperature 1023;
BA_ "GenSigSendType" SG_ 811 CCU_PTC_Temperature 0;
BA_ "GenSigInvalidValue" SG_ 811 CCU_CompSpdMEAS_Comp 8191;
BA_ "GenSigSendType" SG_ 811 CCU_CompSpdMEAS_Comp 0;
BA_ "GenSigSendType" SG_ 811 CCU_PollutionSts 0;
BA_ "GenSigStartValue" SG_ 811 CCU_ExternalTemperature 255;
BA_ "GenSigInvalidValue" SG_ 811 CCU_ExternalTemperature 255;
BA_ "GenSigSendType" SG_ 811 CCU_ExternalTemperature 0;
BA_ "GenSigStartValue" SG_ 811 CCU_evaporator_Temperature 10;
BA_ "GenSigInvalidValue" SG_ 811 CCU_evaporator_Temperature 31;
BA_ "GenSigSendType" SG_ 811 CCU_evaporator_Temperature 0;
BA_ "GenSigStartValue" SG_ 811 CCU_ExternalTemperatureFailSts 1;
BA_ "GenSigInvalidValue" SG_ 811 CCU_ExternalTemperatureFailSts 1;
BA_ "GenSigSendType" SG_ 811 CCU_ExternalTemperatureFailSts 0;
BA_ "GenSigStartValue" SG_ 1037 USS_WorkSts 1;
BA_ "GenSigSendType" SG_ 1037 USS_WorkSts 0;
BA_ "GenSigSendType" SG_ 1037 USS_FrnSysSts_reserved 0;
BA_ "GenSigSendType" SG_ 1037 USS_RearSysSts_reserved 0;
BA_ "GenSigSendType" SG_ 1037 USS_SndCadComm 0;
BA_ "GenSigSendType" SG_ 1037 USS_LFDistance_reserved 0;
BA_ "GenSigSendType" SG_ 1037 USS_RFDistance_reserved 0;
BA_ "GenSigInvalidValue" SG_ 1037 USS_LRDistance 15;
BA_ "GenSigSendType" SG_ 1037 USS_LRDistance 0;
BA_ "GenSigInvalidValue" SG_ 1037 USS_LMRDistance 15;
BA_ "GenSigSendType" SG_ 1037 USS_LMRDistance 0;
BA_ "GenSigInvalidValue" SG_ 1037 USS_RMRDistance 15;
BA_ "GenSigSendType" SG_ 1037 USS_RMRDistance 0;
BA_ "GenSigInvalidValue" SG_ 1037 USS_RRDistance 15;
BA_ "GenSigSendType" SG_ 1037 USS_RRDistance 0;
BA_ "GenSigStartValue" SG_ 1037 USS_PrkAssSysSta 1;
BA_ "GenSigInvalidValue" SG_ 1037 USS_PrkAssSysSta 1;
BA_ "GenSigSendType" SG_ 1037 USS_PrkAssSysSta 0;
BA_ "GenSigSendType" SG_ 1037 USS_FLSenSta_reserved 0;
BA_ "GenSigSendType" SG_ 1037 USS_FRSenSta_reserved 0;
BA_ "GenSigSendType" SG_ 1037 USS_RLSenSta 0;
BA_ "GenSigSendType" SG_ 1037 USS_RRSenSta 0;
BA_ "GenSigSendType" SG_ 1037 USS_RLMSenSta 0;
BA_ "GenSigSendType" SG_ 1037 USS_RRMSenSta 0;
BA_ "GenSigSendType" SG_ 1037 USS_SetSta 0;
BA_ "GenSigSendType" SG_ 296 Checksum_0x128 0;
BA_ "GenSigInvalidValue" SG_ 296 Rolling_Counter_0x128 15;
BA_ "GenSigSendType" SG_ 296 Rolling_Counter_0x128 0;
BA_ "GenSigSendType" SG_ 296 ADAS_RCTA_IndLeft 0;
BA_ "GenSigSendType" SG_ 296 ADAS_RCTA_IndRight 0;
BA_ "GenSigSendType" SG_ 296 ADAS_RCTA_SndWarn 0;
BA_ "GenSigInvalidValue" SG_ 296 ADAS_RCTA_check 3;
BA_ "GenSigSendType" SG_ 296 ADAS_RCTA_check 0;
BA_ "GenSigSendType" SG_ 296 ADAS_RCTA_state 0;
BA_ "GenSigStartValue" SG_ 296 ADAS_RCTA_sens_Feed_Reserved 1;
BA_ "GenSigInvalidValue" SG_ 296 ADAS_RCTA_sens_Feed_Reserved 3;
BA_ "GenSigSendType" SG_ 296 ADAS_RCTA_sens_Feed_Reserved 0;
BA_ "GenSigStartValue" SG_ 296 ADAS_RCTA_Mode_Feed 1;
BA_ "GenSigInvalidValue" SG_ 296 ADAS_RCTA_Mode_Feed 3;
BA_ "GenSigSendType" SG_ 296 ADAS_RCTA_Mode_Feed 0;
BA_ "GenSigSendType" SG_ 307 Checksum_0x133 0;
BA_ "GenSigInvalidValue" SG_ 307 Rolling_Counter_0x133 15;
BA_ "GenSigSendType" SG_ 307 Rolling_Counter_0x133 0;
BA_ "GenSigInvalidValue" SG_ 307 ADAS_BSD_check 3;
BA_ "GenSigSendType" SG_ 307 ADAS_BSD_check 0;
BA_ "GenSigSendType" SG_ 307 ADAS_BSD_state 0;
BA_ "GenSigStartValue" SG_ 307 ADAS_BSD_AudChime_Feed 1;
BA_ "GenSigInvalidValue" SG_ 307 ADAS_BSD_AudChime_Feed 3;
BA_ "GenSigSendType" SG_ 307 ADAS_BSD_AudChime_Feed 0;
BA_ "GenSigSendType" SG_ 307 ADAS_BSD_IndLeft 0;
BA_ "GenSigSendType" SG_ 307 ADAS_BSD_IndRight 0;
BA_ "GenSigSendType" SG_ 307 ADAS_BSD_SndWarn 0;
BA_ "GenSigStartValue" SG_ 307 ADAS_BSD_Mode_Feed 1;
BA_ "GenSigInvalidValue" SG_ 307 ADAS_BSD_Mode_Feed 3;
BA_ "GenSigSendType" SG_ 307 ADAS_BSD_Mode_Feed 0;
BA_ "GenSigStartValue" SG_ 307 ADAS_BSD_sens_Feed 1;
BA_ "GenSigInvalidValue" SG_ 307 ADAS_BSD_sens_Feed 3;
BA_ "GenSigSendType" SG_ 307 ADAS_BSD_sens_Feed 0;
BA_ "GenSigSendType" SG_ 850 Checksum_0x352 0;
BA_ "GenSigInvalidValue" SG_ 850 Rolling_Counter_0x352 15;
BA_ "GenSigSendType" SG_ 850 Rolling_Counter_0x352 0;
BA_ "GenSigSendType" SG_ 850 ADAS_DOW_Warn 0;
BA_ "GenSigSendType" SG_ 850 ADAS_DOW_SndWarn 0;
BA_ "GenSigSendType" SG_ 850 ADAS_DOW_state 0;
BA_ "GenSigSendType" SG_ 850 ADAS_DOW_IndLeft 0;
BA_ "GenSigSendType" SG_ 850 ADAS_DOW_IndRight 0;
BA_ "GenSigStartValue" SG_ 850 ADAS_DOW_sens_Feed_Reserved 1;
BA_ "GenSigInvalidValue" SG_ 850 ADAS_DOW_sens_Feed_Reserved 3;
BA_ "GenSigSendType" SG_ 850 ADAS_DOW_sens_Feed_Reserved 0;
BA_ "GenSigStartValue" SG_ 850 ADAS_DOW_Mode_Feed 1;
BA_ "GenSigInvalidValue" SG_ 850 ADAS_DOW_Mode_Feed 3;
BA_ "GenSigSendType" SG_ 850 ADAS_DOW_Mode_Feed 0;
BA_ "GenSigStartValue" SG_ 850 ADAS_DOW_AudChime_Feed 1;
BA_ "GenSigInvalidValue" SG_ 850 ADAS_DOW_AudChime_Feed 3;
BA_ "GenSigSendType" SG_ 850 ADAS_DOW_AudChime_Feed 0;
BA_ "GenSigInvalidValue" SG_ 850 ADAS_DOW_check 3;
BA_ "GenSigSendType" SG_ 850 ADAS_DOW_check 0;
BA_ "GenSigSendType" SG_ 1216 Checksum_0x4C0 0;
BA_ "GenSigInvalidValue" SG_ 1216 Rolling_Counter_0x4C0 15;
BA_ "GenSigSendType" SG_ 1216 Rolling_Counter_0x4C0 0;
BA_ "GenSigSendType" SG_ 1216 ADAS_Warning_Flag_1 0;
BA_ "GenSigSendType" SG_ 1216 ADAS_Warning_Flag_2 0;
BA_ "GenSigSendType" SG_ 1216 ADAS_Warning_Flag_3 0;
BA_ "GenSigSendType" SG_ 1216 ADAS_Warning_Flag_4 0;
BA_ "GenSigSendType" SG_ 1216 ADAS_Warning_Flag_5 0;
BA_ "GenSigSendType" SG_ 1216 ADAS_Warning_Flag_6 0;
BA_ "GenSigSendType" SG_ 1216 ADAS_Warning_Flag_7 0;
BA_ "GenSigSendType" SG_ 1216 ADAS_Warning_Flag_8 0;
BA_ "GenSigSendType" SG_ 1216 ADAS_Warning_Flag_9 0;
BA_ "GenSigSendType" SG_ 1216 ADAS_Warning_Flag_10 0;
BA_ "GenSigSendType" SG_ 1216 ADAS_Warning_Flag_11 0;
BA_ "GenSigSendType" SG_ 1216 ADAS_Warning_Flag_12 0;
BA_ "GenSigSendType" SG_ 1216 ADAS_Warning_Flag_13 0;
BA_ "GenSigSendType" SG_ 1216 ADAS_Warning_Flag_14 0;
BA_ "GenSigSendType" SG_ 1216 ADAS_Warning_Flag_15 0;
BA_ "GenSigSendType" SG_ 1216 ADAS_Warning_Flag_16 0;
BA_ "GenSigSendType" SG_ 1216 ADAS_Warning_Flag_17 0;
BA_ "GenSigSendType" SG_ 1216 ADAS_Warning_Flag_18 0;
BA_ "GenSigSendType" SG_ 1216 ADAS_Warning_Flag_19 0;
BA_ "GenSigSendType" SG_ 1216 ADAS_Warning_Flag_20 0;
BA_ "GenSigSendType" SG_ 1216 ADAS_Warning_Flag_21 0;
BA_ "GenSigSendType" SG_ 1216 ADAS_Warning_Flag_22 0;
BA_ "GenSigSendType" SG_ 1216 ADAS_Warning_Flag_23 0;
BA_ "GenSigSendType" SG_ 1216 ADAS_Warning_Flag_24 0;
BA_ "GenSigSendType" SG_ 1216 ADAS_Warning_Flag_25 0;
BA_ "GenSigSendType" SG_ 1216 ADAS_Warning_Flag_26 0;
BA_ "GenSigSendType" SG_ 1216 ADAS_Warning_Flag_27 0;
BA_ "GenSigSendType" SG_ 1216 ADAS_Warning_Flag_28 0;
BA_ "GenSigSendType" SG_ 1216 ADAS_Reserved_signal3 0;
BA_ "GenSigSendType" SG_ 1216 ADAS_Reserved_signal4 0;
BA_ "GenSigSendType" SG_ 1216 ADAS_Reserved_signal5 0;
BA_ "GenSigSendType" SG_ 851 Checksum_0x353 0;
BA_ "GenSigInvalidValue" SG_ 851 Rolling_Counter_0x353 15;
BA_ "GenSigSendType" SG_ 851 Rolling_Counter_0x353 0;
BA_ "GenSigSendType" SG_ 851 ADAS_RadarRight_Cal_Status 0;
BA_ "GenSigSendType" SG_ 851 ADAS_RadarLeft_Cal_Status 0;
BA_ "GenSigSendType" SG_ 851 ADAS_RadarRight_DynaCal_Status 0;
BA_ "GenSigSendType" SG_ 851 ADAS_RadarLeft_DynaCal_Status 0;
BA_ "GenSigSendType" SG_ 851 ADAS_MasterSRR_check 0;
BA_ "GenSigSendType" SG_ 851 ADAS_SlaveSRR_check 0;
BA_ "GenSigInvalidValue" SG_ 851 ADAS_CalSensorMasterProgress 255;
BA_ "GenSigSendType" SG_ 851 ADAS_CalSensorMasterProgress 0;
BA_ "GenSigInvalidValue" SG_ 851 ADAS_CalSensorSlaverProgress 255;
BA_ "GenSigSendType" SG_ 851 ADAS_CalSensorSlaverProgress 0;
BA_ "GenSigSendType" SG_ 851 ADAS_Cal_LeftInstallDeviation 0;
BA_ "GenSigSendType" SG_ 851 ADAS_Cal_RightInstallDeviation 0;
BA_ "GenSigSendType" SG_ 133 Checksum_0x85 0;
BA_ "GenSigInvalidValue" SG_ 133 Rolling_Counter_0x85 15;
BA_ "GenSigSendType" SG_ 133 Rolling_Counter_0x85 0;
BA_ "GenSigSendType" SG_ 133 ACM_Crash_Sts 0;
BA_ "GenSigSendType" SG_ 133 ACM_Airbag_Deployment_Status 0;
BA_ "GenSigSendType" SG_ 133 ACM_Crash_Intensity 0;
BA_ "GenSigSendType" SG_ 133 ACM_Front_Crash 0;
BA_ "GenSigSendType" SG_ 133 ACM_DriverSide_Crash 0;
BA_ "GenSigSendType" SG_ 133 ACM_PassSide_Crash 0;
BA_ "GenSigSendType" SG_ 133 ACM_Rear_Crash 0;
BA_ "GenSigSendType" SG_ 133 ACM_Rollover_Crash 0;
BA_ "GenSigSendType" SG_ 897 Checksum_0x381 0;
BA_ "GenSigInvalidValue" SG_ 897 Rolling_Counter_0x381 15;
BA_ "GenSigSendType" SG_ 897 Rolling_Counter_0x381 0;
BA_ "GenSigStartValue" SG_ 897 ACM_Seat_Occupancy_Passenger 2;
BA_ "GenSigSendType" SG_ 897 ACM_Seat_Occupancy_Passenger 0;
BA_ "GenSigStartValue" SG_ 897 ACM_Seat_Occupancy_2nd_Row_Dri_r 2;
BA_ "GenSigSendType" SG_ 897 ACM_Seat_Occupancy_2nd_Row_Dri_r 0;
BA_ "SystemSignalLongSymbol" SG_ 897 ACM_Seat_Occupancy_2nd_Row_Dri_r "ACM_Seat_Occupancy_2nd_Row_Dri_reserved";
BA_ "GenSigStartValue" SG_ 897 ACM_Seat_Occupancy_2nd_Row_Pas_r 2;
BA_ "GenSigSendType" SG_ 897 ACM_Seat_Occupancy_2nd_Row_Pas_r 0;
BA_ "SystemSignalLongSymbol" SG_ 897 ACM_Seat_Occupancy_2nd_Row_Pas_r "ACM_Seat_Occupancy_2nd_Row_Pas_reserved";
BA_ "GenSigStartValue" SG_ 897 ACM_Seat_Occupancy_2nd_Row_Mid_r 2;
BA_ "GenSigSendType" SG_ 897 ACM_Seat_Occupancy_2nd_Row_Mid_r 0;
BA_ "SystemSignalLongSymbol" SG_ 897 ACM_Seat_Occupancy_2nd_Row_Mid_r "ACM_Seat_Occupancy_2nd_Row_Mid_reserved";
BA_ "GenSigSendType" SG_ 897 ACM_Seat_Belt_Status_Passenger 0;
BA_ "GenSigSendType" SG_ 897 ACM_Seat_Belt_Status_Driver 0;
BA_ "GenSigSendType" SG_ 897 ACM_Seat_Belt_Status_2nd_Row_Dri 0;
BA_ "SystemSignalLongSymbol" SG_ 897 ACM_Seat_Belt_Status_2nd_Row_Dri "ACM_Seat_Belt_Status_2nd_Row_Dri_reserved";
BA_ "GenSigSendType" SG_ 897 ACM_Seat_Belt_Status_2nd_Row_Mid 0;
BA_ "SystemSignalLongSymbol" SG_ 897 ACM_Seat_Belt_Status_2nd_Row_Mid "ACM_Seat_Belt_Status_2nd_Row_Mid_reserved";
BA_ "GenSigSendType" SG_ 897 ACM_Seat_Belt_Status_2nd_Row_Pas 0;
BA_ "SystemSignalLongSymbol" SG_ 897 ACM_Seat_Belt_Status_2nd_Row_Pas "ACM_Seat_Belt_Status_2nd_Row_Pas_reserved";
BA_ "GenSigStartValue" SG_ 897 ACM_Seat_Belt_Status_3rd_Row_Dri 2;
BA_ "GenSigSendType" SG_ 897 ACM_Seat_Belt_Status_3rd_Row_Dri 0;
BA_ "SystemSignalLongSymbol" SG_ 897 ACM_Seat_Belt_Status_3rd_Row_Dri "ACM_Seat_Belt_Status_3rd_Row_Dri_reserved";
BA_ "GenSigStartValue" SG_ 897 ACM_Seat_Belt_Status_3rd_Row_Pas 2;
BA_ "GenSigSendType" SG_ 897 ACM_Seat_Belt_Status_3rd_Row_Pas 0;
BA_ "SystemSignalLongSymbol" SG_ 897 ACM_Seat_Belt_Status_3rd_Row_Pas "ACM_Seat_Belt_Status_3rd_Row_Pas_reserved";
BA_ "GenSigSendType" SG_ 1160 Checksum_0x488 0;
BA_ "GenSigInvalidValue" SG_ 1160 Rolling_Counter_0x488 15;
BA_ "GenSigSendType" SG_ 1160 Rolling_Counter_0x488 0;
BA_ "GenSigStartValue" SG_ 1160 ACM_Malfunction 1;
BA_ "GenSigSendType" SG_ 1160 ACM_Malfunction 0;
BA_ "GenSigSendType" SG_ 1160 ACM_Pre_Drive_Check 0;
BA_ "GenSigStartValue" SG_ 1160 ACM_in_Plant_Mode 1;
BA_ "GenSigSendType" SG_ 1160 ACM_in_Plant_Mode 0;
BA_ "GenSigSendType" SG_ 1160 ACM_PAB_Suppression 0;
BA_ "GenSigSendType" SG_ 1160 ACM_Airbag_Disabled 0;
BA_ "GenSigSendType" SG_ 1160 ACM_Development_Calibration 0;
BA_ "GenSigStartValue" SG_ 1160 ACM_In_Disposal_Mode 1;
BA_ "GenSigSendType" SG_ 1160 ACM_In_Disposal_Mode 0;
BA_ "GenSigStartValue" SG_ 1160 ACM_Seatbelt_Reminder_Request 1;
BA_ "GenSigSendType" SG_ 1160 ACM_Seatbelt_Reminder_Request 0;
BA_ "GenSigStartValue" SG_ 1160 ACM_SBR_Chime_Req 1;
BA_ "GenSigSendType" SG_ 1160 ACM_SBR_Chime_Req 0;
BA_ "GenSigStartValue" SG_ 1160 ACM_SBR_Blinking_Req 1;
BA_ "GenSigSendType" SG_ 1160 ACM_SBR_Blinking_Req 0;
VAL_ 1191 MHU_BTPairing 3 "BT Phone and Media" 2 "BT Phone" 1 "Apple CarPlay" 0 "Not active No connetced" ;
VAL_ 1191 MHU_MaintenanceEvent 0 "No Maintenance Event" 1 " Maintenance Reminder " 2 "Reserved" 3 "Invalid" ;
VAL_ 1191 MHU_Arrow 1 "DEPART(Start driving Used before accurate location or orientation is known)" 2 "NAME_CHANGE(Indicate a street name change without turn)" 3 "KEEP LEFT( Keep Left. Usually for bifurcations or other smooth maneuvers(compare to Slight Left Turn)" 4 "KEEP RIGHT( Keep right. Usually for bifurcations or other smooth maneuvers(compare to Slight rightTurn))" 5 "SLIGHT TURN _RIGHT(Make a 10-45 degree RIGHT turn)" 6 "SLIGHT TURN _LEFT(Make a 10-45 degree LEFTturn)" 7 "TURN _RIGHT(Make a 45-135 degree RIGHT turn)" 8 "TURN _LEFT(Make a 45-135 degree LEFT turn)" 9 "TURN _RIGHT_END(At the end of the road，turn right)" 10 "TURN _LEFT_END(At the end of the road，turn left)" 11 "SHARP_TURN_RIGHT(Make a 135-175 degree RIGHT turn)" 12 "SHARP_TURN_LEFT(Make a 135-175 degree LEFT turn)" 13 "U TURN_RIGHT(Make a 180 dearee RIGHT tum onto the same road)" 14 "U TURN_LEFT(Make a 180 dearee LEFT tum onto the same road)" 15 "ON RAMP_RIGHT(Take an RIGHT on-ramp onto a major road)" 16 "ON RAMP_LEFT(Take an LEFT on-ramp onto a major road)" 17 "OFF RAMP_RIGHT(Take an RIGHT off-ramp onto a major road)" 18 "OFF RAMP_LEFT(Take an LEFT off-ramp onto a major road)" 19 "FORK_RIGHT(Take a RIGHT fork while on a ramp)" 20 "FORK__LEFT(Take a LEFT fork while on a ramp)" 21 "MERGE(Merge with another road)" 22 "STRAIGHT(Indicates a potentially confusing intersection, in which the user is to proceed straight)" 23 "CONTINUE(Continue tp follow the road the vehicle is currently on)" 24 "FERRY_BOAT(Board a boat ferry)" 25 "ENTER FERRY" 26 "EXIT FERRY" 27 "CHANGE FERRY(Board a boat ferry)" 28 "FERRY_TRAIN(Board a train ferry(Google Maps display no icon))" 29 "CHANGE HIGH WAY _1( Change Highway. Highway to highway change with plied or unknown side Of the road)" 30 "CHANGE HIGH WAY _2( Change Highway. Highway to highway change with plied or unknown side Of the road)" 31 "CHANGE HIGH WAY _3( Change Highway Right. Highway to highway change from the right side of the road)" ;
VAL_ 215 MHU_SET_Second 63 "Invalid" ;
VAL_ 215 MHU_SET_Min 63 "Invalid" ;
VAL_ 215 MHU_SET_Hour 31 "Invalid" ;
VAL_ 215 MHU_SET_Day 0 "Invalid" ;
VAL_ 215 MHU_SET_Month 15 "Invalid" ;
VAL_ 215 MHU_SET_Year 255 "Invalid" ;
VAL_ 967 MHU_St_DimmingIPC 15 "Invalid" 14 "Level 15" 13 "Level 14" 12 "Level 13" 11 "Level 12" 10 "Level 11" 9 "Level 10" 8 "Level 9" 7 "Level 8" 6 "Level 7" 5 "Level 6" 4 "Level 5" 3 "Level 4" 2 "Level 3" 1 "Level 2" 0 "Level 1" ;
VAL_ 711 MHU_FavoriteFlag 1 "Active" 0 "Not active" ;
VAL_ 711 MHU_AMRadioFrequanceValue 16383 "Invalid" ;
VAL_ 711 MHU_FMRadioFrequanceValue 1023 "Invalid" ;
VAL_ 711 MHU_SourceStationMode_Reserved 15 "Resevered" 14 "Resevered" 13 "Resevered" 12 "Resevered" 11 "Resevered" 10 "Resevered" 9 "Resevered" 8 "AndroidAuto" 7 "Carplay" 6 "USB Picture" 5 "USB Vedio" 4 "USB Music" 3 "BT Music" 2 "FM" 1 "AM" 0 "None" ;
VAL_ 711 MHU_Route_Reserved 1 "ON" 0 "OFF" ;
VAL_ 695 MHU_MediaType 15 "Invaild" 8 "FM" 7 "AM" 6 "MUSIC" 5 "VIDEO" 4 "IMAGE" 3 "BT" 2 "AndroidAuto" 1 "CarPlay" 0 "None" ;
VAL_ 695 MHU_MediaStatus_Reserved 3 "Invaild" 2 "pause" 1 "playing" 0 "unready" ;
VAL_ 695 MHU_PhoneStatus 15 "Invalid" 8 "Hold current call" 7 "Missed call from" 6 "MUTE" 5 "ACTIVE" 4 "INCOMING" 3 "ALERTING" 2 "DIALING" 1 "IDLE" 0 "DISCONNECTED" ;
VAL_ 695 MHU_NaviType 3 "Invalid" 2 "AndroidAuto" 1 "CarPlay" 0 "Local" ;
VAL_ 695 MHU_NaviStatus 1 "Navigating" 0 "not Navigating" ;
VAL_ 695 MHU_Destination_Reachsts 3 "DESTINATION_RIGHT(Indicated arrival at destination,Destination is on right)" 2 "DESTINATION__LEFT(Indicated arrival at destination,Destination is on rleft)" 1 "DESTINATION_not reached(Arrive End Of Navigation Navigation has completed, but the rest of the journey will need to use another)" 0 "Inactive" ;
VAL_ 503 MHU_Compass 8 "SW" 7 "SE" 6 "S" 5 "W" 4 "NW" 3 "N" 2 "NE" 1 "E" 0 "inaction" ;
VAL_ 503 MHU_Roundabout 0 "Inactive" 1 "ROUNDABOUT_ENTER_RIGHT(Enter a large roundabout_RIGHT)" 2 "ROUNDABOUT_ENTER__LEFT(Enter a large roundabout_LEFT)" 3 "ROUNDABOUT_EXIT_RIGHT(Exit a large roundabout_RIGHT)" 4 "ROUNDABOUT_EXIT__LEFT(Exit a large roundabout__LEFT)" 5 "ROUNDABOUT_RIGHT1(Turn Angle（In Degreen）:1-67)" 6 "ROUNDABOUT_RIGHT2(Turn Angle（In Degreen）:68-112)" 7 "ROUNDABOUT_RIGHT3(Turn Angle（In Degreen）:113-157)" 8 "ROUNDABOUT_RIGHT4(Turn Angle（In Degreen）:158-202)" 9 "ROUNDABOUT_RIGHT5(Turn Angle（In Degreen）:203-247)" 10 "ROUNDABOUT_RIGHT6(Turn Angle（In Degreen）:248-292)" 11 "ROUNDABOUT_RIGHT7(Turn Angle（In Degreen）:293-337)" 12 "ROUNDABOUT_RIGHT8(Turn Angle（In Degreen）:338-360)" 13 "ROUNDABOUT_RIGHT9" 14 "ROUNDABOUT_RIGHT10" 15 "ROUNDABOUT_RIGHT11" 16 "ROUNDABOUT_RIGHT12" 17 "ROUNDABOUT_RIGHT13" 18 "ROUNDABOUT_RIGHT14" 19 "ROUNDABOUT_RIGHT15" 20 "ROUNDABOUT_RIGHT16" 21 "ROUNDABOUT_RIGHT17" 22 "ROUNDABOUT_RIGHT18" 23 "ROUNDABOUT_RIGHT19" 24 "ROUNDABOUT_LEFT1(Turn Angle（In Degreen）:1-67)" 25 "ROUNDABOUT_LEFT2(Turn Angle（In Degreen）:68-112)" 26 "ROUNDABOUT_LEFT3(Turn Angle（In Degreen）:113-157)" 27 "ROUNDABOUT_LEFT4(Turn Angle（In Degreen）:158-202)" 28 "ROUNDABOUT_LEFT5(Turn Angle（In Degreen）:203-247)" 29 "ROUNDABOUT_LEFT6(Turn Angle（In Degreen）:248-292)" 30 "ROUNDABOUT_LEFT7(Turn Angle（In Degreen）:293-337)" 31 "ROUNDABOUT_LEFT8(Turn Angle（In Degreen）:338-360)" 32 "ROUNDABOUT_LEFT9" 33 "ROUNDABOUT_LEFT10" 34 "ROUNDABOUT_LEFT11" 35 "ROUNDABOUT_LEFT12" 36 "ROUNDABOUT_LEFT13" 37 "ROUNDABOUT_LEFT14" 38 "ROUNDABOUT_LEFT15" 39 "ROUNDABOUT_LEFT16" 40 "ROUNDABOUT_LEFT17" 41 "ROUNDABOUT_LEFT18" 42 "ROUNDABOUT_LEFT19" ;
VAL_ 503 MHU_USBConnect 1 "USB connect" 0 "No USB connect" ;
VAL_ 503 MHU_MEDIA_MUTE 1 "Active" 0 "Not active" ;
VAL_ 503 MHU_PollutionReq 1 "Active" 0 "Inactive" ;
VAL_ 852 MHU_BSD_On 3 "Signal invalid" 2 "inactive" 1 "ON" 0 "OFF" ;
VAL_ 852 MHU_BSD_sens_Reserved 7 "invalid" 6 "Reserved" 5 "Reserved" 4 "Reserved" 3 "Inactive" 2 "Late" 1 "Normal" 0 "Early" ;
VAL_ 852 MHU_BSD_AudWarning 3 "Signal invalid" 2 "inactive" 1 "ON" 0 "OFF" ;
VAL_ 852 MHU_RCTA_On 3 "Signal invalid" 2 "inactive" 1 "ON" 0 "OFF" ;
VAL_ 852 MHU_RCTA_sens_Reserved 7 "invalid" 6 "Reserved" 5 "Reserved" 4 "Reserved" 3 "Inactive" 2 "Late" 1 "Normal" 0 "Early" ;
VAL_ 852 MHU_PA_On 3 "Signal invalid" 2 "inactive" 1 "ON" 0 "OFF" ;
VAL_ 852 MHU_DOW_Mode 3 "Signal invalid" 2 "inactive" 1 "ON" 0 "OFF" ;
VAL_ 852 MHU_DOW_sens_Reserved 7 "invalid" 6 "Reserved" 5 "Reserved" 4 "Reserved" 3 "Inactive" 2 "Late" 1 "Normal" 0 "Early" ;
VAL_ 852 MHU_DOW_AudWarning 3 "Signal invalid" 2 "inactive" 1 "ON" 0 "OFF" ;
VAL_ 1025 MHU_SET_DoorSpeedLock 15 "Invalid" 14 "Reserved" 13 "Reserved" 12 "Reserved" 11 "Reserved" 10 "Reserved" 9 "Reserved" 8 "Reserved" 7 "Reserved" 6 "Inactive" 5 "25KMH" 4 "20KMH" 3 "15KMH" 2 "10KMH" 1 "5KMH" 0 "OFF" ;
VAL_ 1025 MHU_SET_RemoteDoorUnlock_reserve 3 "Signal invalid" 2 "Reserved" 1 "All doors" 0 "Driver door" ;
VAL_ 1025 MHU_SET_RemoteLockFeedback 7 "Signal Invalid" 6 "Reserved" 5 "Reserved" 4 "inactive" 3 "Horn" 2 "Light" 1 "Light/Horn" 0 "OFF" ;
VAL_ 1025 MHU_SET_AutoUnlockDoor 7 "Invalid" 6 "Reserved" 5 "Reserved" 4 "Reserved" 3 "Reserved" 2 "Inactive" 1 "ON" 0 "OFF" ;
VAL_ 1025 MHU_SET_MirrorAuto_reserved 3 "Signal invalid" 2 "Reserved" 1 "ON" 0 "OFF" ;
VAL_ 1025 MHU_Anti_theftAlarmSet 7 "Invalid" 6 "Reserved" 5 "Reserved" 4 "inactive" 3 "Light/Horn" 2 "Horn" 1 "Light" 0 "OFF" ;
VAL_ 1025 MHU_TriggerReadKey 3 "Signal Invalid" 2 "Reserved" 1 "Request" 0 "No Request" ;
VAL_ 1026 MHU_Heatrearglass_Set 0 "OFF" 1 "ON" 2 "No action" 3 "Invalid" ;
VAL_ 1026 MHU_SET_DayTimeRunningLight_rese 3 "Signal invalid" 2 "Reserved" 1 "ON" 0 "OFF" ;
VAL_ 1026 MHU_SET_FollowMeHomeTime 7 "Invalid" 6 "Inactive" 5 "Reserved" 4 "120s" 3 "90s" 2 "60s" 1 "30s" 0 "OFF" ;
VAL_ 1027 Rolling_Counter_0x403 15 "Invalid" ;
VAL_ 1027 MHU_SET_TCS_OnOff 0 "OFF (keep sending for 2 seconds)" 1 "ON (keep sending for 2 seconds)" 2 "No action" 3 "Invalid" ;
VAL_ 1027 MHU_SET_DrivingModeSwitch 3 "sport mode (should be hold during 1 second)" 2 "normal mode (should be hold during 1 second)" 1 "eco mode (should be hold during 1 second)" 0 "no change request" ;
VAL_ 1027 MHU_SET_RegenLevel 3 "No action" 2 "High" 1 "Low" 0 "none" ;
VAL_ 1027 MHU_VCU_CreepDisable_stt 0 "No request" 1 "Creep Disable request" 2 "Reserved" 3 "Invalid" ;
VAL_ 1027 MHU_HVACTurnON 0 "No request" 1 "ON" 2 "Reserved" 3 "Invalid" ;
VAL_ 1027 MHU_ChargeScheduleSet 0 "Disabled" 1 "Enabled" 2 "No Action" 3 "Reserved" ;
VAL_ 1027 MHU_ChargingRequest 0 "Reserved" 1 "Request scheduled start charging" 2 "Request stop" 3 "No effect" ;
VAL_ 1027 MHU_ValetMode_Activation 0 "Inactive" 1 "Active" 254 "Reserved" 255 "Invalid" ;
VAL_ 807 MHU_CCU_AC_Button 3 "Invalid" 1 "Press" 0 "Release" ;
VAL_ 807 MHU_REC_Button 3 "Invalid" 1 "Press" 0 "Release" ;
VAL_ 807 MHU_SetBlowMode 7 "Invalid" 6 "Reserve" 5 "Reserve" 4 "Foot and window" 3 "Foot" 2 "foot and face" 1 "face" 0 "Inactive" ;
VAL_ 807 MHU_BlowerLevelSetting 9 "level 8" 8 "level 7" 7 "level 6" 6 "level 5" 5 "level 4" 4 "level 3" 3 "level 2" 2 "level 1" 1 "OFF" 0 "Inactive" ;
VAL_ 807 MHU_SetDriverTemp 63 "Invalid" 16 "level 8" 15 "level 7" 14 "level 6" 13 "level 5" 12 "level 4" 11 "level 3" 10 "level 2" 9 "level 1" 8 "level 8" 7 "level 7" 6 "level 6" 5 "level 5" 4 "level 4" 3 "level 3" 2 "level 2" 1 "level 1" 0 "Inactive" ;
VAL_ 807 MHU_ACM_Reserved 3 "Invalid" 1 "Active" 0 "Inactive" ;
VAL_ 807 MHU_FrontDefrostReq_Reserved 3 "Invalid" 1 "Active" 0 "Inactive" ;
VAL_ 1058 Rolling_Counter_0x422 15 "Invalid" ;
VAL_ 1058 MHU_STAT_DateTimeFormat 3 "Signal invalid" 2 "Reserved" 1 "12H" 0 "24H" ;
VAL_ 1058 MHU_DISPLAY_STATUS 0 "OFF" 1 "ON" 2 "Reserved" 3 "Invalid" ;
VAL_ 1058 MHU_STAT_Language 31 "Signal invalid" 30 "Reserved" 29 "Reserved" 28 "Reserved" 27 "Reserved" 26 "Reserved" 25 "Reserved" 24 "Reserved" 23 "Reserved" 22 "Reserved" 21 "Reserved" 20 "Reserved" 19 "Reserved" 18 "Reserved" 17 "Reserved" 16 "Reserved" 15 "Reserved" 14 "Reserved" 13 "Reserved" 12 "Reserved" 11 "Reserved" 10 "Reserved" 9 "Reserved" 8 "Reserved" 7 "Reserved" 6 "Cambodia" 5 "Laos" 4 "Indonesian" 3 "Thai" 2 "Malay" 1 "English" 0 "Vietnamese" ;
VAL_ 267 TBOX_STAT_TerminalReq 7 "Signal invalid" 6 "No action" 5 "Reserved" 4 "SW Update OTA" 3 "Engine start (eMotor running)" 2 "ON (Driver Present)" 1 "ACC (Park)" 0 "OFF(Comfort Enable)" ;
VAL_ 259 REQ_ConsumerControlAudioVolumeCo 7 "signal invalid" 6 "Reserved" 5 "Reserved" 4 "Reserved" 3 "Reserved" 2 "Level 2" 1 "Level 1" 0 "No Reduction" ;
VAL_ 269 MHU_BCM_reqTrunk 3 "Signal invalid" 2 "No action" 1 "Open" 0 "Close reserved" ;
VAL_ 269 MHU_BCM_RemoteDoorCtrl 3 "Signal invalid" 2 "No action" 1 "Unlock" 0 "Lock" ;
VAL_ 269 MHU_APM_ReqWindow 2 "Open(Bottom) " 1 "Closed(Top)" 0 "No action" ;
VAL_ 271 MHU_SetHighBeam 1 "Request flashing" 2 "No request" 3 "Invalid" ;
VAL_ 271 MHU_SetHornOnOff 0 "OFF" 1 "ON" 2 "No action" 3 "Invalid" ;
VAL_ 271 MHU_SetLowBeam 0 "OFF" 1 "ON" 2 "No action" 3 "Invalid" ;
VAL_ 1074 Rolling_Counter_0x432 15 "Invalid" ;
VAL_ 1074 MHU_FOTA_State 0 "INIT" 1 "NORMAL" 2 "FOTA FLASHING" 3 "FOTA-SUSPENDED" 4 "FAIL-SAFE-ERROR" 5 "SHUTDOWN" 6 "REMOTE DIAGNOSTICS" 7 "Invalid" ;
VAL_ 1020 XGW_FOTA_StateConfirm 0 "INIT" 1 "NORMAL" 2 "FOTA FLASHING" 3 "FOTA-SUSPENDED" 4 "FAIL-SAFE-ERROR" 5 "SHUTDOWN" 6 "REMOTE DIAGNOSTICS" 7 "Invalid" ;
VAL_ 931 BMS_MHU_Auth_Sts 2 "failed " 1 "pass " 0 "init" ;
VAL_ 1087 IPC_Sec 63 "Invalid" ;
VAL_ 1087 IPC_Min 63 "Invalid" ;
VAL_ 1087 IPC_Hour 31 "Invalid" ;
VAL_ 1087 IPC_Day 31 "Invalid" ;
VAL_ 1087 IPC_Month 15 "Invalid" ;
VAL_ 1087 IPC_Year 255 "Invalid" ;
VAL_ 1087 IPC_SelfCheckStatus 1 "self-check finish" 0 "self-checking" ;
VAL_ 524 Rolling_Counter_0x20C 15 "Invalid" ;
VAL_ 524 IPC_ODO 1048575 "Invalid" ;
VAL_ 703 IPC_TripA 65535 "Invalid" ;
VAL_ 703 IPC_AverageSpeedTripA 4095 "Invalid" ;
VAL_ 703 IPC_AverageConsumptionTripA 1023 "Invalid" ;
VAL_ 703 IPC_ParkBrakeSts 3 "Invalid" 2 "Reserved" 1 "Applied" 0 "Released" ;
VAL_ 703 IPC_VehSpd 32767 "Invalid" ;
VAL_ 719 IPC_TripB 65535 "Invalid" ;
VAL_ 719 IPC_AverageSpeedTripB 4095 "Invalid" ;
VAL_ 719 IPC_AverageConsumptionTripB 1023 "Invalid" ;
VAL_ 751 IPC_TripAuto 65535 "Invalid" ;
VAL_ 751 IPC_AverageSpeedTripAuto 4095 "Invalid" ;
VAL_ 751 IPC_AverageConsumptionTripAuto 1023 "Invalid" ;
VAL_ 735 IPC_TireLearningReq_reserved 3 "Reserved" 2 "Reserved" 1 "Requset" 0 "No requset" ;
VAL_ 735 IPC_TireResetReq 3 "Reserved" 2 "Reserved" 1 "Requset to reset" 0 "No requset" ;
VAL_ 975 IPC_DimmingIPCLevel 15 "Invalid" 14 "Level 15" 13 "Level 14" 12 "Level 13" 11 "Level 12" 10 "Level 11" 9 "Level 10" 8 "Level 9" 7 "Level 8" 6 "Level 7" 5 "Level 6" 4 "Level 5" 3 "Level 4" 2 "Level 3" 1 "Level 2" 0 "Level 1" ;
VAL_ 811 CCU_TemperatureGearSts 63 "Invalid" 16 "level 8" 15 "level 7" 14 "level 6" 13 "level 5" 12 "level 4" 11 "level 3" 10 "level 2" 9 "level 1" 8 "level 8" 7 "level 7" 6 "level 6" 5 "level 5" 4 "level 4" 3 "level 3" 2 "level 2" 1 "level 1" 0 "Inactive" ;
VAL_ 811 CCU_BlowMode_Sts 7 "Invalid" 6 "Reserve" 4 "Foot and window" 3 "Foot" 2 "Foot and Face" 1 "Face" 0 "OFF" ;
VAL_ 811 CCU_Circulation_Sts 1 "Internal circulation" 0 "Outer circulation" ;
VAL_ 811 CCU_AC_Req 3 "Invalid" 2 "Reserved" 1 "Requset" 0 "No requset" ;
VAL_ 811 CCU_AC_Sts 1 "ON" 0 "OFF" ;
VAL_ 811 CCU_BlowerLevelSts 8 "level 8" 7 "level 7" 6 "level 6" 5 "level 5" 4 "level 4" 3 "level 3" 2 "level 2" 1 "level 1" 0 "OFF" ;
VAL_ 811 CCU_FrontDefrostSts 1 "On" 0 "Off" ;
VAL_ 811 CCU_PTC_Req 3 "Invalid" 2 "Reserved" 1 "Requset" 0 "No requset" ;
VAL_ 811 CCU_PTC_Temperature 1023 "Invaild" ;
VAL_ 811 CCU_CompSpdMEAS_Comp 8191 "Invalid" ;
VAL_ 811 CCU_PollutionSts 1 "ON" 0 "OFF" ;
VAL_ 811 CCU_ExternalTemperature 255 "Invaild" ;
VAL_ 811 CCU_evaporator_Temperature 31 "Invalid" ;
VAL_ 811 CCU_ExternalTemperatureFailSts 1 "invalid" 0 "valid" ;
VAL_ 1037 USS_WorkSts 0 "Rear PAS Off" 1 "Rear PAS On" ;
VAL_ 1037 USS_FrnSysSts_reserved 0 "Disable" 1 "Enable" 2 "Active" 3 "Failed" ;
VAL_ 1037 USS_RearSysSts_reserved 0 "OFF" 1 "Enable" 2 "Active" 3 "Temporary Fault" 4 "Permanent Fault" ;
VAL_ 1037 USS_SndCadComm 0 "Tone 0 - No warning" 1 "Front Level 1" 2 "Front Level 2" 3 "Front Level 3" 4 "Front Level 4" 5 "Front Level 5" 6 "Rear Level 1" 7 "Rear Level 2" 8 "Rear Level 3" 9 "Rear Level 4" 10 "Rear Level 5" 11 "Rear Level 6" 12 "Tone 10 - PAS & APA Check Normal Warning" 13 "Tone 11 - PAS & APA Check Fault Warning" 14 "Tone 12 - APA Warning tone/ Tone 12 -RRS Warning tone" 15 "Front and Rear Alternate alarm" ;
VAL_ 1037 USS_LFDistance_reserved 0 "No obstacle" 1 "Zone 1" 2 "Zone 2" 3 "Zone3" ;
VAL_ 1037 USS_RFDistance_reserved 0 "No obstacle" 1 "Zone 1" 2 "Zone 2" 3 "Zone3" ;
VAL_ 1037 USS_LRDistance 0 "No obstacle" 1 "Zone 1" 2 "Zone 2" 3 "Zone3" 15 "Invalid" ;
VAL_ 1037 USS_LMRDistance 0 "No obstacle" 1 "Zone 1" 2 "Zone 2" 3 "Zone 3" 4 "Zone 4" 5 "Zone 5" 15 "Invalid" ;
VAL_ 1037 USS_RMRDistance 0 "No obstacle" 1 "Zone 1" 2 "Zone 2" 3 "Zone 3" 4 "Zone 4" 5 "Zone 5" 15 "Invalid" ;
VAL_ 1037 USS_RRDistance 0 "No obstacle" 1 "Zone 1" 2 "Zone 2" 3 "Zone3" 15 "Invalid" ;
VAL_ 1037 USS_PrkAssSysSta 0 "True" 1 "Fault" ;
VAL_ 1037 USS_FLSenSta_reserved 0 " Sensor Normal" 1 " Sensor Fault" ;
VAL_ 1037 USS_FRSenSta_reserved 0 " Sensor Normal" 1 " Sensor Fault" ;
VAL_ 1037 USS_RLSenSta 0 " Sensor Normal" 1 " Sensor Fault" ;
VAL_ 1037 USS_RRSenSta 0 " Sensor Normal" 1 " Sensor Fault" ;
VAL_ 1037 USS_RLMSenSta 0 " Sensor Normal" 1 " Sensor Fault" ;
VAL_ 1037 USS_RRMSenSta 0 " Sensor Normal" 1 " Sensor Fault" ;
VAL_ 1037 USS_SetSta 0 " Unavailable" 1 " Off " 2 " On " 3 " Unused and Reserved" ;
VAL_ 296 Rolling_Counter_0x128 15 "Invalid" ;
VAL_ 296 ADAS_RCTA_IndLeft 0 "Indicator output off" 1 "Indicator On(warning stage - 1)" 2 "Indicator flashing(warning stage - 2)" 3 "Reserved" ;
VAL_ 296 ADAS_RCTA_IndRight 0 "Indicator output off" 1 "Indicator On(warning stage - 1)" 2 "Indicator flashing(warning stage - 2)" 3 "Reserved" ;
VAL_ 296 ADAS_RCTA_SndWarn 0 "Sound Warning disable" 1 "Left Sound Warning enable" 2 "Right Sound Warning enable" 3 "Left and Right Sound Warning enable" ;
VAL_ 296 ADAS_RCTA_check 0 "Available" 1 "Temporarily not available" 2 "Permanently not available" 3 "signal invalid" ;
VAL_ 296 ADAS_RCTA_state 0 "OFF State" 1 "Stand by state" 2 "Armed state" 3 "Warning stage" ;
VAL_ 296 ADAS_RCTA_sens_Feed_Reserved 0 "Early" 1 "Normal" 2 "Late" 3 "signal invalid" ;
VAL_ 296 ADAS_RCTA_Mode_Feed 0 "Off" 1 "On" 2 "Reserved" 3 "signal invalid" ;
VAL_ 307 Rolling_Counter_0x133 15 "Invalid" ;
VAL_ 307 ADAS_BSD_check 0 "Available" 1 "Temporarily not available" 2 "Permanently not available" 3 "signal invalid" ;
VAL_ 307 ADAS_BSD_state 0 "OFF State" 1 "Stand by state" 2 "Armed state" 3 "Warning" ;
VAL_ 307 ADAS_BSD_AudChime_Feed 0 "Off" 1 "On" 2 "Reserved" 3 "signal invalid" ;
VAL_ 307 ADAS_BSD_IndLeft 0 "Indicator output off" 1 "Indicator On(warning stage - 1)" 2 "Indicator flashing(warning stage - 2)" 3 "Sensor Fault" ;
VAL_ 307 ADAS_BSD_IndRight 0 "Indicator output off" 1 "Indicator On(warning stage - 1)" 2 "Indicator flashing(warning stage - 2)" 3 "Sensor Fault" ;
VAL_ 307 ADAS_BSD_SndWarn 0 "Sound Warning disable" 1 "Sound Warning enable" ;
VAL_ 307 ADAS_BSD_Mode_Feed 0 "Off" 1 "On" 2 "Reserved" 3 "signal invalid" ;
VAL_ 307 ADAS_BSD_sens_Feed 0 "Early" 1 "Normal" 2 "Late" 3 "signal invalid" ;
VAL_ 850 Rolling_Counter_0x352 15 "Invalid" ;
VAL_ 850 ADAS_DOW_Warn 0 "No Info" 1 "Left Warning" 2 "Right Warning" 3 "Left & Right Warning" ;
VAL_ 850 ADAS_DOW_SndWarn 0 "Sound Warning disable" 1 "Left Sound Warning enable" 2 "Right Sound Warning enable" 3 "Left and Right Sound Warning enable" ;
VAL_ 850 ADAS_DOW_state 0 "OFF State" 1 "Stand by state" 2 "Armed state" 3 "Warning stage" ;
VAL_ 850 ADAS_DOW_IndLeft 0 "Indicator output off" 1 "Indicator On(warning stage - 1)" 2 "Indicator flashing(warning stage - 2)" 3 "Sensor Fault" ;
VAL_ 850 ADAS_DOW_IndRight 0 "Indicator output off" 1 "Indicator On(warning stage - 1)" 2 "Indicator flashing(warning stage - 2)" 3 "Sensor Fault" ;
VAL_ 850 ADAS_DOW_sens_Feed_Reserved 0 "Early" 1 "Normal" 2 "Late" 3 "signal invalid" ;
VAL_ 850 ADAS_DOW_Mode_Feed 3 "signal invalid" 2 "Reserved" 1 "ON" 0 "OFF" ;
VAL_ 850 ADAS_DOW_AudChime_Feed 0 "Off" 1 "On" 2 "Reserved" 3 "signal invalid" ;
VAL_ 850 ADAS_DOW_check 0 "Available" 1 "Temporarily not available" 2 "Permanently not available" 3 "signal invalid" ;
VAL_ 1216 Rolling_Counter_0x4C0 15 "Invalid" ;
VAL_ 1216 ADAS_Warning_Flag_1 0 "No Error" 1 "Error" ;
VAL_ 1216 ADAS_Warning_Flag_2 0 "No Error" 1 "Error" ;
VAL_ 1216 ADAS_Warning_Flag_3 0 "No Error" 1 "Error" ;
VAL_ 1216 ADAS_Warning_Flag_4 0 "No Error" 1 "Error" ;
VAL_ 1216 ADAS_Warning_Flag_5 0 "No Error" 1 "Error" ;
VAL_ 1216 ADAS_Warning_Flag_6 0 "No Error" 1 "Error" ;
VAL_ 1216 ADAS_Warning_Flag_7 0 "No Error" 1 "Error" ;
VAL_ 1216 ADAS_Warning_Flag_8 0 "No Error" 1 "Error" ;
VAL_ 1216 ADAS_Warning_Flag_9 0 "No Error" 1 "Error" ;
VAL_ 1216 ADAS_Warning_Flag_10 0 "No Error" 1 "Error" ;
VAL_ 1216 ADAS_Warning_Flag_11 0 "No Error" 1 "Error" ;
VAL_ 1216 ADAS_Warning_Flag_12 0 "No Error" 1 "Error" ;
VAL_ 1216 ADAS_Warning_Flag_13 0 "No Error" 1 "Error" ;
VAL_ 1216 ADAS_Warning_Flag_14 0 "No Error" 1 "Error" ;
VAL_ 1216 ADAS_Warning_Flag_15 0 "No Error" 1 "Error" ;
VAL_ 1216 ADAS_Warning_Flag_16 0 "No Error" 1 "Error" ;
VAL_ 1216 ADAS_Warning_Flag_17 0 "No Error" 1 "Error" ;
VAL_ 1216 ADAS_Warning_Flag_18 0 "No Error" 1 "Error" ;
VAL_ 1216 ADAS_Warning_Flag_19 0 "No Error" 1 "Error" ;
VAL_ 1216 ADAS_Warning_Flag_20 0 "No Error" 1 "Error" ;
VAL_ 1216 ADAS_Warning_Flag_21 0 "No Error" 1 "Error" ;
VAL_ 1216 ADAS_Warning_Flag_22 0 "No Error" 1 "Error" ;
VAL_ 1216 ADAS_Warning_Flag_23 0 "No Error" 1 "Error" ;
VAL_ 1216 ADAS_Warning_Flag_24 0 "No Error" 1 "Error" ;
VAL_ 1216 ADAS_Warning_Flag_25 0 "No Error" 1 "Error" ;
VAL_ 1216 ADAS_Warning_Flag_26 0 "No Error" 1 "Error" ;
VAL_ 1216 ADAS_Warning_Flag_27 0 "No Error" 1 "Error" ;
VAL_ 1216 ADAS_Warning_Flag_28 0 "No Error" 1 "Error" ;
VAL_ 851 Rolling_Counter_0x353 15 "Invalid" ;
VAL_ 851 ADAS_RadarRight_Cal_Status 0 "No Calib" 1 "Calib OK" ;
VAL_ 851 ADAS_RadarLeft_Cal_Status 0 "No Calib" 1 "Calib OK" ;
VAL_ 851 ADAS_RadarRight_DynaCal_Status 0 "In Calibrating" 1 "The absolute value of calibration angle is greater than 6 degrees" ;
VAL_ 851 ADAS_RadarLeft_DynaCal_Status 0 "In Calibrating" 1 "The absolute value of calibration angle is greater than 6 degrees" ;
VAL_ 851 ADAS_MasterSRR_check 0 "Available" 1 "Temporarily not available" 2 "Permanently not available" ;
VAL_ 851 ADAS_SlaveSRR_check 0 "Available" 1 "Temporarily not available" 2 "Permanently not available" ;
VAL_ 851 ADAS_CalSensorMasterProgress 255 "Invaild" ;
VAL_ 851 ADAS_CalSensorSlaverProgress 255 "Invalid" ;
VAL_ 133 Rolling_Counter_0x85 15 "Invalid" ;
VAL_ 133 ACM_Crash_Sts 3 "Invalid Value" 2 "Invalid Value" 1 "Crash_Detected" 0 "No_Event" ;
VAL_ 133 ACM_Airbag_Deployment_Status 3 "Invalid Value" 2 "Invalid Value" 1 "Airbag_Deployment" 0 "No_Airbag_Deployment" ;
VAL_ 133 ACM_Crash_Intensity 7 "Invalid_Value" 6 "Invalid_Value" 5 "Invalid_Value" 4 "Invalid_Value" 3 "Crash_Intensity_3" 2 "Crash_Intensity_2" 1 "Crash_Intensity_1" 0 "No_Crash" ;
VAL_ 133 ACM_Front_Crash 3 "Invalid Value" 2 "Invalid Value" 1 "Front_Crash_Detected" 0 "No_Event" ;
VAL_ 133 ACM_DriverSide_Crash 3 "Invalid Value" 2 "Invalid Value" 1 "Driverside_Crash_Detected" 0 "No_Event" ;
VAL_ 133 ACM_PassSide_Crash 3 "Invalid Value" 2 "Invalid Value" 1 "PassSide_Crash_Detected" 0 "No_Event" ;
VAL_ 133 ACM_Rear_Crash 3 "Invalid Value" 2 "Invalid Value" 1 "Rear_Crash_Detected" 0 "No_Event" ;
VAL_ 133 ACM_Rollover_Crash 3 "Invalid Value" 2 "Invalid Value" 1 "Rollover_Crash_Detected" 0 "No_Event" ;
VAL_ 897 Rolling_Counter_0x381 15 "Invalid" ;
VAL_ 897 ACM_Seat_Occupancy_Passenger 3 "Failure" 2 "Not_Available" 1 "Seat Occupied" 0 "Seat_Not_Occupied" ;
VAL_ 897 ACM_Seat_Occupancy_2nd_Row_Dri_r 3 "Failure" 2 "Not_Available" 1 "Seat Occupied" 0 "Seat_Not_Occupied" ;
VAL_ 897 ACM_Seat_Occupancy_2nd_Row_Pas_r 3 "Failure" 2 "Not_Available" 1 "Seat Occupied" 0 "Seat_Not_Occupied" ;
VAL_ 897 ACM_Seat_Occupancy_2nd_Row_Mid_r 3 "Failure" 2 "Not_Available" 1 "Seat Occupied" 0 "Seat_Not_Occupied" ;
VAL_ 897 ACM_Seat_Belt_Status_Passenger 3 "Failure" 2 "Not_Available" 1 "Buckled" 0 "Not_buckled" ;
VAL_ 897 ACM_Seat_Belt_Status_Driver 3 "Failure" 2 "Not_Available" 1 "Buckled" 0 "Not_buckled" ;
VAL_ 897 ACM_Seat_Belt_Status_2nd_Row_Dri 3 "Failure" 2 "Not_Available" 1 "Buckled" 0 "Not_buckled" ;
VAL_ 897 ACM_Seat_Belt_Status_2nd_Row_Mid 3 "Failure" 2 "Not_Available" 1 "Buckled" 0 "Not_buckled" ;
VAL_ 897 ACM_Seat_Belt_Status_2nd_Row_Pas 3 "Failure" 2 "Not_Available" 1 "Buckled" 0 "Not_buckled" ;
VAL_ 897 ACM_Seat_Belt_Status_3rd_Row_Dri 3 "Failure" 2 "Not_Available" 1 "Buckled" 0 "Not_buckled" ;
VAL_ 897 ACM_Seat_Belt_Status_3rd_Row_Pas 3 "Failure" 2 "Not_Available" 1 "Buckled" 0 "Not_buckled" ;
VAL_ 1160 Rolling_Counter_0x488 15 "Invalid" ;
VAL_ 1160 ACM_Malfunction 0 "ACM_Failure" 1 "ACM_Normal_Operation" ;
VAL_ 1160 ACM_Pre_Drive_Check 0 "ACM_Pre_Drive_Check" 1 "ACM_Normal_Operation" ;
VAL_ 1160 ACM_in_Plant_Mode 0 "ACM_in_Plant_Mode" 1 "ACM_in_Normal_Mode" ;
VAL_ 1160 ACM_PAB_Suppression 0 "Not_Suppressed" 1 "Suppressed" 2 "Function Failure" 3 "Invalid_Value" ;
VAL_ 1160 ACM_Airbag_Disabled 0 "ACM_AirBag_Disabled" 1 "ACM_Normal_Operation" ;
VAL_ 1160 ACM_Development_Calibration 0 "ACM_Dev_Calibrated" 1 "ACM_Normal_Operation" ;
VAL_ 1160 ACM_In_Disposal_Mode 0 "ACM_In_Disposal_Mode" 1 "ACM_Normal_Operation" ;
VAL_ 1160 ACM_Seatbelt_Reminder_Request 0 "Seatbelt reminder NOT activated" 1 "Seatbelt reminder activated" ;
VAL_ 1160 ACM_SBR_Chime_Req 0 "No Active Chime" 1 "Active Chime" ;
VAL_ 1160 ACM_SBR_Blinking_Req 0 "No Blinking" 1 "Blinking 1Hz" ;
